VERSION "HNNBNNNYNNNNNNNNNNNNNNNNNNNNNNNNNNNNNNNNNN/4/%%%/4/'%**4NNN///"

NS_ :

BS_:

BU_: AFS AFS_LMod_L AFS_LMod_R BCM1 BVS FCM GLW_LMod_L GLW_LMod_R LCM_L LCM_R LED_DK3_LM_L LED_DK3_LM_R LED_LM_L LED_LM_R LLP_L LLP_R LWR_MXB_L LWR_MXB_R MXB MXB_LM_L MXB_LM_R ZFAS

BO_ 1342 LED_Feh_LM_L_01: 8 LED_LM_L
 SG_ LED_L_Abbiegel_Def_1 : 0|1@1+ (1,0) [0|1] ""  AFS,BCM1,FCM,MXB
 SG_ LED_L_Abbiegel_Def_2 : 1|1@1+ (1,0) [0|1] ""  AFS,BCM1,FCM,MXB
 SG_ LED_L_Abbiegel_Def_3 : 2|1@1+ (1,0) [0|1] ""  AFS,BCM1,FCM,MXB
 SG_ LED_L_Abbiegel_Def_4 : 3|1@1+ (1,0) [0|1] ""  AFS,BCM1,FCM,MXB
 SG_ LED_L_Abbiegel_Def_5 : 4|1@1+ (1,0) [0|1] ""  AFS,BCM1,FCM,MXB
 SG_ LED_L_Abbiegel_Def_6 : 5|1@1+ (1,0) [0|1] ""  AFS,BCM1,FCM,MXB
 SG_ LED_L_Abbiegel_Def_7 : 6|1@1+ (1,0) [0|1] ""  AFS,BCM1,FCM,MXB
 SG_ LED_L_Abbiegel_Def_Err_Gultig : 7|1@1+ (1,0) [0|1] ""  AFS,BCM1,FCM,MXB
 SG_ LED_L_Abblendl_Def_1 : 8|1@1+ (1,0) [0|1] ""  AFS,BCM1,FCM,MXB
 SG_ LED_L_Abblendl_Def_2 : 9|1@1+ (1,0) [0|1] ""  AFS,BCM1,FCM,MXB
 SG_ LED_L_Abblendl_Def_3 : 10|1@1+ (1,0) [0|1] ""  AFS,BCM1,FCM,MXB
 SG_ LED_L_Abblendl_Def_4 : 11|1@1+ (1,0) [0|1] ""  AFS,BCM1,FCM,MXB
 SG_ LED_L_Abblendl_Def_5 : 12|1@1+ (1,0) [0|1] ""  AFS,BCM1,FCM,MXB
 SG_ LED_L_Abblendl_Def_6 : 13|1@1+ (1,0) [0|1] ""  AFS,BCM1,FCM,MXB
 SG_ LED_L_Abblendl_Def_7 : 14|1@1+ (1,0) [0|1] ""  AFS,BCM1,FCM,MXB
 SG_ LED_L_Abblendl_Def_Err_Gultig : 15|1@1+ (1,0) [0|1] ""  AFS,BCM1,FCM,MXB
 SG_ LED_L_Fernl_Def_1 : 16|1@1+ (1,0) [0|1] ""  AFS,BCM1,FCM,MXB
 SG_ LED_L_Fernl_Def_2 : 17|1@1+ (1,0) [0|1] ""  AFS,BCM1,FCM,MXB
 SG_ LED_L_Fernl_Def_3 : 18|1@1+ (1,0) [0|1] ""  AFS,BCM1,FCM,MXB
 SG_ LED_L_Fernl_Def_4 : 19|1@1+ (1,0) [0|1] ""  AFS,BCM1,FCM,MXB
 SG_ LED_L_Fernl_Def_5 : 20|1@1+ (1,0) [0|1] ""  AFS,BCM1,FCM,MXB
 SG_ LED_L_Fernl_Def_6 : 21|1@1+ (1,0) [0|1] ""  AFS,BCM1,FCM,MXB
 SG_ LED_L_Fernl_Def_7 : 22|1@1+ (1,0) [0|1] ""  AFS,BCM1,FCM,MXB
 SG_ LED_L_Fernl_Def_Err_Gultig : 23|1@1+ (1,0) [0|1] ""  AFS,BCM1,FCM,MXB
 SG_ LED_L_TFL_Def_1 : 24|1@1+ (1,0) [0|1] ""  AFS,BCM1,FCM,MXB
 SG_ LED_L_TFL_Def_2 : 25|1@1+ (1,0) [0|1] ""  AFS,BCM1,FCM,MXB
 SG_ LED_L_TFL_Def_3 : 26|1@1+ (1,0) [0|1] ""  AFS,BCM1,FCM,MXB
 SG_ LED_L_TFL_Def_4 : 27|1@1+ (1,0) [0|1] ""  AFS,BCM1,FCM,MXB
 SG_ LED_L_TFL_Def_5 : 28|1@1+ (1,0) [0|1] ""  AFS,BCM1,FCM,MXB
 SG_ LED_L_TFL_Def_6 : 29|1@1+ (1,0) [0|1] ""  AFS,BCM1,FCM,MXB
 SG_ LED_L_TFL_Def_7 : 30|1@1+ (1,0) [0|1] ""  AFS,BCM1,FCM,MXB
 SG_ LED_L_TFL_Def_Err_Gultig : 31|1@1+ (1,0) [0|1] ""  AFS,BCM1,FCM,MXB
 SG_ LED_L_Allg_Elektr_Def_1 : 32|1@1+ (1,0) [0|1] ""  AFS,BCM1,FCM,MXB
 SG_ LED_L_Allg_Elektr_Def_2 : 33|1@1+ (1,0) [0|1] ""  AFS,BCM1,FCM,MXB
 SG_ LED_L_Allg_Elektr_Def_3 : 34|1@1+ (1,0) [0|1] ""  AFS,BCM1,FCM,MXB
 SG_ LED_L_Allg_Elektr_Def_4 : 35|1@1+ (1,0) [0|1] ""  AFS,BCM1,FCM,MXB
 SG_ LED_L_Allg_Elektr_Def_5 : 36|1@1+ (1,0) [0|1] ""  AFS,BCM1,FCM,MXB
 SG_ LED_L_Allg_Elektr_Def_6 : 37|1@1+ (1,0) [0|1] ""  AFS,BCM1,FCM,MXB
 SG_ LED_L_Allg_Elektr_Def_7 : 38|1@1+ (1,0) [0|1] ""  AFS,BCM1,FCM,MXB
 SG_ LED_L_Allg_Elektr_Def_8 : 39|1@1+ (1,0) [0|1] ""  AFS,BCM1,FCM,MXB
 SG_ LED_L_Allg_Elektr_Def_Err_Gultig : 40|1@1+ (1,0) [0|1] ""  AFS,BCM1,FCM,MXB
 SG_ LED_L_Luefter_1_Def_1 : 48|1@1+ (1,0) [0|1] ""  AFS,BCM1,FCM,MXB
 SG_ LED_L_Luefter_1_Def_2 : 49|1@1+ (1,0) [0|1] ""  AFS,BCM1,FCM,MXB
 SG_ LED_L_Luefter_1_Def_3 : 50|1@1+ (1,0) [0|1] ""  AFS,BCM1,FCM,MXB
 SG_ LED_L_Luefter_1_Def_4 : 51|1@1+ (1,0) [0|1] ""  AFS,BCM1,FCM,MXB
 SG_ LED_L_Luefter_2_Def_1 : 52|1@1+ (1,0) [0|1] ""  AFS,BCM1,FCM,MXB
 SG_ LED_L_Luefter_2_Def_2 : 53|1@1+ (1,0) [0|1] ""  AFS,BCM1,FCM,MXB
 SG_ LED_L_Luefter_2_Def_3 : 54|1@1+ (1,0) [0|1] ""  AFS,BCM1,FCM,MXB
 SG_ LED_L_Luefter_2_Def_4 : 55|1@1+ (1,0) [0|1] ""  AFS,BCM1,FCM,MXB
 SG_ LED_L_Luefter_1_Def_Err_Gultig : 56|1@1+ (1,0) [0|1] ""  AFS,BCM1,FCM,MXB
 SG_ LED_L_Luefter_2_Def_Err_Gultig : 57|1@1+ (1,0) [0|1] ""  AFS,BCM1,FCM,MXB
 SG_ LED_L_ECE_SAE_Umschaltung_Def : 63|1@1+ (1,0) [0|1] ""  AFS,BCM1,FCM,MXB

BO_ 2527679494 LED_Feh_LM_L_02: 8 LED_LM_L
 SG_ LED_L_Nebel_All_Def_1 : 0|1@1+ (1,0) [0|1] ""  AFS,BCM1,FCM,MXB
 SG_ LED_L_Nebel_All_Def_2 : 1|1@1+ (1,0) [0|1] ""  AFS,BCM1,FCM,MXB
 SG_ LED_L_Nebel_All_Def_3 : 2|1@1+ (1,0) [0|1] ""  AFS,BCM1,FCM,MXB
 SG_ LED_L_Nebel_All_Def_4 : 3|1@1+ (1,0) [0|1] ""  AFS,BCM1,FCM,MXB
 SG_ LED_L_Nebel_All_Def_5 : 4|1@1+ (1,0) [0|1] ""  AFS,BCM1,FCM,MXB
 SG_ LED_L_Nebel_All_Def_6 : 5|1@1+ (1,0) [0|1] ""  AFS,BCM1,FCM,MXB
 SG_ LED_L_Nebel_All_Def_7 : 6|1@1+ (1,0) [0|1] ""  AFS,BCM1,FCM,MXB
 SG_ LED_L_Nebel_All_Def_Err_Gultig : 7|1@1+ (1,0) [0|1] ""  AFS,BCM1,FCM,MXB
 SG_ LED_L_Touristenl_Def_1 : 8|1@1+ (1,0) [0|1] ""  AFS,BCM1,FCM,MXB
 SG_ LED_L_Touristenl_Def_2 : 9|1@1+ (1,0) [0|1] ""  AFS,BCM1,FCM,MXB
 SG_ LED_L_Touristenl_Def_3 : 10|1@1+ (1,0) [0|1] ""  AFS,BCM1,FCM,MXB
 SG_ LED_L_Touristenl_Def_4 : 11|1@1+ (1,0) [0|1] ""  AFS,BCM1,FCM,MXB
 SG_ LED_L_Touristenl_Def_5 : 12|1@1+ (1,0) [0|1] ""  AFS,BCM1,FCM,MXB
 SG_ LED_L_Touristenl_Def_6 : 13|1@1+ (1,0) [0|1] ""  AFS,BCM1,FCM,MXB
 SG_ LED_L_Touristenl_Def_7 : 14|1@1+ (1,0) [0|1] ""  AFS,BCM1,FCM,MXB
 SG_ LED_L_Touristenl_Def_Err_Gultig : 15|1@1+ (1,0) [0|1] ""  AFS,BCM1,FCM,MXB
 SG_ LED_L_Autobahnl_Def_1 : 16|1@1+ (1,0) [0|1] ""  AFS,BCM1,FCM,MXB
 SG_ LED_L_Autobahnl_Def_2 : 17|1@1+ (1,0) [0|1] ""  AFS,BCM1,FCM,MXB
 SG_ LED_L_Autobahnl_Def_3 : 18|1@1+ (1,0) [0|1] ""  AFS,BCM1,FCM,MXB
 SG_ LED_L_Autobahnl_Def_4 : 19|1@1+ (1,0) [0|1] ""  AFS,BCM1,FCM,MXB
 SG_ LED_L_Autobahnl_Def_5 : 20|1@1+ (1,0) [0|1] ""  AFS,BCM1,FCM,MXB
 SG_ LED_L_Autobahnl_Def_6 : 21|1@1+ (1,0) [0|1] ""  AFS,BCM1,FCM,MXB
 SG_ LED_L_Autobahnl_Def_7 : 22|1@1+ (1,0) [0|1] ""  AFS,BCM1,FCM,MXB
 SG_ LED_L_Autobahnl_Def_Err_Gultig : 23|1@1+ (1,0) [0|1] ""  AFS,BCM1,FCM,MXB
 SG_ LED_L_Rennl_Def_1 : 24|1@1+ (1,0) [0|1] ""  AFS,BCM1,FCM,MXB
 SG_ LED_L_Rennl_Def_2 : 25|1@1+ (1,0) [0|1] ""  AFS,BCM1,FCM,MXB
 SG_ LED_L_Rennl_Def_3 : 26|1@1+ (1,0) [0|1] ""  AFS,BCM1,FCM,MXB
 SG_ LED_L_Rennl_Def_4 : 27|1@1+ (1,0) [0|1] ""  AFS,BCM1,FCM,MXB
 SG_ LED_L_Rennl_Def_5 : 28|1@1+ (1,0) [0|1] ""  AFS,BCM1,FCM,MXB
 SG_ LED_L_Rennl_Def_6 : 29|1@1+ (1,0) [0|1] ""  AFS,BCM1,FCM,MXB
 SG_ LED_L_Rennl_Def_7 : 30|1@1+ (1,0) [0|1] ""  AFS,BCM1,FCM,MXB
 SG_ LED_L_Rennl_Def_Err_Gultig : 31|1@1+ (1,0) [0|1] ""  AFS,BCM1,FCM,MXB
 SG_ LED_L_Stadtl_Def_1 : 32|1@1+ (1,0) [0|1] ""  AFS,BCM1,FCM,MXB
 SG_ LED_L_Stadtl_Def_2 : 33|1@1+ (1,0) [0|1] ""  AFS,BCM1,FCM,MXB
 SG_ LED_L_Stadtl_Def_3 : 34|1@1+ (1,0) [0|1] ""  AFS,BCM1,FCM,MXB
 SG_ LED_L_Stadtl_Def_4 : 35|1@1+ (1,0) [0|1] ""  AFS,BCM1,FCM,MXB
 SG_ LED_L_Stadtl_Def_5 : 36|1@1+ (1,0) [0|1] ""  AFS,BCM1,FCM,MXB
 SG_ LED_L_Stadtl_Def_6 : 37|1@1+ (1,0) [0|1] ""  AFS,BCM1,FCM,MXB
 SG_ LED_L_Stadtl_Def_7 : 38|1@1+ (1,0) [0|1] ""  AFS,BCM1,FCM,MXB
 SG_ LED_L_Stadtl_Def_Err_Gultig : 39|1@1+ (1,0) [0|1] ""  AFS,BCM1,FCM,MXB

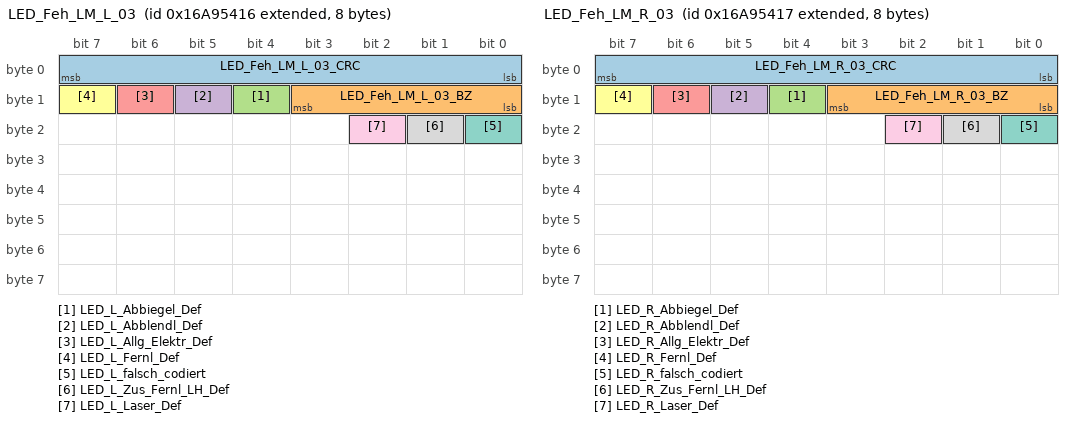
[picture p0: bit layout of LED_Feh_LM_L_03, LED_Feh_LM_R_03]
BO_ 2527679510 LED_Feh_LM_L_03: 8 LED_DK3_LM_L
 SG_ LED_Feh_LM_L_03_CRC : 0|8@1+ (1,0) [0|255] "" Vector__XXX
 SG_ LED_Feh_LM_L_03_BZ : 8|4@1+ (1,0) [0|15] "" Vector__XXX
 SG_ LED_L_Abbiegel_Def : 12|1@1+ (1,0) [0|1] ""  AFS,BCM1,FCM,MXB
 SG_ LED_L_Abblendl_Def : 13|1@1+ (1,0) [0|1] ""  AFS,BCM1,FCM,LCM_L,MXB
 SG_ LED_L_Allg_Elektr_Def : 14|1@1+ (1,0) [0|1] ""  AFS,BCM1,FCM,MXB
 SG_ LED_L_Fernl_Def : 15|1@1+ (1,0) [0|1] ""  AFS,BCM1,FCM,MXB
 SG_ LED_L_falsch_codiert : 16|1@1+ (1,0) [0|1] ""  AFS,BCM1,BVS,FCM,MXB,ZFAS
 SG_ LED_L_Zus_Fernl_LH_Def : 17|1@1+ (1,0) [0|1] ""  AFS,BCM1,FCM
 SG_ LED_L_Laser_Def : 18|1@1+ (1,0) [0|1] ""  AFS,BCM1,FCM

BO_ 1341 LED_Feh_LM_R_01: 8 LED_LM_R
 SG_ LED_R_Abbiegel_Def_1 : 0|1@1+ (1,0) [0|1] ""  AFS,BCM1,FCM,MXB
 SG_ LED_R_Abbiegel_Def_2 : 1|1@1+ (1,0) [0|1] ""  AFS,BCM1,FCM,MXB
 SG_ LED_R_Abbiegel_Def_3 : 2|1@1+ (1,0) [0|1] ""  AFS,BCM1,FCM,MXB
 SG_ LED_R_Abbiegel_Def_4 : 3|1@1+ (1,0) [0|1] ""  AFS,BCM1,FCM,MXB
 SG_ LED_R_Abbiegel_Def_5 : 4|1@1+ (1,0) [0|1] ""  AFS,BCM1,FCM,MXB
 SG_ LED_R_Abbiegel_Def_6 : 5|1@1+ (1,0) [0|1] ""  AFS,BCM1,FCM,MXB
 SG_ LED_R_Abbiegel_Def_7 : 6|1@1+ (1,0) [0|1] ""  AFS,BCM1,FCM,MXB
 SG_ LED_R_Abbiegel_Def_Err_Gultig : 7|1@1+ (1,0) [0|1] ""  AFS,BCM1,FCM,MXB
 SG_ LED_R_Abblendl_Def_1 : 8|1@1+ (1,0) [0|1] ""  AFS,BCM1,FCM,MXB
 SG_ LED_R_Abblendl_Def_2 : 9|1@1+ (1,0) [0|1] ""  AFS,BCM1,FCM,MXB
 SG_ LED_R_Abblendl_Def_3 : 10|1@1+ (1,0) [0|1] ""  AFS,BCM1,FCM,MXB
 SG_ LED_R_Abblendl_Def_4 : 11|1@1+ (1,0) [0|1] ""  AFS,BCM1,FCM,MXB
 SG_ LED_R_Abblendl_Def_5 : 12|1@1+ (1,0) [0|1] ""  AFS,BCM1,FCM,MXB
 SG_ LED_R_Abblendl_Def_6 : 13|1@1+ (1,0) [0|1] ""  AFS,BCM1,FCM,MXB
 SG_ LED_R_Abblendl_Def_7 : 14|1@1+ (1,0) [0|1] ""  AFS,BCM1,FCM,MXB
 SG_ LED_R_Abblendl_Def_Err_Gultig : 15|1@1+ (1,0) [0|1] ""  AFS,BCM1,FCM,MXB
 SG_ LED_R_Fernl_Def_1 : 16|1@1+ (1,0) [0|1] ""  AFS,BCM1,FCM,MXB
 SG_ LED_R_Fernl_Def_2 : 17|1@1+ (1,0) [0|1] ""  AFS,BCM1,FCM,MXB
 SG_ LED_R_Fernl_Def_3 : 18|1@1+ (1,0) [0|1] ""  AFS,BCM1,FCM,MXB
 SG_ LED_R_Fernl_Def_4 : 19|1@1+ (1,0) [0|1] ""  AFS,BCM1,FCM,MXB
 SG_ LED_R_Fernl_Def_5 : 20|1@1+ (1,0) [0|1] ""  AFS,BCM1,FCM,MXB
 SG_ LED_R_Fernl_Def_6 : 21|1@1+ (1,0) [0|1] ""  AFS,BCM1,FCM,MXB
 SG_ LED_R_Fernl_Def_7 : 22|1@1+ (1,0) [0|1] ""  AFS,BCM1,FCM,MXB
 SG_ LED_R_Fernl_Def_Err_Gultig : 23|1@1+ (1,0) [0|1] ""  AFS,BCM1,FCM,MXB
 SG_ LED_R_TFL_Def_1 : 24|1@1+ (1,0) [0|1] ""  AFS,BCM1,FCM,MXB
 SG_ LED_R_TFL_Def_2 : 25|1@1+ (1,0) [0|1] ""  AFS,BCM1,FCM,MXB
 SG_ LED_R_TFL_Def_3 : 26|1@1+ (1,0) [0|1] ""  AFS,BCM1,FCM,MXB
 SG_ LED_R_TFL_Def_4 : 27|1@1+ (1,0) [0|1] ""  AFS,BCM1,FCM,MXB
 SG_ LED_R_TFL_Def_5 : 28|1@1+ (1,0) [0|1] ""  AFS,BCM1,FCM,MXB
 SG_ LED_R_TFL_Def_6 : 29|1@1+ (1,0) [0|1] ""  AFS,BCM1,FCM,MXB
 SG_ LED_R_TFL_Def_7 : 30|1@1+ (1,0) [0|1] ""  AFS,BCM1,FCM,MXB
 SG_ LED_R_TFL_Def_Err_Gultig : 31|1@1+ (1,0) [0|1] ""  AFS,BCM1,FCM,MXB
 SG_ LED_R_Allg_Elektr_Def_1 : 32|1@1+ (1,0) [0|1] ""  AFS,BCM1,FCM,MXB
 SG_ LED_R_Allg_Elektr_Def_2 : 33|1@1+ (1,0) [0|1] ""  AFS,BCM1,FCM,MXB
 SG_ LED_R_Allg_Elektr_Def_3 : 34|1@1+ (1,0) [0|1] ""  AFS,BCM1,FCM,MXB
 SG_ LED_R_Allg_Elektr_Def_4 : 35|1@1+ (1,0) [0|1] ""  AFS,BCM1,FCM,MXB
 SG_ LED_R_Allg_Elektr_Def_5 : 36|1@1+ (1,0) [0|1] ""  AFS,BCM1,FCM,MXB
 SG_ LED_R_Allg_Elektr_Def_6 : 37|1@1+ (1,0) [0|1] ""  AFS,BCM1,FCM,MXB
 SG_ LED_R_Allg_Elektr_Def_7 : 38|1@1+ (1,0) [0|1] ""  AFS,BCM1,FCM,MXB
 SG_ LED_R_Allg_Elektr_Def_8 : 39|1@1+ (1,0) [0|1] ""  AFS,BCM1,FCM,MXB
 SG_ LED_R_Allg_Elektr_Def_Err_Gultig : 40|1@1+ (1,0) [0|1] ""  AFS,BCM1,FCM,MXB
 SG_ LED_R_Luefter_1_Def_1 : 48|1@1+ (1,0) [0|1] ""  AFS,BCM1,FCM,MXB
 SG_ LED_R_Luefter_1_Def_2 : 49|1@1+ (1,0) [0|1] ""  AFS,BCM1,FCM,MXB
 SG_ LED_R_Luefter_1_Def_3 : 50|1@1+ (1,0) [0|1] ""  AFS,BCM1,FCM,MXB
 SG_ LED_R_Luefter_1_Def_4 : 51|1@1+ (1,0) [0|1] ""  AFS,BCM1,FCM,MXB
 SG_ LED_R_Luefter_2_Def_1 : 52|1@1+ (1,0) [0|1] ""  AFS,BCM1,FCM,MXB
 SG_ LED_R_Luefter_2_Def_2 : 53|1@1+ (1,0) [0|1] ""  AFS,BCM1,FCM,MXB
 SG_ LED_R_Luefter_2_Def_3 : 54|1@1+ (1,0) [0|1] ""  AFS,BCM1,FCM,MXB
 SG_ LED_R_Luefter_2_Def_4 : 55|1@1+ (1,0) [0|1] ""  AFS,BCM1,FCM,MXB
 SG_ LED_R_Luefter_1_Def_Err_Gultig : 56|1@1+ (1,0) [0|1] ""  AFS,BCM1,FCM,MXB
 SG_ LED_R_Luefter_2_Def_Err_Gultig : 57|1@1+ (1,0) [0|1] ""  AFS,BCM1,FCM,MXB
 SG_ LED_R_ECE_SAE_Umschaltung_Def : 63|1@1+ (1,0) [0|1] ""  AFS,BCM1,FCM,MXB

BO_ 2527679495 LED_Feh_LM_R_02: 8 LED_LM_R
 SG_ LED_R_Nebel_All_Def_1 : 0|1@1+ (1,0) [0|1] ""  AFS,BCM1,FCM,MXB
 SG_ LED_R_Nebel_All_Def_2 : 1|1@1+ (1,0) [0|1] ""  AFS,BCM1,FCM,MXB
 SG_ LED_R_Nebel_All_Def_3 : 2|1@1+ (1,0) [0|1] ""  AFS,BCM1,FCM,MXB
 SG_ LED_R_Nebel_All_Def_4 : 3|1@1+ (1,0) [0|1] ""  AFS,BCM1,FCM,MXB
 SG_ LED_R_Nebel_All_Def_5 : 4|1@1+ (1,0) [0|1] ""  AFS,BCM1,FCM,MXB
 SG_ LED_R_Nebel_All_Def_6 : 5|1@1+ (1,0) [0|1] ""  AFS,BCM1,FCM,MXB
 SG_ LED_R_Nebel_All_Def_7 : 6|1@1+ (1,0) [0|1] ""  AFS,BCM1,FCM,MXB
 SG_ LED_R_Nebel_All_Def_Err_Gultig : 7|1@1+ (1,0) [0|1] ""  AFS,BCM1,FCM,MXB
 SG_ LED_R_Touristenl_Def_1 : 8|1@1+ (1,0) [0|1] ""  AFS,BCM1,FCM,MXB
 SG_ LED_R_Touristenl_Def_2 : 9|1@1+ (1,0) [0|1] ""  AFS,BCM1,FCM,MXB
 SG_ LED_R_Touristenl_Def_3 : 10|1@1+ (1,0) [0|1] ""  AFS,BCM1,FCM,MXB
 SG_ LED_R_Touristenl_Def_4 : 11|1@1+ (1,0) [0|1] ""  AFS,BCM1,FCM,MXB
 SG_ LED_R_Touristenl_Def_5 : 12|1@1+ (1,0) [0|1] ""  AFS,BCM1,FCM,MXB
 SG_ LED_R_Touristenl_Def_6 : 13|1@1+ (1,0) [0|1] ""  AFS,BCM1,FCM,MXB
 SG_ LED_R_Touristenl_Def_7 : 14|1@1+ (1,0) [0|1] ""  AFS,BCM1,FCM,MXB
 SG_ LED_R_Touristenl_Def_Err_Gultig : 15|1@1+ (1,0) [0|1] ""  AFS,BCM1,FCM,MXB
 SG_ LED_R_Autobahnl_Def_1 : 16|1@1+ (1,0) [0|1] ""  AFS,BCM1,FCM,MXB
 SG_ LED_R_Autobahnl_Def_2 : 17|1@1+ (1,0) [0|1] ""  AFS,BCM1,FCM,MXB
 SG_ LED_R_Autobahnl_Def_3 : 18|1@1+ (1,0) [0|1] ""  AFS,BCM1,FCM,MXB
 SG_ LED_R_Autobahnl_Def_4 : 19|1@1+ (1,0) [0|1] ""  AFS,BCM1,FCM,MXB
 SG_ LED_R_Autobahnl_Def_5 : 20|1@1+ (1,0) [0|1] ""  AFS,BCM1,FCM,MXB
 SG_ LED_R_Autobahnl_Def_6 : 21|1@1+ (1,0) [0|1] ""  AFS,BCM1,FCM,MXB
 SG_ LED_R_Autobahnl_Def_7 : 22|1@1+ (1,0) [0|1] ""  AFS,BCM1,FCM,MXB
 SG_ LED_R_Autobahnl_Def_Err_Gultig : 23|1@1+ (1,0) [0|1] ""  AFS,BCM1,FCM,MXB
 SG_ LED_R_Rennl_Def_1 : 24|1@1+ (1,0) [0|1] ""  AFS,BCM1,FCM,MXB
 SG_ LED_R_Rennl_Def_2 : 25|1@1+ (1,0) [0|1] ""  AFS,BCM1,FCM,MXB
 SG_ LED_R_Rennl_Def_3 : 26|1@1+ (1,0) [0|1] ""  AFS,BCM1,FCM,MXB
 SG_ LED_R_Rennl_Def_4 : 27|1@1+ (1,0) [0|1] ""  AFS,BCM1,FCM,MXB
 SG_ LED_R_Rennl_Def_5 : 28|1@1+ (1,0) [0|1] ""  AFS,BCM1,FCM,MXB
 SG_ LED_R_Rennl_Def_6 : 29|1@1+ (1,0) [0|1] ""  AFS,BCM1,FCM,MXB
 SG_ LED_R_Rennl_Def_7 : 30|1@1+ (1,0) [0|1] ""  AFS,BCM1,FCM,MXB
 SG_ LED_R_Rennl_Def_Err_Gultig : 31|1@1+ (1,0) [0|1] ""  AFS,BCM1,FCM,MXB
 SG_ LED_R_Stadtl_Def_1 : 32|1@1+ (1,0) [0|1] ""  AFS,BCM1,FCM,MXB
 SG_ LED_R_Stadtl_Def_2 : 33|1@1+ (1,0) [0|1] ""  AFS,BCM1,FCM,MXB
 SG_ LED_R_Stadtl_Def_3 : 34|1@1+ (1,0) [0|1] ""  AFS,BCM1,FCM,MXB
 SG_ LED_R_Stadtl_Def_4 : 35|1@1+ (1,0) [0|1] ""  AFS,BCM1,FCM,MXB
 SG_ LED_R_Stadtl_Def_5 : 36|1@1+ (1,0) [0|1] ""  AFS,BCM1,FCM,MXB
 SG_ LED_R_Stadtl_Def_6 : 37|1@1+ (1,0) [0|1] ""  AFS,BCM1,FCM,MXB
 SG_ LED_R_Stadtl_Def_7 : 38|1@1+ (1,0) [0|1] ""  AFS,BCM1,FCM,MXB
 SG_ LED_R_Stadtl_Def_Err_Gultig : 39|1@1+ (1,0) [0|1] ""  AFS,BCM1,FCM,MXB

BO_ 2527679511 LED_Feh_LM_R_03: 8 LED_DK3_LM_R
 SG_ LED_Feh_LM_R_03_CRC : 0|8@1+ (1,0) [0|255] "" Vector__XXX
 SG_ LED_Feh_LM_R_03_BZ : 8|4@1+ (1,0) [0|15] "" Vector__XXX
 SG_ LED_R_Abbiegel_Def : 12|1@1+ (1,0) [0|1] ""  AFS,BCM1,FCM,MXB
 SG_ LED_R_Abblendl_Def : 13|1@1+ (1,0) [0|1] ""  AFS,BCM1,FCM,LCM_R,MXB
 SG_ LED_R_Allg_Elektr_Def : 14|1@1+ (1,0) [0|1] ""  AFS,BCM1,FCM,MXB
 SG_ LED_R_Fernl_Def : 15|1@1+ (1,0) [0|1] ""  AFS,BCM1,FCM,MXB
 SG_ LED_R_falsch_codiert : 16|1@1+ (1,0) [0|1] ""  AFS,BCM1,BVS,FCM,MXB,ZFAS
 SG_ LED_R_Zus_Fernl_LH_Def : 17|1@1+ (1,0) [0|1] ""  AFS,BCM1,FCM
 SG_ LED_R_Laser_Def : 18|1@1+ (1,0) [0|1] ""  AFS,BCM1,FCM

BO_ 1422 LED_Idt_LM_L: 8 LED_LM_L
 SG_ LED_L_Mux M : 0|8@1+ (1,0) [0|4] ""  AFS,BCM1,FCM,MXB
 SG_ LED_L_SW_Idt_Z01 m0 : 8|8@1+ (1,0) [0|255] ""  AFS,BCM1,FCM,MXB
 SG_ LED_L_SW_Idt_Z08 m1 : 8|8@1+ (1,0) [0|255] ""  AFS,BCM1,FCM,MXB
 SG_ LED_L_SW_Idx_Z04 m2 : 8|8@1+ (1,0) [0|255] ""  AFS,BCM1,FCM,MXB
 SG_ LED_L_HW_Idt_Z07 m3 : 8|8@1+ (1,0) [0|255] ""  AFS,BCM1,FCM,MXB
 SG_ LED_L_HW_Idx_Z03 m4 : 8|8@1+ (1,0) [0|255] ""  AFS,BCM1,FCM,MXB
 SG_ LED_L_SW_Idt_Z02 m0 : 16|8@1+ (1,0) [0|255] ""  AFS,BCM1,FCM,MXB
 SG_ LED_L_SW_Idt_Z09 m1 : 16|8@1+ (1,0) [0|255] ""  AFS,BCM1,FCM,MXB
 SG_ LED_L_HW_Idt_Z01 m2 : 16|8@1+ (1,0) [0|255] ""  AFS,BCM1,FCM,MXB
 SG_ LED_L_HW_Idt_Z08 m3 : 16|8@1+ (1,0) [0|255] ""  AFS,BCM1,FCM,MXB
 SG_ LED_L_SW_Idt_Z03 m0 : 24|8@1+ (1,0) [0|255] ""  AFS,BCM1,FCM,MXB
 SG_ LED_L_SW_Idt_Z10 m1 : 24|8@1+ (1,0) [0|255] ""  AFS,BCM1,FCM,MXB
 SG_ LED_L_HW_Idt_Z02 m2 : 24|8@1+ (1,0) [0|255] ""  AFS,BCM1,FCM,MXB
 SG_ LED_L_HW_Idt_Z09 m3 : 24|8@1+ (1,0) [0|255] ""  AFS,BCM1,FCM,MXB
 SG_ LED_L_SW_Idt_Z04 m0 : 32|8@1+ (1,0) [0|255] ""  AFS,BCM1,FCM,MXB
 SG_ LED_L_SW_Idt_Z11 m1 : 32|8@1+ (1,0) [0|255] ""  AFS,BCM1,FCM,MXB
 SG_ LED_L_HW_Idt_Z03 m2 : 32|8@1+ (1,0) [0|255] ""  AFS,BCM1,FCM,MXB
 SG_ LED_L_HW_Idt_Z10 m3 : 32|8@1+ (1,0) [0|255] ""  AFS,BCM1,FCM,MXB
 SG_ LED_L_SW_Idt_Z05 m0 : 40|8@1+ (1,0) [0|255] ""  AFS,BCM1,FCM,MXB
 SG_ LED_L_SW_Idx_Z01 m1 : 40|8@1+ (1,0) [0|255] ""  AFS,BCM1,FCM,MXB
 SG_ LED_L_HW_Idt_Z04 m2 : 40|8@1+ (1,0) [0|255] ""  AFS,BCM1,FCM,MXB
 SG_ LED_L_HW_Idt_Z11 m3 : 40|8@1+ (1,0) [0|255] ""  AFS,BCM1,FCM,MXB
 SG_ LED_L_SW_Idt_Z06 m0 : 48|8@1+ (1,0) [0|255] ""  AFS,BCM1,FCM,MXB
 SG_ LED_L_SW_Idx_Z02 m1 : 48|8@1+ (1,0) [0|255] ""  AFS,BCM1,FCM,MXB
 SG_ LED_L_HW_Idt_Z05 m2 : 48|8@1+ (1,0) [0|255] ""  AFS,BCM1,FCM,MXB
 SG_ LED_L_HW_Idx_Z01 m3 : 48|8@1+ (1,0) [0|255] ""  AFS,BCM1,FCM,MXB
 SG_ LED_L_SW_Idt_Z07 m0 : 56|8@1+ (1,0) [0|255] ""  AFS,BCM1,FCM,MXB
 SG_ LED_L_SW_Idx_Z03 m1 : 56|8@1+ (1,0) [0|255] ""  AFS,BCM1,FCM,MXB
 SG_ LED_L_HW_Idt_Z06 m2 : 56|8@1+ (1,0) [0|255] ""  AFS,BCM1,FCM,MXB
 SG_ LED_L_HW_Idx_Z02 m3 : 56|8@1+ (1,0) [0|255] ""  AFS,BCM1,FCM,MXB

BO_ 1421 LED_Idt_LM_R: 8 LED_LM_R
 SG_ LED_R_Mux M : 0|8@1+ (1,0) [0|4] ""  AFS,BCM1,FCM,MXB
 SG_ LED_R_SW_Idt_Z01 m0 : 8|8@1+ (1,0) [0|255] ""  AFS,BCM1,FCM,MXB
 SG_ LED_R_SW_Idt_Z08 m1 : 8|8@1+ (1,0) [0|255] ""  AFS,BCM1,FCM,MXB
 SG_ LED_R_SW_Idx_Z04 m2 : 8|8@1+ (1,0) [0|255] ""  AFS,BCM1,FCM,MXB
 SG_ LED_R_HW_Idt_Z07 m3 : 8|8@1+ (1,0) [0|255] ""  AFS,BCM1,FCM,MXB
 SG_ LED_R_HW_Idx_Z03 m4 : 8|8@1+ (1,0) [0|255] ""  AFS,BCM1,FCM,MXB
 SG_ LED_R_SW_Idt_Z02 m0 : 16|8@1+ (1,0) [0|255] ""  AFS,BCM1,FCM,MXB
 SG_ LED_R_SW_Idt_Z09 m1 : 16|8@1+ (1,0) [0|255] ""  AFS,BCM1,FCM,MXB
 SG_ LED_R_HW_Idt_Z01 m2 : 16|8@1+ (1,0) [0|255] ""  AFS,BCM1,FCM,MXB
 SG_ LED_R_HW_Idt_Z08 m3 : 16|8@1+ (1,0) [0|255] ""  AFS,BCM1,FCM,MXB
 SG_ LED_R_SW_Idt_Z03 m0 : 24|8@1+ (1,0) [0|255] ""  AFS,BCM1,FCM,MXB
 SG_ LED_R_SW_Idt_Z10 m1 : 24|8@1+ (1,0) [0|255] ""  AFS,BCM1,FCM,MXB
 SG_ LED_R_HW_Idt_Z02 m2 : 24|8@1+ (1,0) [0|255] ""  AFS,BCM1,FCM,MXB
 SG_ LED_R_HW_Idt_Z09 m3 : 24|8@1+ (1,0) [0|255] ""  AFS,BCM1,FCM,MXB
 SG_ LED_R_SW_Idt_Z04 m0 : 32|8@1+ (1,0) [0|255] ""  AFS,BCM1,FCM,MXB
 SG_ LED_R_SW_Idt_Z11 m1 : 32|8@1+ (1,0) [0|255] ""  AFS,BCM1,FCM,MXB
 SG_ LED_R_HW_Idt_Z03 m2 : 32|8@1+ (1,0) [0|255] ""  AFS,BCM1,FCM,MXB
 SG_ LED_R_HW_Idt_Z10 m3 : 32|8@1+ (1,0) [0|255] ""  AFS,BCM1,FCM,MXB
 SG_ LED_R_SW_Idt_Z05 m0 : 40|8@1+ (1,0) [0|255] ""  AFS,BCM1,FCM,MXB
 SG_ LED_R_SW_Idx_Z01 m1 : 40|8@1+ (1,0) [0|255] ""  AFS,BCM1,FCM,MXB
 SG_ LED_R_HW_Idt_Z04 m2 : 40|8@1+ (1,0) [0|255] ""  AFS,BCM1,FCM,MXB
 SG_ LED_R_HW_Idt_Z11 m3 : 40|8@1+ (1,0) [0|255] ""  AFS,BCM1,FCM,MXB
 SG_ LED_R_SW_Idt_Z06 m0 : 48|8@1+ (1,0) [0|255] ""  AFS,BCM1,FCM,MXB
 SG_ LED_R_SW_Idx_Z02 m1 : 48|8@1+ (1,0) [0|255] ""  AFS,BCM1,FCM,MXB
 SG_ LED_R_HW_Idt_Z05 m2 : 48|8@1+ (1,0) [0|255] ""  AFS,BCM1,FCM,MXB
 SG_ LED_R_HW_Idx_Z01 m3 : 48|8@1+ (1,0) [0|255] ""  AFS,BCM1,FCM,MXB
 SG_ LED_R_SW_Idt_Z07 m0 : 56|8@1+ (1,0) [0|255] ""  AFS,BCM1,FCM,MXB
 SG_ LED_R_SW_Idx_Z03 m1 : 56|8@1+ (1,0) [0|255] ""  AFS,BCM1,FCM,MXB
 SG_ LED_R_HW_Idt_Z06 m2 : 56|8@1+ (1,0) [0|255] ""  AFS,BCM1,FCM,MXB
 SG_ LED_R_HW_Idx_Z02 m3 : 56|8@1+ (1,0) [0|255] ""  AFS,BCM1,FCM,MXB

BO_ 1290 LED_Ken_LM_L: 8 LED_LM_L
 SG_ LED_L_Scheinw_Var_1 : 12|8@1+ (1,0) [0|255] ""  AFS,BCM1,FCM,MXB
 SG_ LED_L_Scheinw_Var_2 : 20|8@1+ (1,0) [0|255] ""  AFS,BCM1,FCM,MXB

BO_ 1291 LED_Ken_LM_R: 8 LED_LM_R
 SG_ LED_R_Scheinw_Var_1 : 12|8@1+ (1,0) [0|255] ""  AFS,BCM1,FCM,MXB
 SG_ LED_R_Scheinw_Var_2 : 20|8@1+ (1,0) [0|255] ""  AFS,BCM1,FCM,MXB

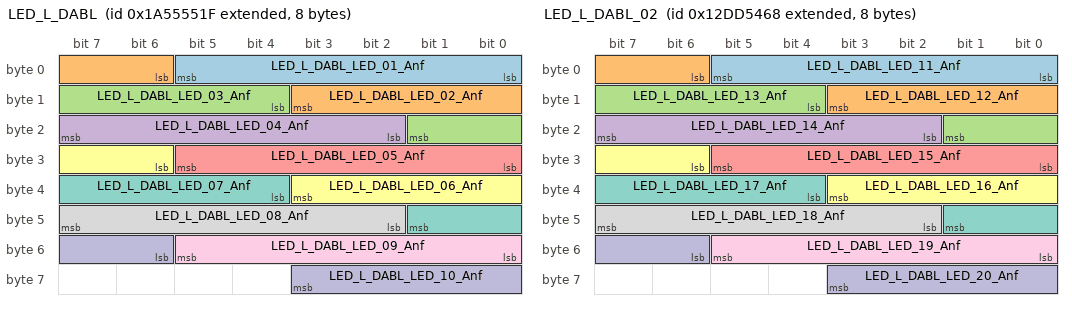
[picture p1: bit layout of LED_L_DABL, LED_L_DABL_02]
BO_ 2589283615 LED_L_DABL: 8 ZFAS
 SG_ LED_L_DABL_LED_01_Anf : 0|6@1+ (1.6,0) [0|100.8] "Unit_PerCent"  LED_DK3_LM_L,LLP_L
 SG_ LED_L_DABL_LED_02_Anf : 6|6@1+ (1.6,0) [0|100.8] "Unit_PerCent"  LED_DK3_LM_L,LLP_L
 SG_ LED_L_DABL_LED_03_Anf : 12|6@1+ (1.6,0) [0|100.8] "Unit_PerCent"  LED_DK3_LM_L,LLP_L
 SG_ LED_L_DABL_LED_04_Anf : 18|6@1+ (1.6,0) [0|100.8] "Unit_PerCent"  LED_DK3_LM_L,LLP_L
 SG_ LED_L_DABL_LED_05_Anf : 24|6@1+ (1.6,0) [0|100.8] "Unit_PerCent"  LED_DK3_LM_L,LLP_L
 SG_ LED_L_DABL_LED_06_Anf : 30|6@1+ (1.6,0) [0|100.8] "Unit_PerCent"  LED_DK3_LM_L,LLP_L
 SG_ LED_L_DABL_LED_07_Anf : 36|6@1+ (1.6,0) [0|100.8] "Unit_PerCent"  LED_DK3_LM_L,LLP_L
 SG_ LED_L_DABL_LED_08_Anf : 42|6@1+ (1.6,0) [0|100.8] "Unit_PerCent"  LED_DK3_LM_L,LLP_L
 SG_ LED_L_DABL_LED_09_Anf : 48|6@1+ (1.6,0) [0|100.8] "Unit_PerCent"  LED_DK3_LM_L,LLP_L
 SG_ LED_L_DABL_LED_10_Anf : 54|6@1+ (1.6,0) [0|100.8] "Unit_PerCent"  LED_DK3_LM_L,LLP_L

BO_ 2463978600 LED_L_DABL_02: 8 ZFAS
 SG_ LED_L_DABL_LED_11_Anf : 0|6@1+ (1.6,0) [0|100.8] "Unit_PerCent"  LED_DK3_LM_L,LLP_L
 SG_ LED_L_DABL_LED_12_Anf : 6|6@1+ (1.6,0) [0|100.8] "Unit_PerCent"  LED_DK3_LM_L,LLP_L
 SG_ LED_L_DABL_LED_13_Anf : 12|6@1+ (1.6,0) [0|100.8] "Unit_PerCent"  LED_DK3_LM_L,LLP_L
 SG_ LED_L_DABL_LED_14_Anf : 18|6@1+ (1.6,0) [0|100.8] "Unit_PerCent"  LED_DK3_LM_L,LLP_L
 SG_ LED_L_DABL_LED_15_Anf : 24|6@1+ (1.6,0) [0|100.8] "Unit_PerCent"  LED_DK3_LM_L,LLP_L
 SG_ LED_L_DABL_LED_16_Anf : 30|6@1+ (1.6,0) [0|100.8] "Unit_PerCent"  LED_DK3_LM_L,LLP_L
 SG_ LED_L_DABL_LED_17_Anf : 36|6@1+ (1.6,0) [0|100.8] "Unit_PerCent"  LED_DK3_LM_L,LLP_L
 SG_ LED_L_DABL_LED_18_Anf : 42|6@1+ (1.6,0) [0|100.8] "Unit_PerCent"  LED_DK3_LM_L,LLP_L
 SG_ LED_L_DABL_LED_19_Anf : 48|6@1+ (1.6,0) [0|100.8] "Unit_PerCent"  LED_DK3_LM_L,LLP_L
 SG_ LED_L_DABL_LED_20_Anf : 54|6@1+ (1.6,0) [0|100.8] "Unit_PerCent"  LED_DK3_LM_L,LLP_L

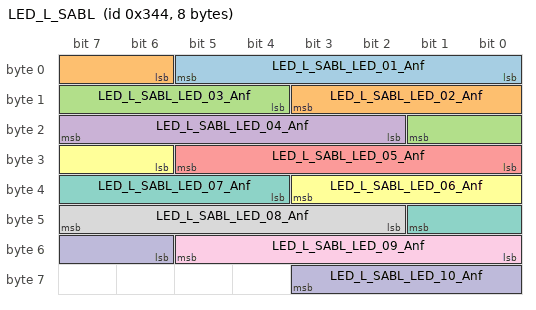
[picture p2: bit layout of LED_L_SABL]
BO_ 836 LED_L_SABL: 8 BCM1
 SG_ LED_L_SABL_LED_01_Anf : 0|6@1+ (1.6,0) [0|100.8] "Unit_PerCent"  LED_DK3_LM_L,LLP_L
 SG_ LED_L_SABL_LED_02_Anf : 6|6@1+ (1.6,0) [0|100.8] "Unit_PerCent"  LED_DK3_LM_L,LLP_L
 SG_ LED_L_SABL_LED_03_Anf : 12|6@1+ (1.6,0) [0|100.8] "Unit_PerCent"  LED_DK3_LM_L,LLP_L
 SG_ LED_L_SABL_LED_04_Anf : 18|6@1+ (1.6,0) [0|100.8] "Unit_PerCent"  LED_DK3_LM_L,LLP_L
 SG_ LED_L_SABL_LED_05_Anf : 24|6@1+ (1.6,0) [0|100.8] "Unit_PerCent"  LED_DK3_LM_L,LLP_L
 SG_ LED_L_SABL_LED_06_Anf : 30|6@1+ (1.6,0) [0|100.8] "Unit_PerCent"  LED_DK3_LM_L,LLP_L
 SG_ LED_L_SABL_LED_07_Anf : 36|6@1+ (1.6,0) [0|100.8] "Unit_PerCent"  LED_DK3_LM_L,LLP_L
 SG_ LED_L_SABL_LED_08_Anf : 42|6@1+ (1.6,0) [0|100.8] "Unit_PerCent"  LED_DK3_LM_L,LLP_L
 SG_ LED_L_SABL_LED_09_Anf : 48|6@1+ (1.6,0) [0|100.8] "Unit_PerCent"  LED_DK3_LM_L,LLP_L
 SG_ LED_L_SABL_LED_10_Anf : 54|6@1+ (1.6,0) [0|100.8] "Unit_PerCent"  LED_DK3_LM_L,LLP_L

BO_TX_BU_ 2527679510 : LED_DK3_LM_L,LLP_L;
BO_TX_BU_ 2527679511 : LED_DK3_LM_R,LLP_R;
CM_ SG_ 1342 LED_L_Abbiegel_Def_1 "Unterspannung";
CM_ SG_ 1342 LED_L_Abbiegel_Def_2 "Ueberspannung";
CM_ SG_ 1342 LED_L_Abbiegel_Def_3 "Abweichung_CAN_Info_zu_Klemmenspg";
CM_ SG_ 1342 LED_L_Abbiegel_Def_4 "Fehler_Stromcodierung";
CM_ SG_ 1342 LED_L_Abbiegel_Def_5 "Fehler_Temperatursensor";
CM_ SG_ 1342 LED_L_Abbiegel_Def_6 "Uebertemperatur";
CM_ SG_ 1342 LED_L_Abbiegel_Def_7 "Fehler_Lichtfunktion";
CM_ SG_ 1342 LED_L_Abblendl_Def_1 "Unterspannung";
CM_ SG_ 1342 LED_L_Abblendl_Def_2 "Ueberspannung";
CM_ SG_ 1342 LED_L_Abblendl_Def_3 "Abweichung_CAN_Info_zu_Klemmenspg";
CM_ SG_ 1342 LED_L_Abblendl_Def_4 "Fehler_Stromcodierung";
CM_ SG_ 1342 LED_L_Abblendl_Def_5 "Fehler_Temperatursensor";
CM_ SG_ 1342 LED_L_Abblendl_Def_6 "Uebertemperatur";
CM_ SG_ 1342 LED_L_Abblendl_Def_7 "Fehler_Lichtfunktion";
CM_ SG_ 1342 LED_L_Fernl_Def_1 "Unterspannung";
CM_ SG_ 1342 LED_L_Fernl_Def_2 "Ueberspannung";
CM_ SG_ 1342 LED_L_Fernl_Def_3 "Abweichung_CAN_Info_zu_Klemmenspg";
CM_ SG_ 1342 LED_L_Fernl_Def_4 "Fehler_Stromcodierung";
CM_ SG_ 1342 LED_L_Fernl_Def_5 "Fehler_Temperatursensor";
CM_ SG_ 1342 LED_L_Fernl_Def_6 "Uebertemperatur";
CM_ SG_ 1342 LED_L_Fernl_Def_7 "Fehler_Lichtfunktion";
CM_ SG_ 1342 LED_L_TFL_Def_1 "Unterspannung";
CM_ SG_ 1342 LED_L_TFL_Def_2 "Ueberspannung";
CM_ SG_ 1342 LED_L_TFL_Def_3 "Abweichung_CAN_Info_zu_Klemmenspg";
CM_ SG_ 1342 LED_L_TFL_Def_4 "Fehler_Stromcodierung";
CM_ SG_ 1342 LED_L_TFL_Def_5 "Fehler_Temperatursensor";
CM_ SG_ 1342 LED_L_TFL_Def_6 "Uebertemperatur";
CM_ SG_ 1342 LED_L_TFL_Def_7 "Fehler_Lichtfunktion";
CM_ SG_ 1342 LED_L_Allg_Elektr_Def_1 "Fehler_Versorgungsspannung";
CM_ SG_ 1342 LED_L_Allg_Elektr_Def_2 "Uebertemperatur";
CM_ SG_ 1342 LED_L_Allg_Elektr_Def_3 "Fehler_RAM_Check";
CM_ SG_ 1342 LED_L_Allg_Elektr_Def_4 "Fehler_ROM_Check";
CM_ SG_ 1342 LED_L_Allg_Elektr_Def_5 "Fehler_EEPROM";
CM_ SG_ 1342 LED_L_Allg_Elektr_Def_6 "Fehler_interner_Temperatursensor";
CM_ SG_ 1342 LED_L_Allg_Elektr_Def_7 "Fehler_R_L_Erkennung";
CM_ SG_ 1342 LED_L_Allg_Elektr_Def_8 "Sonstige_Fehler";
CM_ SG_ 1342 LED_L_Luefter_1_Def_1 "Luefter_1_Open_Load";
CM_ SG_ 1342 LED_L_Luefter_1_Def_2 "Luefter_1_Kurzschluss";
CM_ SG_ 1342 LED_L_Luefter_1_Def_3 "Luefter_1_Unterspannung";
CM_ SG_ 1342 LED_L_Luefter_1_Def_4 "Luefter_1_Ueberspannung";
CM_ SG_ 1342 LED_L_Luefter_2_Def_1 "Luefter_2_Open_Load";
CM_ SG_ 1342 LED_L_Luefter_2_Def_2 "Luefter_2_Kurzschluss";
CM_ SG_ 1342 LED_L_Luefter_2_Def_3 "Luefter_2_Unterspannung";
CM_ SG_ 1342 LED_L_Luefter_2_Def_4 "Luefter_2_Ueberspannung";
CM_ SG_ 1342 LED_L_ECE_SAE_Umschaltung_Def "Fehler ECE-SAE-Umschaltung";
CM_ SG_ 2527679494 LED_L_Nebel_All_Def_1 "Fehler Nebel-/Allwetterlicht 
Unterspannung";
CM_ SG_ 2527679494 LED_L_Nebel_All_Def_2 "Fehler Nebel-/Allwetterlicht
Ueberspannung";
CM_ SG_ 2527679494 LED_L_Nebel_All_Def_3 "Fehler Nebel-/Allwetterlicht
Abweichung_CAN_Info_zu_Klemmenspg";
CM_ SG_ 2527679494 LED_L_Nebel_All_Def_4 "Fehler Nebel-/Allwetterlicht
Fehler_Stromcodierung";
CM_ SG_ 2527679494 LED_L_Nebel_All_Def_5 "Fehler Nebel-/Allwetterlicht
Fehler_Temperatursensor";
CM_ SG_ 2527679494 LED_L_Nebel_All_Def_6 "Fehler Nebel-/Allwetterlicht
Uebertemperatur";
CM_ SG_ 2527679494 LED_L_Nebel_All_Def_7 "Fehler Nebel-/Allwetterlicht
Fehler_Lichtfunktion";
CM_ SG_ 2527679494 LED_L_Touristenl_Def_1 "Fehler Touristenlicht
Unterspannung";
CM_ SG_ 2527679494 LED_L_Touristenl_Def_2 "Fehler Touristenlicht
Ueberspannung";
CM_ SG_ 2527679494 LED_L_Touristenl_Def_3 "Fehler Touristenlicht
Abweichung_CAN_Info_zu_Klemmenspg";
CM_ SG_ 2527679494 LED_L_Touristenl_Def_4 "Fehler Touristenlicht
Fehler_Stromcodierung";
CM_ SG_ 2527679494 LED_L_Touristenl_Def_5 "Fehler Touristenlicht
Fehler_Temperatursensor";
CM_ SG_ 2527679494 LED_L_Touristenl_Def_6 "Fehler Touristenlicht
Uebertemperatur";
CM_ SG_ 2527679494 LED_L_Touristenl_Def_7 "Fehler Touristenlicht
Fehler_Lichtfunktion";
CM_ SG_ 2527679494 LED_L_Touristenl_Def_Err_Gultig "0 Fehler_nicht_gueltig
1 Fehler_gueltig";
CM_ SG_ 2527679494 LED_L_Autobahnl_Def_1 "Fehler Autobahnlicht
Unterspannung";
CM_ SG_ 2527679494 LED_L_Autobahnl_Def_2 "Fehler Autobahnlicht
Ueberspannung";
CM_ SG_ 2527679494 LED_L_Autobahnl_Def_3 "Fehler Autobahnlicht
Abweichung_CAN_Info_zu_Klemmenspg";
CM_ SG_ 2527679494 LED_L_Autobahnl_Def_4 "Fehler Autobahnlicht
Fehler_Stromcodierung";
CM_ SG_ 2527679494 LED_L_Autobahnl_Def_5 "Fehler Autobahnlicht
Fehler_Temperatursensor";
CM_ SG_ 2527679494 LED_L_Autobahnl_Def_6 "Fehler Autobahnlicht
Uebertemperatur";
CM_ SG_ 2527679494 LED_L_Autobahnl_Def_7 "Fehler Autobahnlicht
Fehler_Lichtfunktion";
CM_ SG_ 2527679494 LED_L_Rennl_Def_1 "Fehler Rennlicht
Unterspannung";
CM_ SG_ 2527679494 LED_L_Rennl_Def_2 "Fehler Rennlicht
Ueberspannung";
CM_ SG_ 2527679494 LED_L_Rennl_Def_3 "Fehler Rennlicht
Abweichung_CAN_Info_zu_Klemmenspg";
CM_ SG_ 2527679494 LED_L_Rennl_Def_4 "Fehler Rennlicht
Fehler_Stromcodierung";
CM_ SG_ 2527679494 LED_L_Rennl_Def_5 "Fehler Rennlicht
Fehler_Temperatursensor";
CM_ SG_ 2527679494 LED_L_Rennl_Def_6 "Fehler Rennlicht
Uebertemperatur";
CM_ SG_ 2527679494 LED_L_Rennl_Def_7 "Fehler Rennlicht
Fehler_Lichtfunktion";
CM_ SG_ 2527679494 LED_L_Stadtl_Def_1 "Fehler Stadtlicht
Unterspannung";
CM_ SG_ 2527679494 LED_L_Stadtl_Def_2 "Fehler Stadtlicht
Ueberspannung";
CM_ SG_ 2527679494 LED_L_Stadtl_Def_3 "Fehler Stadtlicht
Abweichung_CAN_Info_zu_Klemmenspg";
CM_ SG_ 2527679494 LED_L_Stadtl_Def_4 "Fehler Stadtlicht
Fehler_Stromcodierung";
CM_ SG_ 2527679494 LED_L_Stadtl_Def_5 "Fehler Stadtlicht
Fehler_Temperatursensor";
CM_ SG_ 2527679494 LED_L_Stadtl_Def_6 "Fehler Stadtlicht
Uebertemperatur";
CM_ SG_ 2527679494 LED_L_Stadtl_Def_7 "Fehler Stadtlicht
Fehler_Lichtfunktion";
CM_ SG_ 2527679510 LED_Feh_LM_L_03_CRC "Checksumme für LED_Feh_LM_L_03-Botschaft";
CM_ SG_ 2527679510 LED_Feh_LM_L_03_BZ "Botschaftszähler für LED_Feh_LM_L_03-Botschaft";
CM_ SG_ 2527679510 LED_L_Abbiegel_Def "Abbiegelichtfehler";
CM_ SG_ 2527679510 LED_L_Abblendl_Def "Fehler Abblendlicht";
CM_ SG_ 2527679510 LED_L_Allg_Elektr_Def "LED-Leimo defekt";
CM_ SG_ 2527679510 LED_L_Fernl_Def "Fernlichtfehler";
CM_ SG_ 2527679510 LED_L_falsch_codiert "LED-Leimo-Codierung entspricht nicht der Vorgabe durch das Master-SG";
CM_ SG_ 2527679510 LED_L_Zus_Fernl_LH_Def "Fehlerrückmeldung für das Zusatz-Fernlicht";
CM_ SG_ 2527679510 LED_L_Laser_Def "Fehlerrückmeldung für den Laser";
CM_ SG_ 1341 LED_R_Abbiegel_Def_1 "Unterspannung";
CM_ SG_ 1341 LED_R_Abbiegel_Def_2 "Ueberspannung";
CM_ SG_ 1341 LED_R_Abbiegel_Def_3 "Abweichung_CAN_Info_zu_Klemmenspg";
CM_ SG_ 1341 LED_R_Abbiegel_Def_4 "Fehler_Stromcodierung";
CM_ SG_ 1341 LED_R_Abbiegel_Def_5 "Fehler_Temperatursensor";
CM_ SG_ 1341 LED_R_Abbiegel_Def_6 "Uebertemperatur";
CM_ SG_ 1341 LED_R_Abbiegel_Def_7 "Fehler_Lichtfunktion";
CM_ SG_ 1341 LED_R_Abblendl_Def_1 "Unterspannung";
CM_ SG_ 1341 LED_R_Abblendl_Def_2 "Ueberspannung";
CM_ SG_ 1341 LED_R_Abblendl_Def_3 "Abweichung_CAN_Info_zu_Klemmenspg";
CM_ SG_ 1341 LED_R_Abblendl_Def_4 "Fehler_Stromcodierung";
CM_ SG_ 1341 LED_R_Abblendl_Def_5 "Fehler_Temperatursensor";
CM_ SG_ 1341 LED_R_Abblendl_Def_6 "Uebertemperatur";
CM_ SG_ 1341 LED_R_Abblendl_Def_7 "Fehler_Lichtfunktion";
CM_ SG_ 1341 LED_R_Fernl_Def_1 "Unterspannung";
CM_ SG_ 1341 LED_R_Fernl_Def_2 "Ueberspannung";
CM_ SG_ 1341 LED_R_Fernl_Def_3 "Abweichung_CAN_Info_zu_Klemmenspg";
CM_ SG_ 1341 LED_R_Fernl_Def_4 "Fehler_Stromcodierung";
CM_ SG_ 1341 LED_R_Fernl_Def_5 "Fehler_Temperatursensor";
CM_ SG_ 1341 LED_R_Fernl_Def_6 "Uebertemperatur";
CM_ SG_ 1341 LED_R_Fernl_Def_7 "Fehler_Lichtfunktion";
CM_ SG_ 1341 LED_R_TFL_Def_1 "Unterspannung";
CM_ SG_ 1341 LED_R_TFL_Def_2 "Ueberspannung";
CM_ SG_ 1341 LED_R_TFL_Def_3 "Abweichung_CAN_Info_zu_Klemmenspg";
CM_ SG_ 1341 LED_R_TFL_Def_4 "Fehler_Stromcodierung";
CM_ SG_ 1341 LED_R_TFL_Def_5 "Fehler_Temperatursensor";
CM_ SG_ 1341 LED_R_TFL_Def_6 "Uebertemperatur";
CM_ SG_ 1341 LED_R_TFL_Def_7 "Fehler_Lichtfunktion";
CM_ SG_ 1341 LED_R_Allg_Elektr_Def_1 "Fehler_Versorgungsspannung";
CM_ SG_ 1341 LED_R_Allg_Elektr_Def_2 "Uebertemperatur";
CM_ SG_ 1341 LED_R_Allg_Elektr_Def_3 "Fehler_RAM_Check";
CM_ SG_ 1341 LED_R_Allg_Elektr_Def_4 "Fehler_ROM_Check";
CM_ SG_ 1341 LED_R_Allg_Elektr_Def_5 "Fehler_EEPROM";
CM_ SG_ 1341 LED_R_Allg_Elektr_Def_6 "Fehler_interner_Temperatursensor";
CM_ SG_ 1341 LED_R_Allg_Elektr_Def_7 "Fehler_R_L_Erkennung";
CM_ SG_ 1341 LED_R_Allg_Elektr_Def_8 "Sonstige_Fehler";
CM_ SG_ 1341 LED_R_Luefter_1_Def_1 "Luefter_1_Open_Load";
CM_ SG_ 1341 LED_R_Luefter_1_Def_2 "Luefter_1_Kurzschluss";
CM_ SG_ 1341 LED_R_Luefter_1_Def_3 "Luefter_1_Unterspannung";
CM_ SG_ 1341 LED_R_Luefter_1_Def_4 "Luefter_1_Ueberspannung";
CM_ SG_ 1341 LED_R_Luefter_2_Def_1 "Luefter_2_Open_Load";
CM_ SG_ 1341 LED_R_Luefter_2_Def_2 "Luefter_2_Kurzschluss";
CM_ SG_ 1341 LED_R_Luefter_2_Def_3 "Luefter_2_Unterspannung";
CM_ SG_ 1341 LED_R_Luefter_2_Def_4 "Luefter_2_Ueberspannung";
CM_ SG_ 1341 LED_R_ECE_SAE_Umschaltung_Def "Fehler ECE-SAE-Umschaltung";
CM_ SG_ 2527679495 LED_R_Nebel_All_Def_1 "Fehler Nebel-/Allwetterlicht
Unterspannung";
CM_ SG_ 2527679495 LED_R_Nebel_All_Def_2 "Fehler Nebel-/Allwetterlicht
Ueberspannung";
CM_ SG_ 2527679495 LED_R_Nebel_All_Def_3 "Fehler Nebel-/Allwetterlicht
Abweichung_CAN_Info_zu_Klemmenspg";
CM_ SG_ 2527679495 LED_R_Nebel_All_Def_4 "Fehler Nebel-/Allwetterlicht
Fehler_Stromcodierung";
CM_ SG_ 2527679495 LED_R_Nebel_All_Def_5 "Fehler Nebel-/Allwetterlicht
Fehler_Temperatursensor";
CM_ SG_ 2527679495 LED_R_Nebel_All_Def_6 "Fehler Nebel-/Allwetterlicht
Uebertemperatur";
CM_ SG_ 2527679495 LED_R_Nebel_All_Def_7 "Fehler Nebel-/Allwetterlicht
Fehler_Lichtfunktion";
CM_ SG_ 2527679495 LED_R_Touristenl_Def_1 "Fehler Touristenlicht
Unterspannung";
CM_ SG_ 2527679495 LED_R_Touristenl_Def_2 "Fehler Touristenlicht
Ueberspannung";
CM_ SG_ 2527679495 LED_R_Touristenl_Def_3 "Fehler Touristenlicht
Abweichung_CAN_Info_zu_Klemmenspg";
CM_ SG_ 2527679495 LED_R_Touristenl_Def_4 "Fehler Touristenlicht
Fehler_Stromcodierung";
CM_ SG_ 2527679495 LED_R_Touristenl_Def_5 "Fehler Touristenlicht
Fehler_Temperatursensor";
CM_ SG_ 2527679495 LED_R_Touristenl_Def_6 "Fehler Touristenlicht
Uebertemperatur";
CM_ SG_ 2527679495 LED_R_Touristenl_Def_7 "Fehler Touristenlicht
Fehler_Lichtfunktion";
CM_ SG_ 2527679495 LED_R_Autobahnl_Def_1 "Fehler Autobahnlicht
Unterspannung";
CM_ SG_ 2527679495 LED_R_Autobahnl_Def_2 "Fehler Autobahnlicht
Ueberspannung";
CM_ SG_ 2527679495 LED_R_Autobahnl_Def_3 "Fehler Autobahnlicht
Abweichung_CAN_Info_zu_Klemmenspg";
CM_ SG_ 2527679495 LED_R_Autobahnl_Def_4 "Fehler Autobahnlicht
Fehler_Stromcodierung";
CM_ SG_ 2527679495 LED_R_Autobahnl_Def_5 "Fehler Autobahnlicht
Fehler_Temperatursensor";
CM_ SG_ 2527679495 LED_R_Autobahnl_Def_6 "Fehler Autobahnlicht
Uebertemperatur";
CM_ SG_ 2527679495 LED_R_Autobahnl_Def_7 "Fehler Autobahnlicht
Fehler_Lichtfunktion";
CM_ SG_ 2527679495 LED_R_Rennl_Def_1 "Fehler Rennlicht
Unterspannung";
CM_ SG_ 2527679495 LED_R_Rennl_Def_2 "Fehler Rennlicht
Ueberspannung";
CM_ SG_ 2527679495 LED_R_Rennl_Def_3 "Fehler Rennlicht
Abweichung_CAN_Info_zu_Klemmenspg";
CM_ SG_ 2527679495 LED_R_Rennl_Def_4 "Fehler Rennlicht
Fehler_Stromcodierung";
CM_ SG_ 2527679495 LED_R_Rennl_Def_5 "Fehler Rennlicht
Fehler_Temperatursensor";
CM_ SG_ 2527679495 LED_R_Rennl_Def_6 "Fehler Rennlicht
Uebertemperatur";
CM_ SG_ 2527679495 LED_R_Rennl_Def_7 "Fehler Rennlicht
Uebertemperatur";
CM_ SG_ 2527679495 LED_R_Stadtl_Def_1 "Fehler Stadtlicht
Unterspannung";
CM_ SG_ 2527679495 LED_R_Stadtl_Def_2 "Fehler Stadtlicht
Ueberspannung";
CM_ SG_ 2527679495 LED_R_Stadtl_Def_3 "Fehler Stadtlicht
Abweichung_CAN_Info_zu_Klemmenspg";
CM_ SG_ 2527679495 LED_R_Stadtl_Def_4 "Fehler Stadtlicht
Fehler_Stromcodierung";
CM_ SG_ 2527679495 LED_R_Stadtl_Def_5 "Fehler Stadtlicht
Fehler_Temperatursensor";
CM_ SG_ 2527679495 LED_R_Stadtl_Def_6 "Fehler Stadtlicht
Uebertemperatur";
CM_ SG_ 2527679495 LED_R_Stadtl_Def_7 "Fehler Stadtlicht
Fehler_Lichtfunktion";
CM_ SG_ 2527679511 LED_Feh_LM_R_03_CRC "Checksumme für LED_Feh_LM_L_03-Botschaft";
CM_ SG_ 2527679511 LED_Feh_LM_R_03_BZ "Botschaftszähler für LED_Feh_LM_R_03-Botschaft";
CM_ SG_ 2527679511 LED_R_Abbiegel_Def "Abbiegelichtfehler";
CM_ SG_ 2527679511 LED_R_Abblendl_Def "Fehler Abblendlicht";
CM_ SG_ 2527679511 LED_R_Allg_Elektr_Def "LED-Leimo defekt";
CM_ SG_ 2527679511 LED_R_Fernl_Def "Fernlichtfehler";
CM_ SG_ 2527679511 LED_R_falsch_codiert "LED-Leimo-Codierung entspricht nicht der Vorgabe durch das Master-SG";
CM_ SG_ 2527679511 LED_R_Zus_Fernl_LH_Def "Fehlerrückmeldung für das Zusatz-Fernlicht";
CM_ SG_ 2527679511 LED_R_Laser_Def "Fehlerrückmeldung für den Laser";
CM_ SG_ 1422 LED_L_Mux "Durch Setzen der Multiplexer-IDENT Bits werden die einzelnen Bytes der Botschaft abgefragt ähnlich der Wegfahrsperre";
CM_ SG_ 1422 LED_L_SW_Idt_Z01 "Software Ident Zeichen 1";
CM_ SG_ 1422 LED_L_SW_Idt_Z08 "Software Ident Zeichen 8";
CM_ SG_ 1422 LED_L_SW_Idx_Z04 "Software Index Zeichen 4";
CM_ SG_ 1422 LED_L_HW_Idt_Z07 "Hardware Ident Zeichen 7";
CM_ SG_ 1422 LED_L_HW_Idx_Z03 "Hardware Index Zeichen 3";
CM_ SG_ 1422 LED_L_SW_Idt_Z02 "Software Ident Zeichen 2";
CM_ SG_ 1422 LED_L_SW_Idt_Z09 "Software Ident Zeichen 9";
CM_ SG_ 1422 LED_L_HW_Idt_Z01 "Hardware Ident Zeichen 1";
CM_ SG_ 1422 LED_L_HW_Idt_Z08 "Hardware Ident Zeichen 8";
CM_ SG_ 1422 LED_L_SW_Idt_Z03 "Software Ident Zeichen 3";
CM_ SG_ 1422 LED_L_SW_Idt_Z10 "Software Ident Zeichen 10";
CM_ SG_ 1422 LED_L_HW_Idt_Z02 "Hardware Ident Zeichen 2";
CM_ SG_ 1422 LED_L_HW_Idt_Z09 "Hardware Ident Zeichen 9";
CM_ SG_ 1422 LED_L_SW_Idt_Z04 "Software Ident Zeichen 4";
CM_ SG_ 1422 LED_L_SW_Idt_Z11 "Software Ident Zeichen 11";
CM_ SG_ 1422 LED_L_HW_Idt_Z03 "Hardware Ident Zeichen 3";
CM_ SG_ 1422 LED_L_HW_Idt_Z10 "Hardware Ident Zeichen 10";
CM_ SG_ 1422 LED_L_SW_Idt_Z05 "Software Ident Zeichen 5";
CM_ SG_ 1422 LED_L_SW_Idx_Z01 "Software Index Zeichen 1";
CM_ SG_ 1422 LED_L_HW_Idt_Z04 "Hardware Ident Zeichen 4";
CM_ SG_ 1422 LED_L_HW_Idt_Z11 "Hardware Ident Zeichen 11";
CM_ SG_ 1422 LED_L_SW_Idt_Z06 "Software Ident Zeichen 6";
CM_ SG_ 1422 LED_L_SW_Idx_Z02 "Software Index Zeichen 2";
CM_ SG_ 1422 LED_L_HW_Idt_Z05 "Hardware Ident Zeichen 5";
CM_ SG_ 1422 LED_L_HW_Idx_Z01 "Hardware Index Zeichen 1";
CM_ SG_ 1422 LED_L_SW_Idt_Z07 "Software Ident Zeichen 7";
CM_ SG_ 1422 LED_L_SW_Idx_Z03 "Software Index Zeichen 3";
CM_ SG_ 1422 LED_L_HW_Idt_Z06 "Hardware Ident Zeichen 6";
CM_ SG_ 1422 LED_L_HW_Idx_Z02 "Hardware Index Zeichen 2";
CM_ SG_ 1421 LED_R_Mux "Durch Setzen der Multiplexer-IDENT Bits werden die einzelnen Bytes der Botschaft abgefragt ähnlich der Wegfahrsperre";
CM_ SG_ 1421 LED_R_SW_Idt_Z01 "Software Ident Zeichen 1";
CM_ SG_ 1421 LED_R_SW_Idt_Z08 "Software Ident Zeichen 8";
CM_ SG_ 1421 LED_R_SW_Idx_Z04 "Software Index Zeichen 1";
CM_ SG_ 1421 LED_R_HW_Idt_Z07 "Hardware Ident Zeichen 7";
CM_ SG_ 1421 LED_R_HW_Idx_Z03 "Hardware Index Zeichen 3";
CM_ SG_ 1421 LED_R_SW_Idt_Z02 "Software Ident Zeichen 2";
CM_ SG_ 1421 LED_R_SW_Idt_Z09 "Software Ident Zeichen 9";
CM_ SG_ 1421 LED_R_HW_Idt_Z01 "Hardware Ident Zeichen 1";
CM_ SG_ 1421 LED_R_HW_Idt_Z08 "Hardware Ident Zeichen 8";
CM_ SG_ 1421 LED_R_SW_Idt_Z03 "Software Ident Zeichen 3";
CM_ SG_ 1421 LED_R_SW_Idt_Z10 "Software Ident Zeichen 10";
CM_ SG_ 1421 LED_R_HW_Idt_Z02 "Hardware Ident Zeichen 2";
CM_ SG_ 1421 LED_R_HW_Idt_Z09 "Hardware Ident Zeichen 9";
CM_ SG_ 1421 LED_R_SW_Idt_Z04 "Software Ident Zeichen 4";
CM_ SG_ 1421 LED_R_SW_Idt_Z11 "Software Ident Zeichen 11";
CM_ SG_ 1421 LED_R_HW_Idt_Z03 "Hardware Ident Zeichen 3";
CM_ SG_ 1421 LED_R_HW_Idt_Z10 "Hardware Ident Zeichen 10";
CM_ SG_ 1421 LED_R_SW_Idt_Z05 "Software Ident Zeichen 5";
CM_ SG_ 1421 LED_R_SW_Idx_Z01 "Software Index Zeichen 1";
CM_ SG_ 1421 LED_R_HW_Idt_Z04 "Hardware Ident Zeichen 4";
CM_ SG_ 1421 LED_R_HW_Idt_Z11 "Hardware Ident Zeichen 11";
CM_ SG_ 1421 LED_R_SW_Idt_Z06 "Software Ident Zeichen 6";
CM_ SG_ 1421 LED_R_SW_Idx_Z02 "Software Index Zeichen 1";
CM_ SG_ 1421 LED_R_HW_Idt_Z05 "Hardware Ident Zeichen 5";
CM_ SG_ 1421 LED_R_HW_Idx_Z01 "Hardware Index Zeichen 1";
CM_ SG_ 1421 LED_R_SW_Idt_Z07 "Software Ident Zeichen 7";
CM_ SG_ 1421 LED_R_SW_Idx_Z03 "Software Index Zeichen 1";
CM_ SG_ 1421 LED_R_HW_Idt_Z06 "Hardware Ident Zeichen 6";
CM_ SG_ 1421 LED_R_HW_Idx_Z02 "Hardware Index Zeichen 2";
CM_ SG_ 1290 LED_L_Scheinw_Var_1 "LED_L_Scheinw_Var_1 und LED_L_Scheinw_Var_2 bilden zusammen eine laufende Nummer zur Spezifierung der scheinwerfervarianten- abhängigen Codierung.

Die Scheinwerfervariante beinhaltet die firmenspezifische Funktionalität im Master!
Der Codierforgang wi";
CM_ SG_ 1290 LED_L_Scheinw_Var_2 "LED_L_Scheinw_Var_1 und LED_L_Scheinw_Var_2 bilden zusammen eine laufende Nummer zur Spezifierung der scheinwerfervarianten- abhängigen Codierung.

Die Scheinwerfervariante beinhaltet die firmenspezifische Funktionalität im Master!
Der Codierforgang wi";
CM_ SG_ 1291 LED_R_Scheinw_Var_1 "LED_R_Scheinw_Var_1 und LED_R_Scheinw_Var_2 bilden zusammen eine laufende Nummer zur Spezifierung der scheinwerfervarianten- abhängigen Codierung.

Die Scheinwerfervariante beinhaltet die firmenspezifische Funktionalität im Master!
Der Codierforgang wi";
CM_ SG_ 1291 LED_R_Scheinw_Var_2 "LED_R_Scheinw_Var_1 und LED_R_Scheinw_Var_2 bilden zusammen eine laufende Nummer zur Spezifierung der scheinwerfervarianten- abhängigen Codierung.

Die Scheinwerfervariante beinhaltet die firmenspezifische Funktionalität im Master!
Der Codierforgang wi";
CM_ SG_ 2589283615 LED_L_DABL_LED_01_Anf "LED PWM Ansteuerung
Die Skalierung erfolgt von 0% - 100%  je nach Kennlinie im LEIMO";
CM_ SG_ 2589283615 LED_L_DABL_LED_02_Anf "LED PWM Ansteuerung
Die Skalierung erfolgt von 0% - 100%  je nach Kennlinie im LEIMO";
CM_ SG_ 2589283615 LED_L_DABL_LED_03_Anf "LED PWM Ansteuerung
Die Skalierung erfolgt von 0% - 100%  je nach Kennlinie im LEIMO";
CM_ SG_ 2589283615 LED_L_DABL_LED_04_Anf "LED PWM Ansteuerung
Die Skalierung erfolgt von 0% - 100%  je nach Kennlinie im LEIMO";
CM_ SG_ 2589283615 LED_L_DABL_LED_05_Anf "LED PWM Ansteuerung
Die Skalierung erfolgt von 0% - 100%  je nach Kennlinie im LEIMO";
CM_ SG_ 2589283615 LED_L_DABL_LED_06_Anf "LED PWM Ansteuerung
Die Skalierung erfolgt von 0% - 100%  je nach Kennlinie im LEIMO";
CM_ SG_ 2589283615 LED_L_DABL_LED_07_Anf "LED PWM Ansteuerung
Die Skalierung erfolgt von 0% - 100%  je nach Kennlinie im LEIMO";
CM_ SG_ 2589283615 LED_L_DABL_LED_08_Anf "LED PWM Ansteuerung
Die Skalierung erfolgt von 0% - 100%  je nach Kennlinie im LEIMO";
CM_ SG_ 2589283615 LED_L_DABL_LED_09_Anf "LED PWM Ansteuerung
Die Skalierung erfolgt von 0% - 100%  je nach Kennlinie im LEIMO";
CM_ SG_ 2589283615 LED_L_DABL_LED_10_Anf "LED PWM Ansteuerung
Die Skalierung erfolgt von 0% - 100%  je nach Kennlinie im LEIMO";
CM_ SG_ 2463978600 LED_L_DABL_LED_11_Anf "LED PWM Ansteuerung
Die Skalierung erfolgt von 0% - 100%  je nach Kennlinie im LEIMO";
CM_ SG_ 2463978600 LED_L_DABL_LED_12_Anf "LED PWM Ansteuerung
Die Skalierung erfolgt von 0% - 100%  je nach Kennlinie im LEIMO";
CM_ SG_ 2463978600 LED_L_DABL_LED_13_Anf "LED PWM Ansteuerung
Die Skalierung erfolgt von 0% - 100%  je nach Kennlinie im LEIMO";
CM_ SG_ 2463978600 LED_L_DABL_LED_14_Anf "LED PWM Ansteuerung
Die Skalierung erfolgt von 0% - 100%  je nach Kennlinie im LEIMO";
CM_ SG_ 2463978600 LED_L_DABL_LED_15_Anf "LED PWM Ansteuerung
Die Skalierung erfolgt von 0% - 100%  je nach Kennlinie im LEIMO";
CM_ SG_ 2463978600 LED_L_DABL_LED_16_Anf "LED PWM Ansteuerung
Die Skalierung erfolgt von 0% - 100%  je nach Kennlinie im LEIMO";
CM_ SG_ 2463978600 LED_L_DABL_LED_17_Anf "LED PWM Ansteuerung
Die Skalierung erfolgt von 0% - 100%  je nach Kennlinie im LEIMO";
CM_ SG_ 2463978600 LED_L_DABL_LED_18_Anf "LED PWM Ansteuerung
Die Skalierung erfolgt von 0% - 100%  je nach Kennlinie im LEIMO";
CM_ SG_ 2463978600 LED_L_DABL_LED_19_Anf "LED PWM Ansteuerung
Die Skalierung erfolgt von 0% - 100%  je nach Kennlinie im LEIMO";
CM_ SG_ 2463978600 LED_L_DABL_LED_20_Anf "LED PWM Ansteuerung
Die Skalierung erfolgt von 0% - 100%  je nach Kennlinie im LEIMO";
CM_ SG_ 836 LED_L_SABL_LED_01_Anf "LED PWM Ansteuerung
Die Skalierung erfolgt von 0% - 100%  je nach Kennlinie im LEIMO";
CM_ SG_ 836 LED_L_SABL_LED_02_Anf "LED PWM Ansteuerung
Die Skalierung erfolgt von 0% - 100%  je nach Kennlinie im LEIMO";
CM_ SG_ 836 LED_L_SABL_LED_03_Anf "LED PWM Ansteuerung
Die Skalierung erfolgt von 0% - 100%  je nach Kennlinie im LEIMO";
CM_ SG_ 836 LED_L_SABL_LED_04_Anf "LED PWM Ansteuerung
Die Skalierung erfolgt von 0% - 100%  je nach Kennlinie im LEIMO";
CM_ SG_ 836 LED_L_SABL_LED_05_Anf "LED PWM Ansteuerung
Die Skalierung erfolgt von 0% - 100%  je nach Kennlinie im LEIMO";
CM_ SG_ 836 LED_L_SABL_LED_06_Anf "LED PWM Ansteuerung
Die Skalierung erfolgt von 0% - 100%  je nach Kennlinie im LEIMO";
CM_ SG_ 836 LED_L_SABL_LED_07_Anf "LED PWM Ansteuerung
Die Skalierung erfolgt von 0% - 100%  je nach Kennlinie im LEIMO";
CM_ SG_ 836 LED_L_SABL_LED_08_Anf "LED PWM Ansteuerung
Die Skalierung erfolgt von 0% - 100%  je nach Kennlinie im LEIMO";
CM_ SG_ 836 LED_L_SABL_LED_09_Anf "LED PWM Ansteuerung
Die Skalierung erfolgt von 0% - 100%  je nach Kennlinie im LEIMO";
CM_ SG_ 836 LED_L_SABL_LED_10_Anf "LED PWM Ansteuerung
Die Skalierung erfolgt von 0% - 100%  je nach Kennlinie im LEIMO";
BA_DEF_ BO_  "DiagRequest" ENUM  "No","Yes";
BA_DEF_ BO_  "DiagResponse" ENUM  "No","Yes";
BA_DEF_ BO_  "DiagState" ENUM  "No","Yes";
BA_DEF_ BO_  "GenMsgChkConstant" HEX 0 4095;
BA_DEF_ BO_  "GenMsgCycleTime" INT 0 65535;
BA_DEF_ BO_  "GenMsgCycleTimeFast" INT 0 65535;
BA_DEF_ BO_  "GenMsgDelayTime" INT 0 100000;
BA_DEF_ BO_  "GenMsgILSupport" ENUM  "No","Yes";
BA_DEF_ BO_  "GenMsgNrOfRepetition" INT 0 100;
BA_DEF_ BO_  "GenMsgPDUConstants" STRING ;
BA_DEF_ BO_  "GenMsgSendType" ENUM  "Cyclic","not_used","not_used","not_used","not_used","not_used","not_used","IfActive","NoMsgSendType";
BA_DEF_ BO_  "GenMsgStartDelayTime" INT 0 100000;
BA_DEF_ BO_  "NmMessage" ENUM  "No","Yes";
BA_DEF_ BO_  "NmhMessage" ENUM  "No","Yes";
BA_DEF_ BO_  "MsgType" ENUM  "Application","NM ","NMH","TP2.0","ISO-TP ","BAP","EID","KS";
BA_DEF_ BO_  "VAGTP20_API" HEX 0 255;
BA_DEF_ BO_  "VAGTP20_DynConnection" ENUM  "No","Yes";
BA_DEF_ BO_  "VAGTP20_DynSetup" ENUM  "No","Yes";
BA_DEF_ BO_  "VAGTP20_StatConnection" ENUM  "No","Yes";
BA_DEF_ SG_  "GenSigActiveRepetitions" INT -2147483648 2147483647;
BA_DEF_ SG_  "GenSigSendType" ENUM  "Cyclic","OnWrite","OnWriteWithRepetition","OnChange","OnChangeWithRepetition","IfActive","IfActiveWithRepetition","NoSigSendType","OnChangeAndIfActive","OnChangeAndIfActiveWithRepetition";
BA_DEF_ SG_  "GenSigStartValue" INT -2147483648 2147483647;
BA_DEF_ SG_  "NWM-WakeupAllowed" ENUM  "No","Yes";
BA_DEF_ SG_  "GenSigFuncType" ENUM  "NoFunction","MsgCounter","CRC-8","XOR","XOR-2","DatedBit","SW-Kl15","CHK","Constant","Protocol","CRC-8-SAE_J1850";
BA_DEF_ SG_  "GenSigSwitchedByIgnition" ENUM  "No","Yes";
BA_DEF_ SG_  "Fehlerwert" HEX 0 2147483647;
BA_DEF_ SG_  "GenSigMissingSourceValue" HEX 0 2147483647;
BA_DEF_REL_ BU_SG_REL_  "GenSigTimeoutTime" INT 0 65535;
BA_DEF_DEF_  "DiagRequest" "No";
BA_DEF_DEF_  "DiagResponse" "No";
BA_DEF_DEF_  "DiagState" "No";
BA_DEF_DEF_  "GenMsgChkConstant" 0;
BA_DEF_DEF_  "GenMsgCycleTime" 0;
BA_DEF_DEF_  "GenMsgCycleTimeFast" 0;
BA_DEF_DEF_  "GenMsgDelayTime" 0;
BA_DEF_DEF_  "GenMsgILSupport" "No";
BA_DEF_DEF_  "GenMsgNrOfRepetition" 0;
BA_DEF_DEF_  "GenMsgPDUConstants" "";
BA_DEF_DEF_  "GenMsgSendType" "NoMsgSendType";
BA_DEF_DEF_  "GenMsgStartDelayTime" 0;
BA_DEF_DEF_  "NmMessage" "No";
BA_DEF_DEF_  "NmhMessage" "No";
BA_DEF_DEF_  "MsgType" "Application";
BA_DEF_DEF_  "VAGTP20_API" 0;
BA_DEF_DEF_  "VAGTP20_DynConnection" "No";
BA_DEF_DEF_  "VAGTP20_DynSetup" "No";
BA_DEF_DEF_  "VAGTP20_StatConnection" "No";
BA_DEF_DEF_  "GenSigActiveRepetitions" 0;
BA_DEF_DEF_  "GenSigSendType" "NoSigSendType";
BA_DEF_DEF_  "GenSigStartValue" 0;
BA_DEF_DEF_  "NWM-WakeupAllowed" "No";
BA_DEF_DEF_  "GenSigFuncType" "NoFunction";
BA_DEF_DEF_  "GenSigSwitchedByIgnition" "Yes";
BA_DEF_DEF_  "Fehlerwert" 0;
BA_DEF_DEF_  "GenSigMissingSourceValue" 0;
BA_DEF_DEF_REL_ "GenSigTimeoutTime" 0;
BA_ "GenMsgCycleTime" BO_ 1342 200;
BA_ "GenMsgILSupport" BO_ 1342 1;
BA_ "GenMsgSendType" BO_ 1342 0;
BA_ "GenMsgCycleTime" BO_ 2527679494 200;
BA_ "GenMsgILSupport" BO_ 2527679494 1;
BA_ "GenMsgSendType" BO_ 2527679494 0;
BA_ "GenMsgCycleTime" BO_ 2527679510 200;
BA_ "GenMsgILSupport" BO_ 2527679510 1;
BA_ "GenMsgSendType" BO_ 2527679510 0;
BA_ "GenMsgCycleTime" BO_ 1341 200;
BA_ "GenMsgILSupport" BO_ 1341 1;
BA_ "GenMsgSendType" BO_ 1341 0;
BA_ "GenMsgCycleTime" BO_ 2527679495 200;
BA_ "GenMsgILSupport" BO_ 2527679495 1;
BA_ "GenMsgSendType" BO_ 2527679495 0;
BA_ "GenMsgCycleTime" BO_ 2527679511 200;
BA_ "GenMsgILSupport" BO_ 2527679511 1;
BA_ "GenMsgSendType" BO_ 2527679511 0;
BA_ "GenMsgCycleTime" BO_ 1422 100;
BA_ "GenMsgILSupport" BO_ 1422 1;
BA_ "GenMsgSendType" BO_ 1422 0;
BA_ "GenMsgCycleTime" BO_ 1421 100;
BA_ "GenMsgILSupport" BO_ 1421 1;
BA_ "GenMsgSendType" BO_ 1421 0;
BA_ "GenMsgCycleTime" BO_ 1290 100;
BA_ "GenMsgILSupport" BO_ 1290 1;
BA_ "GenMsgSendType" BO_ 1290 0;
BA_ "GenMsgCycleTime" BO_ 1291 100;
BA_ "GenMsgILSupport" BO_ 1291 1;
BA_ "GenMsgSendType" BO_ 1291 0;
BA_ "GenMsgCycleTime" BO_ 2589283615 200;
BA_ "GenMsgDelayTime" BO_ 2589283615 20;
BA_ "GenMsgILSupport" BO_ 2589283615 1;
BA_ "GenMsgSendType" BO_ 2589283615 0;
BA_ "GenMsgCycleTime" BO_ 2463978600 200;
BA_ "GenMsgDelayTime" BO_ 2463978600 20;
BA_ "GenMsgILSupport" BO_ 2463978600 1;
BA_ "GenMsgSendType" BO_ 2463978600 0;
BA_ "GenMsgCycleTime" BO_ 836 200;
BA_ "GenMsgDelayTime" BO_ 836 20;
BA_ "GenMsgILSupport" BO_ 836 1;
BA_ "GenMsgSendType" BO_ 836 0;
BA_ "GenSigSendType" SG_ 1342 LED_L_Abbiegel_Def_1 0;
BA_ "Fehlerwert" SG_ 1342 LED_L_Abbiegel_Def_1 1;
BA_ "GenSigSendType" SG_ 1342 LED_L_Abbiegel_Def_2 0;
BA_ "Fehlerwert" SG_ 1342 LED_L_Abbiegel_Def_2 1;
BA_ "GenSigSendType" SG_ 1342 LED_L_Abbiegel_Def_3 0;
BA_ "Fehlerwert" SG_ 1342 LED_L_Abbiegel_Def_3 1;
BA_ "GenSigSendType" SG_ 1342 LED_L_Abbiegel_Def_4 0;
BA_ "Fehlerwert" SG_ 1342 LED_L_Abbiegel_Def_4 1;
BA_ "GenSigSendType" SG_ 1342 LED_L_Abbiegel_Def_5 0;
BA_ "Fehlerwert" SG_ 1342 LED_L_Abbiegel_Def_5 1;
BA_ "GenSigSendType" SG_ 1342 LED_L_Abbiegel_Def_6 0;
BA_ "Fehlerwert" SG_ 1342 LED_L_Abbiegel_Def_6 1;
BA_ "GenSigSendType" SG_ 1342 LED_L_Abbiegel_Def_7 0;
BA_ "Fehlerwert" SG_ 1342 LED_L_Abbiegel_Def_7 1;
BA_ "GenSigSendType" SG_ 1342 LED_L_Abbiegel_Def_Err_Gultig 0;
BA_ "GenSigSendType" SG_ 1342 LED_L_Abblendl_Def_1 0;
BA_ "Fehlerwert" SG_ 1342 LED_L_Abblendl_Def_1 1;
BA_ "GenSigSendType" SG_ 1342 LED_L_Abblendl_Def_2 0;
BA_ "Fehlerwert" SG_ 1342 LED_L_Abblendl_Def_2 1;
BA_ "GenSigSendType" SG_ 1342 LED_L_Abblendl_Def_3 0;
BA_ "Fehlerwert" SG_ 1342 LED_L_Abblendl_Def_3 1;
BA_ "GenSigSendType" SG_ 1342 LED_L_Abblendl_Def_4 0;
BA_ "Fehlerwert" SG_ 1342 LED_L_Abblendl_Def_4 1;
BA_ "GenSigSendType" SG_ 1342 LED_L_Abblendl_Def_5 0;
BA_ "Fehlerwert" SG_ 1342 LED_L_Abblendl_Def_5 1;
BA_ "GenSigSendType" SG_ 1342 LED_L_Abblendl_Def_6 0;
BA_ "Fehlerwert" SG_ 1342 LED_L_Abblendl_Def_6 1;
BA_ "GenSigSendType" SG_ 1342 LED_L_Abblendl_Def_7 0;
BA_ "Fehlerwert" SG_ 1342 LED_L_Abblendl_Def_7 1;
BA_ "GenSigSendType" SG_ 1342 LED_L_Abblendl_Def_Err_Gultig 0;
BA_ "GenSigSendType" SG_ 1342 LED_L_Fernl_Def_1 0;
BA_ "Fehlerwert" SG_ 1342 LED_L_Fernl_Def_1 1;
BA_ "GenSigSendType" SG_ 1342 LED_L_Fernl_Def_2 0;
BA_ "Fehlerwert" SG_ 1342 LED_L_Fernl_Def_2 1;
BA_ "GenSigSendType" SG_ 1342 LED_L_Fernl_Def_3 0;
BA_ "Fehlerwert" SG_ 1342 LED_L_Fernl_Def_3 1;
BA_ "GenSigSendType" SG_ 1342 LED_L_Fernl_Def_4 0;
BA_ "Fehlerwert" SG_ 1342 LED_L_Fernl_Def_4 1;
BA_ "GenSigSendType" SG_ 1342 LED_L_Fernl_Def_5 0;
BA_ "Fehlerwert" SG_ 1342 LED_L_Fernl_Def_5 1;
BA_ "GenSigSendType" SG_ 1342 LED_L_Fernl_Def_6 0;
BA_ "Fehlerwert" SG_ 1342 LED_L_Fernl_Def_6 1;
BA_ "GenSigSendType" SG_ 1342 LED_L_Fernl_Def_7 0;
BA_ "Fehlerwert" SG_ 1342 LED_L_Fernl_Def_7 1;
BA_ "GenSigSendType" SG_ 1342 LED_L_Fernl_Def_Err_Gultig 0;
BA_ "GenSigSendType" SG_ 1342 LED_L_TFL_Def_1 0;
BA_ "Fehlerwert" SG_ 1342 LED_L_TFL_Def_1 1;
BA_ "GenSigSendType" SG_ 1342 LED_L_TFL_Def_2 0;
BA_ "Fehlerwert" SG_ 1342 LED_L_TFL_Def_2 1;
BA_ "GenSigSendType" SG_ 1342 LED_L_TFL_Def_3 0;
BA_ "Fehlerwert" SG_ 1342 LED_L_TFL_Def_3 1;
BA_ "GenSigSendType" SG_ 1342 LED_L_TFL_Def_4 0;
BA_ "Fehlerwert" SG_ 1342 LED_L_TFL_Def_4 1;
BA_ "GenSigSendType" SG_ 1342 LED_L_TFL_Def_5 0;
BA_ "Fehlerwert" SG_ 1342 LED_L_TFL_Def_5 1;
BA_ "GenSigSendType" SG_ 1342 LED_L_TFL_Def_6 0;
BA_ "Fehlerwert" SG_ 1342 LED_L_TFL_Def_6 1;
BA_ "GenSigSendType" SG_ 1342 LED_L_TFL_Def_7 0;
BA_ "Fehlerwert" SG_ 1342 LED_L_TFL_Def_7 1;
BA_ "GenSigSendType" SG_ 1342 LED_L_TFL_Def_Err_Gultig 0;
BA_ "GenSigSendType" SG_ 1342 LED_L_Allg_Elektr_Def_1 0;
BA_ "Fehlerwert" SG_ 1342 LED_L_Allg_Elektr_Def_1 1;
BA_ "GenSigSendType" SG_ 1342 LED_L_Allg_Elektr_Def_2 0;
BA_ "Fehlerwert" SG_ 1342 LED_L_Allg_Elektr_Def_2 1;
BA_ "GenSigSendType" SG_ 1342 LED_L_Allg_Elektr_Def_3 0;
BA_ "Fehlerwert" SG_ 1342 LED_L_Allg_Elektr_Def_3 1;
BA_ "GenSigSendType" SG_ 1342 LED_L_Allg_Elektr_Def_4 0;
BA_ "Fehlerwert" SG_ 1342 LED_L_Allg_Elektr_Def_4 1;
BA_ "GenSigSendType" SG_ 1342 LED_L_Allg_Elektr_Def_5 0;
BA_ "Fehlerwert" SG_ 1342 LED_L_Allg_Elektr_Def_5 1;
BA_ "GenSigSendType" SG_ 1342 LED_L_Allg_Elektr_Def_6 0;
BA_ "Fehlerwert" SG_ 1342 LED_L_Allg_Elektr_Def_6 1;
BA_ "GenSigSendType" SG_ 1342 LED_L_Allg_Elektr_Def_7 0;
BA_ "Fehlerwert" SG_ 1342 LED_L_Allg_Elektr_Def_7 1;
BA_ "GenSigSendType" SG_ 1342 LED_L_Allg_Elektr_Def_8 0;
BA_ "Fehlerwert" SG_ 1342 LED_L_Allg_Elektr_Def_8 1;
BA_ "GenSigSendType" SG_ 1342 LED_L_Allg_Elektr_Def_Err_Gultig 0;
BA_ "GenSigSendType" SG_ 1342 LED_L_Luefter_1_Def_1 0;
BA_ "Fehlerwert" SG_ 1342 LED_L_Luefter_1_Def_1 1;
BA_ "GenSigSendType" SG_ 1342 LED_L_Luefter_1_Def_2 0;
BA_ "Fehlerwert" SG_ 1342 LED_L_Luefter_1_Def_2 1;
BA_ "GenSigSendType" SG_ 1342 LED_L_Luefter_1_Def_3 0;
BA_ "Fehlerwert" SG_ 1342 LED_L_Luefter_1_Def_3 1;
BA_ "GenSigSendType" SG_ 1342 LED_L_Luefter_1_Def_4 0;
BA_ "Fehlerwert" SG_ 1342 LED_L_Luefter_1_Def_4 1;
BA_ "GenSigSendType" SG_ 1342 LED_L_Luefter_2_Def_1 0;
BA_ "Fehlerwert" SG_ 1342 LED_L_Luefter_2_Def_1 1;
BA_ "GenSigSendType" SG_ 1342 LED_L_Luefter_2_Def_2 0;
BA_ "Fehlerwert" SG_ 1342 LED_L_Luefter_2_Def_2 1;
BA_ "GenSigSendType" SG_ 1342 LED_L_Luefter_2_Def_3 0;
BA_ "Fehlerwert" SG_ 1342 LED_L_Luefter_2_Def_3 1;
BA_ "GenSigSendType" SG_ 1342 LED_L_Luefter_2_Def_4 0;
BA_ "Fehlerwert" SG_ 1342 LED_L_Luefter_2_Def_4 1;
BA_ "GenSigSendType" SG_ 1342 LED_L_Luefter_1_Def_Err_Gultig 0;
BA_ "GenSigSendType" SG_ 1342 LED_L_Luefter_2_Def_Err_Gultig 0;
BA_ "GenSigSendType" SG_ 1342 LED_L_ECE_SAE_Umschaltung_Def 0;
BA_ "Fehlerwert" SG_ 1342 LED_L_ECE_SAE_Umschaltung_Def 1;
BA_ "GenSigSendType" SG_ 2527679494 LED_L_Nebel_All_Def_1 0;
BA_ "Fehlerwert" SG_ 2527679494 LED_L_Nebel_All_Def_1 1;
BA_ "GenSigSendType" SG_ 2527679494 LED_L_Nebel_All_Def_2 0;
BA_ "Fehlerwert" SG_ 2527679494 LED_L_Nebel_All_Def_2 1;
BA_ "GenSigSendType" SG_ 2527679494 LED_L_Nebel_All_Def_3 0;
BA_ "Fehlerwert" SG_ 2527679494 LED_L_Nebel_All_Def_3 1;
BA_ "GenSigSendType" SG_ 2527679494 LED_L_Nebel_All_Def_4 0;
BA_ "Fehlerwert" SG_ 2527679494 LED_L_Nebel_All_Def_4 1;
BA_ "GenSigSendType" SG_ 2527679494 LED_L_Nebel_All_Def_5 0;
BA_ "Fehlerwert" SG_ 2527679494 LED_L_Nebel_All_Def_5 1;
BA_ "GenSigSendType" SG_ 2527679494 LED_L_Nebel_All_Def_6 0;
BA_ "Fehlerwert" SG_ 2527679494 LED_L_Nebel_All_Def_6 1;
BA_ "GenSigSendType" SG_ 2527679494 LED_L_Nebel_All_Def_7 0;
BA_ "Fehlerwert" SG_ 2527679494 LED_L_Nebel_All_Def_7 1;
BA_ "GenSigSendType" SG_ 2527679494 LED_L_Nebel_All_Def_Err_Gultig 0;
BA_ "GenSigSendType" SG_ 2527679494 LED_L_Touristenl_Def_1 0;
BA_ "Fehlerwert" SG_ 2527679494 LED_L_Touristenl_Def_1 1;
BA_ "GenSigSendType" SG_ 2527679494 LED_L_Touristenl_Def_2 0;
BA_ "Fehlerwert" SG_ 2527679494 LED_L_Touristenl_Def_2 1;
BA_ "GenSigSendType" SG_ 2527679494 LED_L_Touristenl_Def_3 0;
BA_ "Fehlerwert" SG_ 2527679494 LED_L_Touristenl_Def_3 1;
BA_ "GenSigSendType" SG_ 2527679494 LED_L_Touristenl_Def_4 0;
BA_ "Fehlerwert" SG_ 2527679494 LED_L_Touristenl_Def_4 1;
BA_ "GenSigSendType" SG_ 2527679494 LED_L_Touristenl_Def_5 0;
BA_ "Fehlerwert" SG_ 2527679494 LED_L_Touristenl_Def_5 1;
BA_ "GenSigSendType" SG_ 2527679494 LED_L_Touristenl_Def_6 0;
BA_ "Fehlerwert" SG_ 2527679494 LED_L_Touristenl_Def_6 1;
BA_ "GenSigSendType" SG_ 2527679494 LED_L_Touristenl_Def_7 0;
BA_ "Fehlerwert" SG_ 2527679494 LED_L_Touristenl_Def_7 1;
BA_ "GenSigSendType" SG_ 2527679494 LED_L_Touristenl_Def_Err_Gultig 0;
BA_ "GenSigSendType" SG_ 2527679494 LED_L_Autobahnl_Def_1 0;
BA_ "Fehlerwert" SG_ 2527679494 LED_L_Autobahnl_Def_1 1;
BA_ "GenSigSendType" SG_ 2527679494 LED_L_Autobahnl_Def_2 0;
BA_ "Fehlerwert" SG_ 2527679494 LED_L_Autobahnl_Def_2 1;
BA_ "GenSigSendType" SG_ 2527679494 LED_L_Autobahnl_Def_3 0;
BA_ "Fehlerwert" SG_ 2527679494 LED_L_Autobahnl_Def_3 1;
BA_ "GenSigSendType" SG_ 2527679494 LED_L_Autobahnl_Def_4 0;
BA_ "Fehlerwert" SG_ 2527679494 LED_L_Autobahnl_Def_4 1;
BA_ "GenSigSendType" SG_ 2527679494 LED_L_Autobahnl_Def_5 0;
BA_ "Fehlerwert" SG_ 2527679494 LED_L_Autobahnl_Def_5 1;
BA_ "GenSigSendType" SG_ 2527679494 LED_L_Autobahnl_Def_6 0;
BA_ "Fehlerwert" SG_ 2527679494 LED_L_Autobahnl_Def_6 1;
BA_ "GenSigSendType" SG_ 2527679494 LED_L_Autobahnl_Def_7 0;
BA_ "Fehlerwert" SG_ 2527679494 LED_L_Autobahnl_Def_7 1;
BA_ "GenSigSendType" SG_ 2527679494 LED_L_Autobahnl_Def_Err_Gultig 0;
BA_ "GenSigSendType" SG_ 2527679494 LED_L_Rennl_Def_1 0;
BA_ "Fehlerwert" SG_ 2527679494 LED_L_Rennl_Def_1 1;
BA_ "GenSigSendType" SG_ 2527679494 LED_L_Rennl_Def_2 0;
BA_ "Fehlerwert" SG_ 2527679494 LED_L_Rennl_Def_2 1;
BA_ "GenSigSendType" SG_ 2527679494 LED_L_Rennl_Def_3 0;
BA_ "Fehlerwert" SG_ 2527679494 LED_L_Rennl_Def_3 1;
BA_ "GenSigSendType" SG_ 2527679494 LED_L_Rennl_Def_4 0;
BA_ "Fehlerwert" SG_ 2527679494 LED_L_Rennl_Def_4 1;
BA_ "GenSigSendType" SG_ 2527679494 LED_L_Rennl_Def_5 0;
BA_ "Fehlerwert" SG_ 2527679494 LED_L_Rennl_Def_5 1;
BA_ "GenSigSendType" SG_ 2527679494 LED_L_Rennl_Def_6 0;
BA_ "Fehlerwert" SG_ 2527679494 LED_L_Rennl_Def_6 1;
BA_ "GenSigSendType" SG_ 2527679494 LED_L_Rennl_Def_7 0;
BA_ "Fehlerwert" SG_ 2527679494 LED_L_Rennl_Def_7 1;
BA_ "GenSigSendType" SG_ 2527679494 LED_L_Rennl_Def_Err_Gultig 0;
BA_ "GenSigSendType" SG_ 2527679494 LED_L_Stadtl_Def_1 0;
BA_ "Fehlerwert" SG_ 2527679494 LED_L_Stadtl_Def_1 1;
BA_ "GenSigSendType" SG_ 2527679494 LED_L_Stadtl_Def_2 0;
BA_ "Fehlerwert" SG_ 2527679494 LED_L_Stadtl_Def_2 1;
BA_ "GenSigSendType" SG_ 2527679494 LED_L_Stadtl_Def_3 0;
BA_ "Fehlerwert" SG_ 2527679494 LED_L_Stadtl_Def_3 1;
BA_ "GenSigSendType" SG_ 2527679494 LED_L_Stadtl_Def_4 0;
BA_ "Fehlerwert" SG_ 2527679494 LED_L_Stadtl_Def_4 1;
BA_ "GenSigSendType" SG_ 2527679494 LED_L_Stadtl_Def_5 0;
BA_ "Fehlerwert" SG_ 2527679494 LED_L_Stadtl_Def_5 1;
BA_ "GenSigSendType" SG_ 2527679494 LED_L_Stadtl_Def_6 0;
BA_ "Fehlerwert" SG_ 2527679494 LED_L_Stadtl_Def_6 1;
BA_ "GenSigSendType" SG_ 2527679494 LED_L_Stadtl_Def_7 0;
BA_ "Fehlerwert" SG_ 2527679494 LED_L_Stadtl_Def_7 1;
BA_ "GenSigSendType" SG_ 2527679494 LED_L_Stadtl_Def_Err_Gultig 0;
BA_ "GenSigSendType" SG_ 2527679510 LED_Feh_LM_L_03_CRC 0;
BA_ "GenSigFuncType" SG_ 2527679510 LED_Feh_LM_L_03_CRC 2;
BA_ "GenSigSendType" SG_ 2527679510 LED_Feh_LM_L_03_BZ 0;
BA_ "GenSigFuncType" SG_ 2527679510 LED_Feh_LM_L_03_BZ 1;
BA_ "GenSigSendType" SG_ 2527679510 LED_L_Abbiegel_Def 0;
BA_ "GenSigSendType" SG_ 2527679510 LED_L_Abblendl_Def 0;
BA_ "GenSigSendType" SG_ 2527679510 LED_L_Allg_Elektr_Def 0;
BA_ "GenSigSendType" SG_ 2527679510 LED_L_Fernl_Def 0;
BA_ "GenSigSendType" SG_ 2527679510 LED_L_falsch_codiert 0;
BA_ "GenSigSendType" SG_ 2527679510 LED_L_Zus_Fernl_LH_Def 0;
BA_ "GenSigSendType" SG_ 2527679510 LED_L_Laser_Def 0;
BA_ "GenSigSendType" SG_ 1341 LED_R_Abbiegel_Def_1 0;
BA_ "Fehlerwert" SG_ 1341 LED_R_Abbiegel_Def_1 1;
BA_ "GenSigSendType" SG_ 1341 LED_R_Abbiegel_Def_2 0;
BA_ "Fehlerwert" SG_ 1341 LED_R_Abbiegel_Def_2 1;
BA_ "GenSigSendType" SG_ 1341 LED_R_Abbiegel_Def_3 0;
BA_ "Fehlerwert" SG_ 1341 LED_R_Abbiegel_Def_3 1;
BA_ "GenSigSendType" SG_ 1341 LED_R_Abbiegel_Def_4 0;
BA_ "Fehlerwert" SG_ 1341 LED_R_Abbiegel_Def_4 1;
BA_ "GenSigSendType" SG_ 1341 LED_R_Abbiegel_Def_5 0;
BA_ "Fehlerwert" SG_ 1341 LED_R_Abbiegel_Def_5 1;
BA_ "GenSigSendType" SG_ 1341 LED_R_Abbiegel_Def_6 0;
BA_ "Fehlerwert" SG_ 1341 LED_R_Abbiegel_Def_6 1;
BA_ "GenSigSendType" SG_ 1341 LED_R_Abbiegel_Def_7 0;
BA_ "Fehlerwert" SG_ 1341 LED_R_Abbiegel_Def_7 1;
BA_ "GenSigSendType" SG_ 1341 LED_R_Abbiegel_Def_Err_Gultig 0;
BA_ "GenSigSendType" SG_ 1341 LED_R_Abblendl_Def_1 0;
BA_ "Fehlerwert" SG_ 1341 LED_R_Abblendl_Def_1 1;
BA_ "GenSigSendType" SG_ 1341 LED_R_Abblendl_Def_2 0;
BA_ "Fehlerwert" SG_ 1341 LED_R_Abblendl_Def_2 1;
BA_ "GenSigSendType" SG_ 1341 LED_R_Abblendl_Def_3 0;
BA_ "Fehlerwert" SG_ 1341 LED_R_Abblendl_Def_3 1;
BA_ "GenSigSendType" SG_ 1341 LED_R_Abblendl_Def_4 0;
BA_ "Fehlerwert" SG_ 1341 LED_R_Abblendl_Def_4 1;
BA_ "GenSigSendType" SG_ 1341 LED_R_Abblendl_Def_5 0;
BA_ "Fehlerwert" SG_ 1341 LED_R_Abblendl_Def_5 1;
BA_ "GenSigSendType" SG_ 1341 LED_R_Abblendl_Def_6 0;
BA_ "Fehlerwert" SG_ 1341 LED_R_Abblendl_Def_6 1;
BA_ "GenSigSendType" SG_ 1341 LED_R_Abblendl_Def_7 0;
BA_ "Fehlerwert" SG_ 1341 LED_R_Abblendl_Def_7 1;
BA_ "GenSigSendType" SG_ 1341 LED_R_Abblendl_Def_Err_Gultig 0;
BA_ "GenSigSendType" SG_ 1341 LED_R_Fernl_Def_1 0;
BA_ "Fehlerwert" SG_ 1341 LED_R_Fernl_Def_1 1;
BA_ "GenSigSendType" SG_ 1341 LED_R_Fernl_Def_2 0;
BA_ "Fehlerwert" SG_ 1341 LED_R_Fernl_Def_2 1;
BA_ "GenSigSendType" SG_ 1341 LED_R_Fernl_Def_3 0;
BA_ "Fehlerwert" SG_ 1341 LED_R_Fernl_Def_3 1;
BA_ "GenSigSendType" SG_ 1341 LED_R_Fernl_Def_4 0;
BA_ "Fehlerwert" SG_ 1341 LED_R_Fernl_Def_4 1;
BA_ "GenSigSendType" SG_ 1341 LED_R_Fernl_Def_5 0;
BA_ "Fehlerwert" SG_ 1341 LED_R_Fernl_Def_5 1;
BA_ "GenSigSendType" SG_ 1341 LED_R_Fernl_Def_6 0;
BA_ "Fehlerwert" SG_ 1341 LED_R_Fernl_Def_6 1;
BA_ "GenSigSendType" SG_ 1341 LED_R_Fernl_Def_7 0;
BA_ "Fehlerwert" SG_ 1341 LED_R_Fernl_Def_7 1;
BA_ "GenSigSendType" SG_ 1341 LED_R_Fernl_Def_Err_Gultig 0;
BA_ "GenSigSendType" SG_ 1341 LED_R_TFL_Def_1 0;
BA_ "Fehlerwert" SG_ 1341 LED_R_TFL_Def_1 1;
BA_ "GenSigSendType" SG_ 1341 LED_R_TFL_Def_2 0;
BA_ "Fehlerwert" SG_ 1341 LED_R_TFL_Def_2 1;
BA_ "GenSigSendType" SG_ 1341 LED_R_TFL_Def_3 0;
BA_ "Fehlerwert" SG_ 1341 LED_R_TFL_Def_3 1;
BA_ "GenSigSendType" SG_ 1341 LED_R_TFL_Def_4 0;
BA_ "Fehlerwert" SG_ 1341 LED_R_TFL_Def_4 1;
BA_ "GenSigSendType" SG_ 1341 LED_R_TFL_Def_5 0;
BA_ "Fehlerwert" SG_ 1341 LED_R_TFL_Def_5 1;
BA_ "GenSigSendType" SG_ 1341 LED_R_TFL_Def_6 0;
BA_ "Fehlerwert" SG_ 1341 LED_R_TFL_Def_6 1;
BA_ "GenSigSendType" SG_ 1341 LED_R_TFL_Def_7 0;
BA_ "Fehlerwert" SG_ 1341 LED_R_TFL_Def_7 1;
BA_ "GenSigSendType" SG_ 1341 LED_R_TFL_Def_Err_Gultig 0;
BA_ "GenSigSendType" SG_ 1341 LED_R_Allg_Elektr_Def_1 0;
BA_ "Fehlerwert" SG_ 1341 LED_R_Allg_Elektr_Def_1 1;
BA_ "GenSigSendType" SG_ 1341 LED_R_Allg_Elektr_Def_2 0;
BA_ "Fehlerwert" SG_ 1341 LED_R_Allg_Elektr_Def_2 1;
BA_ "GenSigSendType" SG_ 1341 LED_R_Allg_Elektr_Def_3 0;
BA_ "Fehlerwert" SG_ 1341 LED_R_Allg_Elektr_Def_3 1;
BA_ "GenSigSendType" SG_ 1341 LED_R_Allg_Elektr_Def_4 0;
BA_ "Fehlerwert" SG_ 1341 LED_R_Allg_Elektr_Def_4 1;
BA_ "GenSigSendType" SG_ 1341 LED_R_Allg_Elektr_Def_5 0;
BA_ "Fehlerwert" SG_ 1341 LED_R_Allg_Elektr_Def_5 1;
BA_ "GenSigSendType" SG_ 1341 LED_R_Allg_Elektr_Def_6 0;
BA_ "Fehlerwert" SG_ 1341 LED_R_Allg_Elektr_Def_6 1;
BA_ "GenSigSendType" SG_ 1341 LED_R_Allg_Elektr_Def_7 0;
BA_ "Fehlerwert" SG_ 1341 LED_R_Allg_Elektr_Def_7 1;
BA_ "GenSigSendType" SG_ 1341 LED_R_Allg_Elektr_Def_8 0;
BA_ "Fehlerwert" SG_ 1341 LED_R_Allg_Elektr_Def_8 1;
BA_ "GenSigSendType" SG_ 1341 LED_R_Allg_Elektr_Def_Err_Gultig 0;
BA_ "GenSigSendType" SG_ 1341 LED_R_Luefter_1_Def_1 0;
BA_ "Fehlerwert" SG_ 1341 LED_R_Luefter_1_Def_1 1;
BA_ "GenSigSendType" SG_ 1341 LED_R_Luefter_1_Def_2 0;
BA_ "Fehlerwert" SG_ 1341 LED_R_Luefter_1_Def_2 1;
BA_ "GenSigSendType" SG_ 1341 LED_R_Luefter_1_Def_3 0;
BA_ "Fehlerwert" SG_ 1341 LED_R_Luefter_1_Def_3 1;
BA_ "GenSigSendType" SG_ 1341 LED_R_Luefter_1_Def_4 0;
BA_ "Fehlerwert" SG_ 1341 LED_R_Luefter_1_Def_4 1;
BA_ "GenSigSendType" SG_ 1341 LED_R_Luefter_2_Def_1 0;
BA_ "Fehlerwert" SG_ 1341 LED_R_Luefter_2_Def_1 1;
BA_ "GenSigSendType" SG_ 1341 LED_R_Luefter_2_Def_2 0;
BA_ "Fehlerwert" SG_ 1341 LED_R_Luefter_2_Def_2 1;
BA_ "GenSigSendType" SG_ 1341 LED_R_Luefter_2_Def_3 0;
BA_ "Fehlerwert" SG_ 1341 LED_R_Luefter_2_Def_3 1;
BA_ "GenSigSendType" SG_ 1341 LED_R_Luefter_2_Def_4 0;
BA_ "Fehlerwert" SG_ 1341 LED_R_Luefter_2_Def_4 1;
BA_ "GenSigSendType" SG_ 1341 LED_R_Luefter_1_Def_Err_Gultig 0;
BA_ "GenSigSendType" SG_ 1341 LED_R_Luefter_2_Def_Err_Gultig 0;
BA_ "GenSigSendType" SG_ 1341 LED_R_ECE_SAE_Umschaltung_Def 0;
BA_ "Fehlerwert" SG_ 1341 LED_R_ECE_SAE_Umschaltung_Def 1;
BA_ "GenSigSendType" SG_ 2527679495 LED_R_Nebel_All_Def_1 0;
BA_ "Fehlerwert" SG_ 2527679495 LED_R_Nebel_All_Def_1 1;
BA_ "GenSigSendType" SG_ 2527679495 LED_R_Nebel_All_Def_2 0;
BA_ "Fehlerwert" SG_ 2527679495 LED_R_Nebel_All_Def_2 1;
BA_ "GenSigSendType" SG_ 2527679495 LED_R_Nebel_All_Def_3 0;
BA_ "Fehlerwert" SG_ 2527679495 LED_R_Nebel_All_Def_3 1;
BA_ "GenSigSendType" SG_ 2527679495 LED_R_Nebel_All_Def_4 0;
BA_ "Fehlerwert" SG_ 2527679495 LED_R_Nebel_All_Def_4 1;
BA_ "GenSigSendType" SG_ 2527679495 LED_R_Nebel_All_Def_5 0;
BA_ "Fehlerwert" SG_ 2527679495 LED_R_Nebel_All_Def_5 1;
BA_ "GenSigSendType" SG_ 2527679495 LED_R_Nebel_All_Def_6 0;
BA_ "Fehlerwert" SG_ 2527679495 LED_R_Nebel_All_Def_6 1;
BA_ "GenSigSendType" SG_ 2527679495 LED_R_Nebel_All_Def_7 0;
BA_ "Fehlerwert" SG_ 2527679495 LED_R_Nebel_All_Def_7 1;
BA_ "GenSigSendType" SG_ 2527679495 LED_R_Nebel_All_Def_Err_Gultig 0;
BA_ "GenSigSendType" SG_ 2527679495 LED_R_Touristenl_Def_1 0;
BA_ "Fehlerwert" SG_ 2527679495 LED_R_Touristenl_Def_1 1;
BA_ "GenSigSendType" SG_ 2527679495 LED_R_Touristenl_Def_2 0;
BA_ "Fehlerwert" SG_ 2527679495 LED_R_Touristenl_Def_2 1;
BA_ "GenSigSendType" SG_ 2527679495 LED_R_Touristenl_Def_3 0;
BA_ "Fehlerwert" SG_ 2527679495 LED_R_Touristenl_Def_3 1;
BA_ "GenSigSendType" SG_ 2527679495 LED_R_Touristenl_Def_4 0;
BA_ "Fehlerwert" SG_ 2527679495 LED_R_Touristenl_Def_4 1;
BA_ "GenSigSendType" SG_ 2527679495 LED_R_Touristenl_Def_5 0;
BA_ "Fehlerwert" SG_ 2527679495 LED_R_Touristenl_Def_5 1;
BA_ "GenSigSendType" SG_ 2527679495 LED_R_Touristenl_Def_6 0;
BA_ "Fehlerwert" SG_ 2527679495 LED_R_Touristenl_Def_6 1;
BA_ "GenSigSendType" SG_ 2527679495 LED_R_Touristenl_Def_7 0;
BA_ "Fehlerwert" SG_ 2527679495 LED_R_Touristenl_Def_7 1;
BA_ "GenSigSendType" SG_ 2527679495 LED_R_Touristenl_Def_Err_Gultig 0;
BA_ "GenSigSendType" SG_ 2527679495 LED_R_Autobahnl_Def_1 0;
BA_ "Fehlerwert" SG_ 2527679495 LED_R_Autobahnl_Def_1 1;
BA_ "GenSigSendType" SG_ 2527679495 LED_R_Autobahnl_Def_2 0;
BA_ "Fehlerwert" SG_ 2527679495 LED_R_Autobahnl_Def_2 1;
BA_ "GenSigSendType" SG_ 2527679495 LED_R_Autobahnl_Def_3 0;
BA_ "Fehlerwert" SG_ 2527679495 LED_R_Autobahnl_Def_3 1;
BA_ "GenSigSendType" SG_ 2527679495 LED_R_Autobahnl_Def_4 0;
BA_ "Fehlerwert" SG_ 2527679495 LED_R_Autobahnl_Def_4 1;
BA_ "GenSigSendType" SG_ 2527679495 LED_R_Autobahnl_Def_5 0;
BA_ "Fehlerwert" SG_ 2527679495 LED_R_Autobahnl_Def_5 1;
BA_ "GenSigSendType" SG_ 2527679495 LED_R_Autobahnl_Def_6 0;
BA_ "Fehlerwert" SG_ 2527679495 LED_R_Autobahnl_Def_6 1;
BA_ "GenSigSendType" SG_ 2527679495 LED_R_Autobahnl_Def_7 0;
BA_ "Fehlerwert" SG_ 2527679495 LED_R_Autobahnl_Def_7 1;
BA_ "GenSigSendType" SG_ 2527679495 LED_R_Autobahnl_Def_Err_Gultig 0;
BA_ "GenSigSendType" SG_ 2527679495 LED_R_Rennl_Def_1 0;
BA_ "Fehlerwert" SG_ 2527679495 LED_R_Rennl_Def_1 1;
BA_ "GenSigSendType" SG_ 2527679495 LED_R_Rennl_Def_2 0;
BA_ "Fehlerwert" SG_ 2527679495 LED_R_Rennl_Def_2 1;
BA_ "GenSigSendType" SG_ 2527679495 LED_R_Rennl_Def_3 0;
BA_ "Fehlerwert" SG_ 2527679495 LED_R_Rennl_Def_3 1;
BA_ "GenSigSendType" SG_ 2527679495 LED_R_Rennl_Def_4 0;
BA_ "Fehlerwert" SG_ 2527679495 LED_R_Rennl_Def_4 1;
BA_ "GenSigSendType" SG_ 2527679495 LED_R_Rennl_Def_5 0;
BA_ "Fehlerwert" SG_ 2527679495 LED_R_Rennl_Def_5 1;
BA_ "GenSigSendType" SG_ 2527679495 LED_R_Rennl_Def_6 0;
BA_ "Fehlerwert" SG_ 2527679495 LED_R_Rennl_Def_6 1;
BA_ "GenSigSendType" SG_ 2527679495 LED_R_Rennl_Def_7 0;
BA_ "Fehlerwert" SG_ 2527679495 LED_R_Rennl_Def_7 1;
BA_ "GenSigSendType" SG_ 2527679495 LED_R_Rennl_Def_Err_Gultig 0;
BA_ "GenSigSendType" SG_ 2527679495 LED_R_Stadtl_Def_1 0;
BA_ "Fehlerwert" SG_ 2527679495 LED_R_Stadtl_Def_1 1;
BA_ "GenSigSendType" SG_ 2527679495 LED_R_Stadtl_Def_2 0;
BA_ "Fehlerwert" SG_ 2527679495 LED_R_Stadtl_Def_2 1;
BA_ "GenSigSendType" SG_ 2527679495 LED_R_Stadtl_Def_3 0;
BA_ "Fehlerwert" SG_ 2527679495 LED_R_Stadtl_Def_3 1;
BA_ "GenSigSendType" SG_ 2527679495 LED_R_Stadtl_Def_4 0;
BA_ "Fehlerwert" SG_ 2527679495 LED_R_Stadtl_Def_4 1;
BA_ "GenSigSendType" SG_ 2527679495 LED_R_Stadtl_Def_5 0;
BA_ "Fehlerwert" SG_ 2527679495 LED_R_Stadtl_Def_5 1;
BA_ "GenSigSendType" SG_ 2527679495 LED_R_Stadtl_Def_6 0;
BA_ "Fehlerwert" SG_ 2527679495 LED_R_Stadtl_Def_6 1;
BA_ "GenSigSendType" SG_ 2527679495 LED_R_Stadtl_Def_7 0;
BA_ "Fehlerwert" SG_ 2527679495 LED_R_Stadtl_Def_7 1;
BA_ "GenSigSendType" SG_ 2527679495 LED_R_Stadtl_Def_Err_Gultig 0;
BA_ "GenSigSendType" SG_ 2527679511 LED_Feh_LM_R_03_CRC 0;
BA_ "GenSigFuncType" SG_ 2527679511 LED_Feh_LM_R_03_CRC 2;
BA_ "GenSigSendType" SG_ 2527679511 LED_Feh_LM_R_03_BZ 0;
BA_ "GenSigFuncType" SG_ 2527679511 LED_Feh_LM_R_03_BZ 1;
BA_ "GenSigSendType" SG_ 2527679511 LED_R_Abbiegel_Def 0;
BA_ "GenSigSendType" SG_ 2527679511 LED_R_Abblendl_Def 0;
BA_ "GenSigSendType" SG_ 2527679511 LED_R_Allg_Elektr_Def 0;
BA_ "GenSigSendType" SG_ 2527679511 LED_R_Fernl_Def 0;
BA_ "GenSigSendType" SG_ 2527679511 LED_R_falsch_codiert 0;
BA_ "GenSigSendType" SG_ 2527679511 LED_R_Zus_Fernl_LH_Def 0;
BA_ "GenSigSendType" SG_ 2527679511 LED_R_Laser_Def 0;
BA_ "GenSigSendType" SG_ 1422 LED_L_Mux 0;
BA_ "GenSigSendType" SG_ 1421 LED_R_Mux 0;
BA_ "GenSigSendType" SG_ 1290 LED_L_Scheinw_Var_1 0;
BA_ "GenSigSendType" SG_ 1290 LED_L_Scheinw_Var_2 0;
BA_ "GenSigSendType" SG_ 1291 LED_R_Scheinw_Var_1 0;
BA_ "GenSigSendType" SG_ 1291 LED_R_Scheinw_Var_2 0;
BA_ "GenSigSendType" SG_ 2589283615 LED_L_DABL_LED_01_Anf 3;
BA_ "GenSigSendType" SG_ 2589283615 LED_L_DABL_LED_02_Anf 3;
BA_ "GenSigSendType" SG_ 2589283615 LED_L_DABL_LED_03_Anf 3;
BA_ "GenSigSendType" SG_ 2589283615 LED_L_DABL_LED_04_Anf 3;
BA_ "GenSigSendType" SG_ 2589283615 LED_L_DABL_LED_05_Anf 3;
BA_ "GenSigSendType" SG_ 2589283615 LED_L_DABL_LED_06_Anf 3;
BA_ "GenSigSendType" SG_ 2589283615 LED_L_DABL_LED_07_Anf 3;
BA_ "GenSigSendType" SG_ 2589283615 LED_L_DABL_LED_08_Anf 3;
BA_ "GenSigSendType" SG_ 2589283615 LED_L_DABL_LED_09_Anf 3;
BA_ "GenSigSendType" SG_ 2589283615 LED_L_DABL_LED_10_Anf 3;
BA_ "GenSigSendType" SG_ 2463978600 LED_L_DABL_LED_11_Anf 3;
BA_ "GenSigSendType" SG_ 2463978600 LED_L_DABL_LED_12_Anf 3;
BA_ "GenSigSendType" SG_ 2463978600 LED_L_DABL_LED_13_Anf 3;
BA_ "GenSigSendType" SG_ 2463978600 LED_L_DABL_LED_14_Anf 3;
BA_ "GenSigSendType" SG_ 2463978600 LED_L_DABL_LED_15_Anf 3;
BA_ "GenSigSendType" SG_ 2463978600 LED_L_DABL_LED_16_Anf 3;
BA_ "GenSigSendType" SG_ 2463978600 LED_L_DABL_LED_17_Anf 3;
BA_ "GenSigSendType" SG_ 2463978600 LED_L_DABL_LED_18_Anf 3;
BA_ "GenSigSendType" SG_ 2463978600 LED_L_DABL_LED_19_Anf 3;
BA_ "GenSigSendType" SG_ 2463978600 LED_L_DABL_LED_20_Anf 3;
BA_ "GenSigSendType" SG_ 836 LED_L_SABL_LED_01_Anf 3;
BA_ "GenSigSendType" SG_ 836 LED_L_SABL_LED_02_Anf 3;
BA_ "GenSigSendType" SG_ 836 LED_L_SABL_LED_03_Anf 3;
BA_ "GenSigSendType" SG_ 836 LED_L_SABL_LED_04_Anf 3;
BA_ "GenSigSendType" SG_ 836 LED_L_SABL_LED_05_Anf 3;
BA_ "GenSigSendType" SG_ 836 LED_L_SABL_LED_06_Anf 3;
BA_ "GenSigSendType" SG_ 836 LED_L_SABL_LED_07_Anf 3;
BA_ "GenSigSendType" SG_ 836 LED_L_SABL_LED_08_Anf 3;
BA_ "GenSigSendType" SG_ 836 LED_L_SABL_LED_09_Anf 3;
BA_ "GenSigSendType" SG_ 836 LED_L_SABL_LED_10_Anf 3;
BA_REL_ "GenSigTimeoutTime" BU_SG_REL_ AFS SG_ 1342 LED_L_Abbiegel_Def_1 2000;
BA_REL_ "GenSigTimeoutTime" BU_SG_REL_ BCM1 SG_ 1342 LED_L_Abbiegel_Def_1 2000;
BA_REL_ "GenSigTimeoutTime" BU_SG_REL_ FCM SG_ 1342 LED_L_Abbiegel_Def_1 2000;
BA_REL_ "GenSigTimeoutTime" BU_SG_REL_ MXB SG_ 1342 LED_L_Abbiegel_Def_1 2000;
BA_REL_ "GenSigTimeoutTime" BU_SG_REL_ AFS SG_ 1342 LED_L_Abbiegel_Def_2 2000;
BA_REL_ "GenSigTimeoutTime" BU_SG_REL_ BCM1 SG_ 1342 LED_L_Abbiegel_Def_2 2000;
BA_REL_ "GenSigTimeoutTime" BU_SG_REL_ FCM SG_ 1342 LED_L_Abbiegel_Def_2 2000;
BA_REL_ "GenSigTimeoutTime" BU_SG_REL_ MXB SG_ 1342 LED_L_Abbiegel_Def_2 2000;
BA_REL_ "GenSigTimeoutTime" BU_SG_REL_ AFS SG_ 1342 LED_L_Abbiegel_Def_3 2000;
BA_REL_ "GenSigTimeoutTime" BU_SG_REL_ BCM1 SG_ 1342 LED_L_Abbiegel_Def_3 2000;
BA_REL_ "GenSigTimeoutTime" BU_SG_REL_ FCM SG_ 1342 LED_L_Abbiegel_Def_3 2000;
BA_REL_ "GenSigTimeoutTime" BU_SG_REL_ MXB SG_ 1342 LED_L_Abbiegel_Def_3 2000;
BA_REL_ "GenSigTimeoutTime" BU_SG_REL_ AFS SG_ 1342 LED_L_Abbiegel_Def_4 2000;
BA_REL_ "GenSigTimeoutTime" BU_SG_REL_ BCM1 SG_ 1342 LED_L_Abbiegel_Def_4 2000;
BA_REL_ "GenSigTimeoutTime" BU_SG_REL_ FCM SG_ 1342 LED_L_Abbiegel_Def_4 2000;
BA_REL_ "GenSigTimeoutTime" BU_SG_REL_ MXB SG_ 1342 LED_L_Abbiegel_Def_4 2000;
BA_REL_ "GenSigTimeoutTime" BU_SG_REL_ AFS SG_ 1342 LED_L_Abbiegel_Def_5 2000;
BA_REL_ "GenSigTimeoutTime" BU_SG_REL_ BCM1 SG_ 1342 LED_L_Abbiegel_Def_5 2000;
BA_REL_ "GenSigTimeoutTime" BU_SG_REL_ FCM SG_ 1342 LED_L_Abbiegel_Def_5 2000;
BA_REL_ "GenSigTimeoutTime" BU_SG_REL_ MXB SG_ 1342 LED_L_Abbiegel_Def_5 2000;
BA_REL_ "GenSigTimeoutTime" BU_SG_REL_ AFS SG_ 1342 LED_L_Abbiegel_Def_6 2000;
BA_REL_ "GenSigTimeoutTime" BU_SG_REL_ BCM1 SG_ 1342 LED_L_Abbiegel_Def_6 2000;
BA_REL_ "GenSigTimeoutTime" BU_SG_REL_ FCM SG_ 1342 LED_L_Abbiegel_Def_6 2000;
BA_REL_ "GenSigTimeoutTime" BU_SG_REL_ MXB SG_ 1342 LED_L_Abbiegel_Def_6 2000;
BA_REL_ "GenSigTimeoutTime" BU_SG_REL_ AFS SG_ 1342 LED_L_Abbiegel_Def_7 2000;
BA_REL_ "GenSigTimeoutTime" BU_SG_REL_ BCM1 SG_ 1342 LED_L_Abbiegel_Def_7 2000;
BA_REL_ "GenSigTimeoutTime" BU_SG_REL_ FCM SG_ 1342 LED_L_Abbiegel_Def_7 2000;
BA_REL_ "GenSigTimeoutTime" BU_SG_REL_ MXB SG_ 1342 LED_L_Abbiegel_Def_7 2000;
BA_REL_ "GenSigTimeoutTime" BU_SG_REL_ AFS SG_ 1342 LED_L_Abbiegel_Def_Err_Gultig 2000;
BA_REL_ "GenSigTimeoutTime" BU_SG_REL_ BCM1 SG_ 1342 LED_L_Abbiegel_Def_Err_Gultig 2000;
BA_REL_ "GenSigTimeoutTime" BU_SG_REL_ FCM SG_ 1342 LED_L_Abbiegel_Def_Err_Gultig 2000;
BA_REL_ "GenSigTimeoutTime" BU_SG_REL_ MXB SG_ 1342 LED_L_Abbiegel_Def_Err_Gultig 2000;
BA_REL_ "GenSigTimeoutTime" BU_SG_REL_ AFS SG_ 1342 LED_L_Abblendl_Def_1 2000;
BA_REL_ "GenSigTimeoutTime" BU_SG_REL_ BCM1 SG_ 1342 LED_L_Abblendl_Def_1 2000;
BA_REL_ "GenSigTimeoutTime" BU_SG_REL_ FCM SG_ 1342 LED_L_Abblendl_Def_1 2000;
BA_REL_ "GenSigTimeoutTime" BU_SG_REL_ MXB SG_ 1342 LED_L_Abblendl_Def_1 2000;
BA_REL_ "GenSigTimeoutTime" BU_SG_REL_ AFS SG_ 1342 LED_L_Abblendl_Def_2 2000;
BA_REL_ "GenSigTimeoutTime" BU_SG_REL_ BCM1 SG_ 1342 LED_L_Abblendl_Def_2 2000;
BA_REL_ "GenSigTimeoutTime" BU_SG_REL_ FCM SG_ 1342 LED_L_Abblendl_Def_2 2000;
BA_REL_ "GenSigTimeoutTime" BU_SG_REL_ MXB SG_ 1342 LED_L_Abblendl_Def_2 2000;
BA_REL_ "GenSigTimeoutTime" BU_SG_REL_ AFS SG_ 1342 LED_L_Abblendl_Def_3 2000;
BA_REL_ "GenSigTimeoutTime" BU_SG_REL_ BCM1 SG_ 1342 LED_L_Abblendl_Def_3 2000;
BA_REL_ "GenSigTimeoutTime" BU_SG_REL_ FCM SG_ 1342 LED_L_Abblendl_Def_3 2000;
BA_REL_ "GenSigTimeoutTime" BU_SG_REL_ MXB SG_ 1342 LED_L_Abblendl_Def_3 2000;
BA_REL_ "GenSigTimeoutTime" BU_SG_REL_ AFS SG_ 1342 LED_L_Abblendl_Def_4 2000;
BA_REL_ "GenSigTimeoutTime" BU_SG_REL_ BCM1 SG_ 1342 LED_L_Abblendl_Def_4 2000;
BA_REL_ "GenSigTimeoutTime" BU_SG_REL_ FCM SG_ 1342 LED_L_Abblendl_Def_4 2000;
BA_REL_ "GenSigTimeoutTime" BU_SG_REL_ MXB SG_ 1342 LED_L_Abblendl_Def_4 2000;
BA_REL_ "GenSigTimeoutTime" BU_SG_REL_ AFS SG_ 1342 LED_L_Abblendl_Def_5 2000;
BA_REL_ "GenSigTimeoutTime" BU_SG_REL_ BCM1 SG_ 1342 LED_L_Abblendl_Def_5 2000;
BA_REL_ "GenSigTimeoutTime" BU_SG_REL_ FCM SG_ 1342 LED_L_Abblendl_Def_5 2000;
BA_REL_ "GenSigTimeoutTime" BU_SG_REL_ MXB SG_ 1342 LED_L_Abblendl_Def_5 2000;
BA_REL_ "GenSigTimeoutTime" BU_SG_REL_ AFS SG_ 1342 LED_L_Abblendl_Def_6 2000;
BA_REL_ "GenSigTimeoutTime" BU_SG_REL_ BCM1 SG_ 1342 LED_L_Abblendl_Def_6 2000;
BA_REL_ "GenSigTimeoutTime" BU_SG_REL_ FCM SG_ 1342 LED_L_Abblendl_Def_6 2000;
BA_REL_ "GenSigTimeoutTime" BU_SG_REL_ MXB SG_ 1342 LED_L_Abblendl_Def_6 2000;
BA_REL_ "GenSigTimeoutTime" BU_SG_REL_ AFS SG_ 1342 LED_L_Abblendl_Def_7 2000;
BA_REL_ "GenSigTimeoutTime" BU_SG_REL_ BCM1 SG_ 1342 LED_L_Abblendl_Def_7 2000;
BA_REL_ "GenSigTimeoutTime" BU_SG_REL_ FCM SG_ 1342 LED_L_Abblendl_Def_7 2000;
BA_REL_ "GenSigTimeoutTime" BU_SG_REL_ MXB SG_ 1342 LED_L_Abblendl_Def_7 2000;
BA_REL_ "GenSigTimeoutTime" BU_SG_REL_ AFS SG_ 1342 LED_L_Abblendl_Def_Err_Gultig 2000;
BA_REL_ "GenSigTimeoutTime" BU_SG_REL_ BCM1 SG_ 1342 LED_L_Abblendl_Def_Err_Gultig 2000;
BA_REL_ "GenSigTimeoutTime" BU_SG_REL_ FCM SG_ 1342 LED_L_Abblendl_Def_Err_Gultig 2000;
BA_REL_ "GenSigTimeoutTime" BU_SG_REL_ MXB SG_ 1342 LED_L_Abblendl_Def_Err_Gultig 2000;
BA_REL_ "GenSigTimeoutTime" BU_SG_REL_ AFS SG_ 1342 LED_L_Fernl_Def_1 2000;
BA_REL_ "GenSigTimeoutTime" BU_SG_REL_ BCM1 SG_ 1342 LED_L_Fernl_Def_1 2000;
BA_REL_ "GenSigTimeoutTime" BU_SG_REL_ FCM SG_ 1342 LED_L_Fernl_Def_1 2000;
BA_REL_ "GenSigTimeoutTime" BU_SG_REL_ MXB SG_ 1342 LED_L_Fernl_Def_1 2000;
BA_REL_ "GenSigTimeoutTime" BU_SG_REL_ AFS SG_ 1342 LED_L_Fernl_Def_2 2000;
BA_REL_ "GenSigTimeoutTime" BU_SG_REL_ BCM1 SG_ 1342 LED_L_Fernl_Def_2 2000;
BA_REL_ "GenSigTimeoutTime" BU_SG_REL_ FCM SG_ 1342 LED_L_Fernl_Def_2 2000;
BA_REL_ "GenSigTimeoutTime" BU_SG_REL_ MXB SG_ 1342 LED_L_Fernl_Def_2 2000;
BA_REL_ "GenSigTimeoutTime" BU_SG_REL_ AFS SG_ 1342 LED_L_Fernl_Def_3 2000;
BA_REL_ "GenSigTimeoutTime" BU_SG_REL_ BCM1 SG_ 1342 LED_L_Fernl_Def_3 2000;
BA_REL_ "GenSigTimeoutTime" BU_SG_REL_ FCM SG_ 1342 LED_L_Fernl_Def_3 2000;
BA_REL_ "GenSigTimeoutTime" BU_SG_REL_ MXB SG_ 1342 LED_L_Fernl_Def_3 2000;
BA_REL_ "GenSigTimeoutTime" BU_SG_REL_ AFS SG_ 1342 LED_L_Fernl_Def_4 2000;
BA_REL_ "GenSigTimeoutTime" BU_SG_REL_ BCM1 SG_ 1342 LED_L_Fernl_Def_4 2000;
BA_REL_ "GenSigTimeoutTime" BU_SG_REL_ FCM SG_ 1342 LED_L_Fernl_Def_4 2000;
BA_REL_ "GenSigTimeoutTime" BU_SG_REL_ MXB SG_ 1342 LED_L_Fernl_Def_4 2000;
BA_REL_ "GenSigTimeoutTime" BU_SG_REL_ AFS SG_ 1342 LED_L_Fernl_Def_5 2000;
BA_REL_ "GenSigTimeoutTime" BU_SG_REL_ BCM1 SG_ 1342 LED_L_Fernl_Def_5 2000;
BA_REL_ "GenSigTimeoutTime" BU_SG_REL_ FCM SG_ 1342 LED_L_Fernl_Def_5 2000;
BA_REL_ "GenSigTimeoutTime" BU_SG_REL_ MXB SG_ 1342 LED_L_Fernl_Def_5 2000;
BA_REL_ "GenSigTimeoutTime" BU_SG_REL_ AFS SG_ 1342 LED_L_Fernl_Def_6 2000;
BA_REL_ "GenSigTimeoutTime" BU_SG_REL_ BCM1 SG_ 1342 LED_L_Fernl_Def_6 2000;
BA_REL_ "GenSigTimeoutTime" BU_SG_REL_ FCM SG_ 1342 LED_L_Fernl_Def_6 2000;
BA_REL_ "GenSigTimeoutTime" BU_SG_REL_ MXB SG_ 1342 LED_L_Fernl_Def_6 2000;
BA_REL_ "GenSigTimeoutTime" BU_SG_REL_ AFS SG_ 1342 LED_L_Fernl_Def_7 2000;
BA_REL_ "GenSigTimeoutTime" BU_SG_REL_ BCM1 SG_ 1342 LED_L_Fernl_Def_7 2000;
BA_REL_ "GenSigTimeoutTime" BU_SG_REL_ FCM SG_ 1342 LED_L_Fernl_Def_7 2000;
BA_REL_ "GenSigTimeoutTime" BU_SG_REL_ MXB SG_ 1342 LED_L_Fernl_Def_7 2000;
BA_REL_ "GenSigTimeoutTime" BU_SG_REL_ AFS SG_ 1342 LED_L_Fernl_Def_Err_Gultig 2000;
BA_REL_ "GenSigTimeoutTime" BU_SG_REL_ BCM1 SG_ 1342 LED_L_Fernl_Def_Err_Gultig 2000;
BA_REL_ "GenSigTimeoutTime" BU_SG_REL_ FCM SG_ 1342 LED_L_Fernl_Def_Err_Gultig 2000;
BA_REL_ "GenSigTimeoutTime" BU_SG_REL_ MXB SG_ 1342 LED_L_Fernl_Def_Err_Gultig 2000;
BA_REL_ "GenSigTimeoutTime" BU_SG_REL_ AFS SG_ 1342 LED_L_TFL_Def_1 2000;
BA_REL_ "GenSigTimeoutTime" BU_SG_REL_ BCM1 SG_ 1342 LED_L_TFL_Def_1 2000;
BA_REL_ "GenSigTimeoutTime" BU_SG_REL_ FCM SG_ 1342 LED_L_TFL_Def_1 2000;
BA_REL_ "GenSigTimeoutTime" BU_SG_REL_ MXB SG_ 1342 LED_L_TFL_Def_1 2000;
BA_REL_ "GenSigTimeoutTime" BU_SG_REL_ AFS SG_ 1342 LED_L_TFL_Def_2 2000;
BA_REL_ "GenSigTimeoutTime" BU_SG_REL_ BCM1 SG_ 1342 LED_L_TFL_Def_2 2000;
BA_REL_ "GenSigTimeoutTime" BU_SG_REL_ FCM SG_ 1342 LED_L_TFL_Def_2 2000;
BA_REL_ "GenSigTimeoutTime" BU_SG_REL_ MXB SG_ 1342 LED_L_TFL_Def_2 2000;
BA_REL_ "GenSigTimeoutTime" BU_SG_REL_ AFS SG_ 1342 LED_L_TFL_Def_3 2000;
BA_REL_ "GenSigTimeoutTime" BU_SG_REL_ BCM1 SG_ 1342 LED_L_TFL_Def_3 2000;
BA_REL_ "GenSigTimeoutTime" BU_SG_REL_ FCM SG_ 1342 LED_L_TFL_Def_3 2000;
BA_REL_ "GenSigTimeoutTime" BU_SG_REL_ MXB SG_ 1342 LED_L_TFL_Def_3 2000;
BA_REL_ "GenSigTimeoutTime" BU_SG_REL_ AFS SG_ 1342 LED_L_TFL_Def_4 2000;
BA_REL_ "GenSigTimeoutTime" BU_SG_REL_ BCM1 SG_ 1342 LED_L_TFL_Def_4 2000;
BA_REL_ "GenSigTimeoutTime" BU_SG_REL_ FCM SG_ 1342 LED_L_TFL_Def_4 2000;
BA_REL_ "GenSigTimeoutTime" BU_SG_REL_ MXB SG_ 1342 LED_L_TFL_Def_4 2000;
BA_REL_ "GenSigTimeoutTime" BU_SG_REL_ AFS SG_ 1342 LED_L_TFL_Def_5 2000;
BA_REL_ "GenSigTimeoutTime" BU_SG_REL_ BCM1 SG_ 1342 LED_L_TFL_Def_5 2000;
BA_REL_ "GenSigTimeoutTime" BU_SG_REL_ FCM SG_ 1342 LED_L_TFL_Def_5 2000;
BA_REL_ "GenSigTimeoutTime" BU_SG_REL_ MXB SG_ 1342 LED_L_TFL_Def_5 2000;
BA_REL_ "GenSigTimeoutTime" BU_SG_REL_ AFS SG_ 1342 LED_L_TFL_Def_6 2000;
BA_REL_ "GenSigTimeoutTime" BU_SG_REL_ BCM1 SG_ 1342 LED_L_TFL_Def_6 2000;
BA_REL_ "GenSigTimeoutTime" BU_SG_REL_ FCM SG_ 1342 LED_L_TFL_Def_6 2000;
BA_REL_ "GenSigTimeoutTime" BU_SG_REL_ MXB SG_ 1342 LED_L_TFL_Def_6 2000;
BA_REL_ "GenSigTimeoutTime" BU_SG_REL_ AFS SG_ 1342 LED_L_TFL_Def_7 2000;
BA_REL_ "GenSigTimeoutTime" BU_SG_REL_ BCM1 SG_ 1342 LED_L_TFL_Def_7 2000;
BA_REL_ "GenSigTimeoutTime" BU_SG_REL_ FCM SG_ 1342 LED_L_TFL_Def_7 2000;
BA_REL_ "GenSigTimeoutTime" BU_SG_REL_ MXB SG_ 1342 LED_L_TFL_Def_7 2000;
BA_REL_ "GenSigTimeoutTime" BU_SG_REL_ AFS SG_ 1342 LED_L_TFL_Def_Err_Gultig 2000;
BA_REL_ "GenSigTimeoutTime" BU_SG_REL_ BCM1 SG_ 1342 LED_L_TFL_Def_Err_Gultig 2000;
BA_REL_ "GenSigTimeoutTime" BU_SG_REL_ FCM SG_ 1342 LED_L_TFL_Def_Err_Gultig 2000;
BA_REL_ "GenSigTimeoutTime" BU_SG_REL_ MXB SG_ 1342 LED_L_TFL_Def_Err_Gultig 2000;
BA_REL_ "GenSigTimeoutTime" BU_SG_REL_ AFS SG_ 1342 LED_L_Allg_Elektr_Def_1 2000;
BA_REL_ "GenSigTimeoutTime" BU_SG_REL_ BCM1 SG_ 1342 LED_L_Allg_Elektr_Def_1 2000;
BA_REL_ "GenSigTimeoutTime" BU_SG_REL_ FCM SG_ 1342 LED_L_Allg_Elektr_Def_1 2000;
BA_REL_ "GenSigTimeoutTime" BU_SG_REL_ MXB SG_ 1342 LED_L_Allg_Elektr_Def_1 2000;
BA_REL_ "GenSigTimeoutTime" BU_SG_REL_ AFS SG_ 1342 LED_L_Allg_Elektr_Def_2 2000;
BA_REL_ "GenSigTimeoutTime" BU_SG_REL_ BCM1 SG_ 1342 LED_L_Allg_Elektr_Def_2 2000;
BA_REL_ "GenSigTimeoutTime" BU_SG_REL_ FCM SG_ 1342 LED_L_Allg_Elektr_Def_2 2000;
BA_REL_ "GenSigTimeoutTime" BU_SG_REL_ MXB SG_ 1342 LED_L_Allg_Elektr_Def_2 2000;
BA_REL_ "GenSigTimeoutTime" BU_SG_REL_ AFS SG_ 1342 LED_L_Allg_Elektr_Def_3 2000;
BA_REL_ "GenSigTimeoutTime" BU_SG_REL_ BCM1 SG_ 1342 LED_L_Allg_Elektr_Def_3 2000;
BA_REL_ "GenSigTimeoutTime" BU_SG_REL_ FCM SG_ 1342 LED_L_Allg_Elektr_Def_3 2000;
BA_REL_ "GenSigTimeoutTime" BU_SG_REL_ MXB SG_ 1342 LED_L_Allg_Elektr_Def_3 2000;
BA_REL_ "GenSigTimeoutTime" BU_SG_REL_ AFS SG_ 1342 LED_L_Allg_Elektr_Def_4 2000;
BA_REL_ "GenSigTimeoutTime" BU_SG_REL_ BCM1 SG_ 1342 LED_L_Allg_Elektr_Def_4 2000;
BA_REL_ "GenSigTimeoutTime" BU_SG_REL_ FCM SG_ 1342 LED_L_Allg_Elektr_Def_4 2000;
BA_REL_ "GenSigTimeoutTime" BU_SG_REL_ MXB SG_ 1342 LED_L_Allg_Elektr_Def_4 2000;
BA_REL_ "GenSigTimeoutTime" BU_SG_REL_ AFS SG_ 1342 LED_L_Allg_Elektr_Def_5 2000;
BA_REL_ "GenSigTimeoutTime" BU_SG_REL_ BCM1 SG_ 1342 LED_L_Allg_Elektr_Def_5 2000;
BA_REL_ "GenSigTimeoutTime" BU_SG_REL_ FCM SG_ 1342 LED_L_Allg_Elektr_Def_5 2000;
BA_REL_ "GenSigTimeoutTime" BU_SG_REL_ MXB SG_ 1342 LED_L_Allg_Elektr_Def_5 2000;
BA_REL_ "GenSigTimeoutTime" BU_SG_REL_ AFS SG_ 1342 LED_L_Allg_Elektr_Def_6 2000;
BA_REL_ "GenSigTimeoutTime" BU_SG_REL_ BCM1 SG_ 1342 LED_L_Allg_Elektr_Def_6 2000;
BA_REL_ "GenSigTimeoutTime" BU_SG_REL_ FCM SG_ 1342 LED_L_Allg_Elektr_Def_6 2000;
BA_REL_ "GenSigTimeoutTime" BU_SG_REL_ MXB SG_ 1342 LED_L_Allg_Elektr_Def_6 2000;
BA_REL_ "GenSigTimeoutTime" BU_SG_REL_ AFS SG_ 1342 LED_L_Allg_Elektr_Def_7 2000;
BA_REL_ "GenSigTimeoutTime" BU_SG_REL_ BCM1 SG_ 1342 LED_L_Allg_Elektr_Def_7 2000;
BA_REL_ "GenSigTimeoutTime" BU_SG_REL_ FCM SG_ 1342 LED_L_Allg_Elektr_Def_7 2000;
BA_REL_ "GenSigTimeoutTime" BU_SG_REL_ MXB SG_ 1342 LED_L_Allg_Elektr_Def_7 2000;
BA_REL_ "GenSigTimeoutTime" BU_SG_REL_ AFS SG_ 1342 LED_L_Allg_Elektr_Def_8 2000;
BA_REL_ "GenSigTimeoutTime" BU_SG_REL_ BCM1 SG_ 1342 LED_L_Allg_Elektr_Def_8 2000;
BA_REL_ "GenSigTimeoutTime" BU_SG_REL_ FCM SG_ 1342 LED_L_Allg_Elektr_Def_8 2000;
BA_REL_ "GenSigTimeoutTime" BU_SG_REL_ MXB SG_ 1342 LED_L_Allg_Elektr_Def_8 2000;
BA_REL_ "GenSigTimeoutTime" BU_SG_REL_ AFS SG_ 1342 LED_L_Allg_Elektr_Def_Err_Gultig 2000;
BA_REL_ "GenSigTimeoutTime" BU_SG_REL_ BCM1 SG_ 1342 LED_L_Allg_Elektr_Def_Err_Gultig 2000;
BA_REL_ "GenSigTimeoutTime" BU_SG_REL_ FCM SG_ 1342 LED_L_Allg_Elektr_Def_Err_Gultig 2000;
BA_REL_ "GenSigTimeoutTime" BU_SG_REL_ MXB SG_ 1342 LED_L_Allg_Elektr_Def_Err_Gultig 2000;
BA_REL_ "GenSigTimeoutTime" BU_SG_REL_ AFS SG_ 1342 LED_L_Luefter_1_Def_1 2000;
BA_REL_ "GenSigTimeoutTime" BU_SG_REL_ BCM1 SG_ 1342 LED_L_Luefter_1_Def_1 2000;
BA_REL_ "GenSigTimeoutTime" BU_SG_REL_ FCM SG_ 1342 LED_L_Luefter_1_Def_1 2000;
BA_REL_ "GenSigTimeoutTime" BU_SG_REL_ MXB SG_ 1342 LED_L_Luefter_1_Def_1 2000;
BA_REL_ "GenSigTimeoutTime" BU_SG_REL_ AFS SG_ 1342 LED_L_Luefter_1_Def_2 2000;
BA_REL_ "GenSigTimeoutTime" BU_SG_REL_ BCM1 SG_ 1342 LED_L_Luefter_1_Def_2 2000;
BA_REL_ "GenSigTimeoutTime" BU_SG_REL_ FCM SG_ 1342 LED_L_Luefter_1_Def_2 2000;
BA_REL_ "GenSigTimeoutTime" BU_SG_REL_ MXB SG_ 1342 LED_L_Luefter_1_Def_2 2000;
BA_REL_ "GenSigTimeoutTime" BU_SG_REL_ AFS SG_ 1342 LED_L_Luefter_1_Def_3 2000;
BA_REL_ "GenSigTimeoutTime" BU_SG_REL_ BCM1 SG_ 1342 LED_L_Luefter_1_Def_3 2000;
BA_REL_ "GenSigTimeoutTime" BU_SG_REL_ FCM SG_ 1342 LED_L_Luefter_1_Def_3 2000;
BA_REL_ "GenSigTimeoutTime" BU_SG_REL_ MXB SG_ 1342 LED_L_Luefter_1_Def_3 2000;
BA_REL_ "GenSigTimeoutTime" BU_SG_REL_ AFS SG_ 1342 LED_L_Luefter_1_Def_4 2000;
BA_REL_ "GenSigTimeoutTime" BU_SG_REL_ BCM1 SG_ 1342 LED_L_Luefter_1_Def_4 2000;
BA_REL_ "GenSigTimeoutTime" BU_SG_REL_ FCM SG_ 1342 LED_L_Luefter_1_Def_4 2000;
BA_REL_ "GenSigTimeoutTime" BU_SG_REL_ MXB SG_ 1342 LED_L_Luefter_1_Def_4 2000;
BA_REL_ "GenSigTimeoutTime" BU_SG_REL_ AFS SG_ 1342 LED_L_Luefter_2_Def_1 2000;
BA_REL_ "GenSigTimeoutTime" BU_SG_REL_ BCM1 SG_ 1342 LED_L_Luefter_2_Def_1 2000;
BA_REL_ "GenSigTimeoutTime" BU_SG_REL_ FCM SG_ 1342 LED_L_Luefter_2_Def_1 2000;
BA_REL_ "GenSigTimeoutTime" BU_SG_REL_ MXB SG_ 1342 LED_L_Luefter_2_Def_1 2000;
BA_REL_ "GenSigTimeoutTime" BU_SG_REL_ AFS SG_ 1342 LED_L_Luefter_2_Def_2 2000;
BA_REL_ "GenSigTimeoutTime" BU_SG_REL_ BCM1 SG_ 1342 LED_L_Luefter_2_Def_2 2000;
BA_REL_ "GenSigTimeoutTime" BU_SG_REL_ FCM SG_ 1342 LED_L_Luefter_2_Def_2 2000;
BA_REL_ "GenSigTimeoutTime" BU_SG_REL_ MXB SG_ 1342 LED_L_Luefter_2_Def_2 2000;
BA_REL_ "GenSigTimeoutTime" BU_SG_REL_ AFS SG_ 1342 LED_L_Luefter_2_Def_3 2000;
BA_REL_ "GenSigTimeoutTime" BU_SG_REL_ BCM1 SG_ 1342 LED_L_Luefter_2_Def_3 2000;
BA_REL_ "GenSigTimeoutTime" BU_SG_REL_ FCM SG_ 1342 LED_L_Luefter_2_Def_3 2000;
BA_REL_ "GenSigTimeoutTime" BU_SG_REL_ MXB SG_ 1342 LED_L_Luefter_2_Def_3 2000;
BA_REL_ "GenSigTimeoutTime" BU_SG_REL_ AFS SG_ 1342 LED_L_Luefter_2_Def_4 2000;
BA_REL_ "GenSigTimeoutTime" BU_SG_REL_ BCM1 SG_ 1342 LED_L_Luefter_2_Def_4 2000;
BA_REL_ "GenSigTimeoutTime" BU_SG_REL_ FCM SG_ 1342 LED_L_Luefter_2_Def_4 2000;
BA_REL_ "GenSigTimeoutTime" BU_SG_REL_ MXB SG_ 1342 LED_L_Luefter_2_Def_4 2000;
BA_REL_ "GenSigTimeoutTime" BU_SG_REL_ AFS SG_ 1342 LED_L_Luefter_1_Def_Err_Gultig 2000;
BA_REL_ "GenSigTimeoutTime" BU_SG_REL_ BCM1 SG_ 1342 LED_L_Luefter_1_Def_Err_Gultig 2000;
BA_REL_ "GenSigTimeoutTime" BU_SG_REL_ FCM SG_ 1342 LED_L_Luefter_1_Def_Err_Gultig 2000;
BA_REL_ "GenSigTimeoutTime" BU_SG_REL_ MXB SG_ 1342 LED_L_Luefter_1_Def_Err_Gultig 2000;
BA_REL_ "GenSigTimeoutTime" BU_SG_REL_ AFS SG_ 1342 LED_L_Luefter_2_Def_Err_Gultig 2000;
BA_REL_ "GenSigTimeoutTime" BU_SG_REL_ BCM1 SG_ 1342 LED_L_Luefter_2_Def_Err_Gultig 2000;
BA_REL_ "GenSigTimeoutTime" BU_SG_REL_ FCM SG_ 1342 LED_L_Luefter_2_Def_Err_Gultig 2000;
BA_REL_ "GenSigTimeoutTime" BU_SG_REL_ MXB SG_ 1342 LED_L_Luefter_2_Def_Err_Gultig 2000;
BA_REL_ "GenSigTimeoutTime" BU_SG_REL_ AFS SG_ 1342 LED_L_ECE_SAE_Umschaltung_Def 2000;
BA_REL_ "GenSigTimeoutTime" BU_SG_REL_ BCM1 SG_ 1342 LED_L_ECE_SAE_Umschaltung_Def 2000;
BA_REL_ "GenSigTimeoutTime" BU_SG_REL_ FCM SG_ 1342 LED_L_ECE_SAE_Umschaltung_Def 2000;
BA_REL_ "GenSigTimeoutTime" BU_SG_REL_ MXB SG_ 1342 LED_L_ECE_SAE_Umschaltung_Def 2000;
BA_REL_ "GenSigTimeoutTime" BU_SG_REL_ AFS SG_ 2527679494 LED_L_Nebel_All_Def_1 2000;
BA_REL_ "GenSigTimeoutTime" BU_SG_REL_ BCM1 SG_ 2527679494 LED_L_Nebel_All_Def_1 2000;
BA_REL_ "GenSigTimeoutTime" BU_SG_REL_ FCM SG_ 2527679494 LED_L_Nebel_All_Def_1 2000;
BA_REL_ "GenSigTimeoutTime" BU_SG_REL_ MXB SG_ 2527679494 LED_L_Nebel_All_Def_1 2000;
BA_REL_ "GenSigTimeoutTime" BU_SG_REL_ AFS SG_ 2527679494 LED_L_Nebel_All_Def_2 2000;
BA_REL_ "GenSigTimeoutTime" BU_SG_REL_ BCM1 SG_ 2527679494 LED_L_Nebel_All_Def_2 2000;
BA_REL_ "GenSigTimeoutTime" BU_SG_REL_ FCM SG_ 2527679494 LED_L_Nebel_All_Def_2 2000;
BA_REL_ "GenSigTimeoutTime" BU_SG_REL_ MXB SG_ 2527679494 LED_L_Nebel_All_Def_2 2000;
BA_REL_ "GenSigTimeoutTime" BU_SG_REL_ AFS SG_ 2527679494 LED_L_Nebel_All_Def_3 2000;
BA_REL_ "GenSigTimeoutTime" BU_SG_REL_ BCM1 SG_ 2527679494 LED_L_Nebel_All_Def_3 2000;
BA_REL_ "GenSigTimeoutTime" BU_SG_REL_ FCM SG_ 2527679494 LED_L_Nebel_All_Def_3 2000;
BA_REL_ "GenSigTimeoutTime" BU_SG_REL_ MXB SG_ 2527679494 LED_L_Nebel_All_Def_3 2000;
BA_REL_ "GenSigTimeoutTime" BU_SG_REL_ AFS SG_ 2527679494 LED_L_Nebel_All_Def_4 2000;
BA_REL_ "GenSigTimeoutTime" BU_SG_REL_ BCM1 SG_ 2527679494 LED_L_Nebel_All_Def_4 2000;
BA_REL_ "GenSigTimeoutTime" BU_SG_REL_ FCM SG_ 2527679494 LED_L_Nebel_All_Def_4 2000;
BA_REL_ "GenSigTimeoutTime" BU_SG_REL_ MXB SG_ 2527679494 LED_L_Nebel_All_Def_4 2000;
BA_REL_ "GenSigTimeoutTime" BU_SG_REL_ AFS SG_ 2527679494 LED_L_Nebel_All_Def_5 2000;
BA_REL_ "GenSigTimeoutTime" BU_SG_REL_ BCM1 SG_ 2527679494 LED_L_Nebel_All_Def_5 2000;
BA_REL_ "GenSigTimeoutTime" BU_SG_REL_ FCM SG_ 2527679494 LED_L_Nebel_All_Def_5 2000;
BA_REL_ "GenSigTimeoutTime" BU_SG_REL_ MXB SG_ 2527679494 LED_L_Nebel_All_Def_5 2000;
BA_REL_ "GenSigTimeoutTime" BU_SG_REL_ AFS SG_ 2527679494 LED_L_Nebel_All_Def_6 2000;
BA_REL_ "GenSigTimeoutTime" BU_SG_REL_ BCM1 SG_ 2527679494 LED_L_Nebel_All_Def_6 2000;
BA_REL_ "GenSigTimeoutTime" BU_SG_REL_ FCM SG_ 2527679494 LED_L_Nebel_All_Def_6 2000;
BA_REL_ "GenSigTimeoutTime" BU_SG_REL_ MXB SG_ 2527679494 LED_L_Nebel_All_Def_6 2000;
BA_REL_ "GenSigTimeoutTime" BU_SG_REL_ AFS SG_ 2527679494 LED_L_Nebel_All_Def_7 2000;
BA_REL_ "GenSigTimeoutTime" BU_SG_REL_ BCM1 SG_ 2527679494 LED_L_Nebel_All_Def_7 2000;
BA_REL_ "GenSigTimeoutTime" BU_SG_REL_ FCM SG_ 2527679494 LED_L_Nebel_All_Def_7 2000;
BA_REL_ "GenSigTimeoutTime" BU_SG_REL_ MXB SG_ 2527679494 LED_L_Nebel_All_Def_7 2000;
BA_REL_ "GenSigTimeoutTime" BU_SG_REL_ AFS SG_ 2527679494 LED_L_Nebel_All_Def_Err_Gultig 2000;
BA_REL_ "GenSigTimeoutTime" BU_SG_REL_ BCM1 SG_ 2527679494 LED_L_Nebel_All_Def_Err_Gultig 2000;
BA_REL_ "GenSigTimeoutTime" BU_SG_REL_ FCM SG_ 2527679494 LED_L_Nebel_All_Def_Err_Gultig 2000;
BA_REL_ "GenSigTimeoutTime" BU_SG_REL_ MXB SG_ 2527679494 LED_L_Nebel_All_Def_Err_Gultig 2000;
BA_REL_ "GenSigTimeoutTime" BU_SG_REL_ AFS SG_ 2527679494 LED_L_Touristenl_Def_1 2000;
BA_REL_ "GenSigTimeoutTime" BU_SG_REL_ BCM1 SG_ 2527679494 LED_L_Touristenl_Def_1 2000;
BA_REL_ "GenSigTimeoutTime" BU_SG_REL_ FCM SG_ 2527679494 LED_L_Touristenl_Def_1 2000;
BA_REL_ "GenSigTimeoutTime" BU_SG_REL_ MXB SG_ 2527679494 LED_L_Touristenl_Def_1 2000;
BA_REL_ "GenSigTimeoutTime" BU_SG_REL_ AFS SG_ 2527679494 LED_L_Touristenl_Def_2 2000;
BA_REL_ "GenSigTimeoutTime" BU_SG_REL_ BCM1 SG_ 2527679494 LED_L_Touristenl_Def_2 2000;
BA_REL_ "GenSigTimeoutTime" BU_SG_REL_ FCM SG_ 2527679494 LED_L_Touristenl_Def_2 2000;
BA_REL_ "GenSigTimeoutTime" BU_SG_REL_ MXB SG_ 2527679494 LED_L_Touristenl_Def_2 2000;
BA_REL_ "GenSigTimeoutTime" BU_SG_REL_ AFS SG_ 2527679494 LED_L_Touristenl_Def_3 2000;
BA_REL_ "GenSigTimeoutTime" BU_SG_REL_ BCM1 SG_ 2527679494 LED_L_Touristenl_Def_3 2000;
BA_REL_ "GenSigTimeoutTime" BU_SG_REL_ FCM SG_ 2527679494 LED_L_Touristenl_Def_3 2000;
BA_REL_ "GenSigTimeoutTime" BU_SG_REL_ MXB SG_ 2527679494 LED_L_Touristenl_Def_3 2000;
BA_REL_ "GenSigTimeoutTime" BU_SG_REL_ AFS SG_ 2527679494 LED_L_Touristenl_Def_4 2000;
BA_REL_ "GenSigTimeoutTime" BU_SG_REL_ BCM1 SG_ 2527679494 LED_L_Touristenl_Def_4 2000;
BA_REL_ "GenSigTimeoutTime" BU_SG_REL_ FCM SG_ 2527679494 LED_L_Touristenl_Def_4 2000;
BA_REL_ "GenSigTimeoutTime" BU_SG_REL_ MXB SG_ 2527679494 LED_L_Touristenl_Def_4 2000;
BA_REL_ "GenSigTimeoutTime" BU_SG_REL_ AFS SG_ 2527679494 LED_L_Touristenl_Def_5 2000;
BA_REL_ "GenSigTimeoutTime" BU_SG_REL_ BCM1 SG_ 2527679494 LED_L_Touristenl_Def_5 2000;
BA_REL_ "GenSigTimeoutTime" BU_SG_REL_ FCM SG_ 2527679494 LED_L_Touristenl_Def_5 2000;
BA_REL_ "GenSigTimeoutTime" BU_SG_REL_ MXB SG_ 2527679494 LED_L_Touristenl_Def_5 2000;
BA_REL_ "GenSigTimeoutTime" BU_SG_REL_ AFS SG_ 2527679494 LED_L_Touristenl_Def_6 2000;
BA_REL_ "GenSigTimeoutTime" BU_SG_REL_ BCM1 SG_ 2527679494 LED_L_Touristenl_Def_6 2000;
BA_REL_ "GenSigTimeoutTime" BU_SG_REL_ FCM SG_ 2527679494 LED_L_Touristenl_Def_6 2000;
BA_REL_ "GenSigTimeoutTime" BU_SG_REL_ MXB SG_ 2527679494 LED_L_Touristenl_Def_6 2000;
BA_REL_ "GenSigTimeoutTime" BU_SG_REL_ AFS SG_ 2527679494 LED_L_Touristenl_Def_7 2000;
BA_REL_ "GenSigTimeoutTime" BU_SG_REL_ BCM1 SG_ 2527679494 LED_L_Touristenl_Def_7 2000;
BA_REL_ "GenSigTimeoutTime" BU_SG_REL_ FCM SG_ 2527679494 LED_L_Touristenl_Def_7 2000;
BA_REL_ "GenSigTimeoutTime" BU_SG_REL_ MXB SG_ 2527679494 LED_L_Touristenl_Def_7 2000;
BA_REL_ "GenSigTimeoutTime" BU_SG_REL_ AFS SG_ 2527679494 LED_L_Touristenl_Def_Err_Gultig 2000;
BA_REL_ "GenSigTimeoutTime" BU_SG_REL_ BCM1 SG_ 2527679494 LED_L_Touristenl_Def_Err_Gultig 2000;
BA_REL_ "GenSigTimeoutTime" BU_SG_REL_ FCM SG_ 2527679494 LED_L_Touristenl_Def_Err_Gultig 2000;
BA_REL_ "GenSigTimeoutTime" BU_SG_REL_ MXB SG_ 2527679494 LED_L_Touristenl_Def_Err_Gultig 2000;
BA_REL_ "GenSigTimeoutTime" BU_SG_REL_ AFS SG_ 2527679494 LED_L_Autobahnl_Def_1 2000;
BA_REL_ "GenSigTimeoutTime" BU_SG_REL_ BCM1 SG_ 2527679494 LED_L_Autobahnl_Def_1 2000;
BA_REL_ "GenSigTimeoutTime" BU_SG_REL_ FCM SG_ 2527679494 LED_L_Autobahnl_Def_1 2000;
BA_REL_ "GenSigTimeoutTime" BU_SG_REL_ MXB SG_ 2527679494 LED_L_Autobahnl_Def_1 2000;
BA_REL_ "GenSigTimeoutTime" BU_SG_REL_ AFS SG_ 2527679494 LED_L_Autobahnl_Def_2 2000;
BA_REL_ "GenSigTimeoutTime" BU_SG_REL_ BCM1 SG_ 2527679494 LED_L_Autobahnl_Def_2 2000;
BA_REL_ "GenSigTimeoutTime" BU_SG_REL_ FCM SG_ 2527679494 LED_L_Autobahnl_Def_2 2000;
BA_REL_ "GenSigTimeoutTime" BU_SG_REL_ MXB SG_ 2527679494 LED_L_Autobahnl_Def_2 2000;
BA_REL_ "GenSigTimeoutTime" BU_SG_REL_ AFS SG_ 2527679494 LED_L_Autobahnl_Def_3 2000;
BA_REL_ "GenSigTimeoutTime" BU_SG_REL_ BCM1 SG_ 2527679494 LED_L_Autobahnl_Def_3 2000;
BA_REL_ "GenSigTimeoutTime" BU_SG_REL_ FCM SG_ 2527679494 LED_L_Autobahnl_Def_3 2000;
BA_REL_ "GenSigTimeoutTime" BU_SG_REL_ MXB SG_ 2527679494 LED_L_Autobahnl_Def_3 2000;
BA_REL_ "GenSigTimeoutTime" BU_SG_REL_ AFS SG_ 2527679494 LED_L_Autobahnl_Def_4 2000;
BA_REL_ "GenSigTimeoutTime" BU_SG_REL_ BCM1 SG_ 2527679494 LED_L_Autobahnl_Def_4 2000;
BA_REL_ "GenSigTimeoutTime" BU_SG_REL_ FCM SG_ 2527679494 LED_L_Autobahnl_Def_4 2000;
BA_REL_ "GenSigTimeoutTime" BU_SG_REL_ MXB SG_ 2527679494 LED_L_Autobahnl_Def_4 2000;
BA_REL_ "GenSigTimeoutTime" BU_SG_REL_ AFS SG_ 2527679494 LED_L_Autobahnl_Def_5 2000;
BA_REL_ "GenSigTimeoutTime" BU_SG_REL_ BCM1 SG_ 2527679494 LED_L_Autobahnl_Def_5 2000;
BA_REL_ "GenSigTimeoutTime" BU_SG_REL_ FCM SG_ 2527679494 LED_L_Autobahnl_Def_5 2000;
BA_REL_ "GenSigTimeoutTime" BU_SG_REL_ MXB SG_ 2527679494 LED_L_Autobahnl_Def_5 2000;
BA_REL_ "GenSigTimeoutTime" BU_SG_REL_ AFS SG_ 2527679494 LED_L_Autobahnl_Def_6 2000;
BA_REL_ "GenSigTimeoutTime" BU_SG_REL_ BCM1 SG_ 2527679494 LED_L_Autobahnl_Def_6 2000;
BA_REL_ "GenSigTimeoutTime" BU_SG_REL_ FCM SG_ 2527679494 LED_L_Autobahnl_Def_6 2000;
BA_REL_ "GenSigTimeoutTime" BU_SG_REL_ MXB SG_ 2527679494 LED_L_Autobahnl_Def_6 2000;
BA_REL_ "GenSigTimeoutTime" BU_SG_REL_ AFS SG_ 2527679494 LED_L_Autobahnl_Def_7 2000;
BA_REL_ "GenSigTimeoutTime" BU_SG_REL_ BCM1 SG_ 2527679494 LED_L_Autobahnl_Def_7 2000;
BA_REL_ "GenSigTimeoutTime" BU_SG_REL_ FCM SG_ 2527679494 LED_L_Autobahnl_Def_7 2000;
BA_REL_ "GenSigTimeoutTime" BU_SG_REL_ MXB SG_ 2527679494 LED_L_Autobahnl_Def_7 2000;
BA_REL_ "GenSigTimeoutTime" BU_SG_REL_ AFS SG_ 2527679494 LED_L_Autobahnl_Def_Err_Gultig 2000;
BA_REL_ "GenSigTimeoutTime" BU_SG_REL_ BCM1 SG_ 2527679494 LED_L_Autobahnl_Def_Err_Gultig 2000;
BA_REL_ "GenSigTimeoutTime" BU_SG_REL_ FCM SG_ 2527679494 LED_L_Autobahnl_Def_Err_Gultig 2000;
BA_REL_ "GenSigTimeoutTime" BU_SG_REL_ MXB SG_ 2527679494 LED_L_Autobahnl_Def_Err_Gultig 2000;
BA_REL_ "GenSigTimeoutTime" BU_SG_REL_ AFS SG_ 2527679494 LED_L_Rennl_Def_1 2000;
BA_REL_ "GenSigTimeoutTime" BU_SG_REL_ BCM1 SG_ 2527679494 LED_L_Rennl_Def_1 2000;
BA_REL_ "GenSigTimeoutTime" BU_SG_REL_ FCM SG_ 2527679494 LED_L_Rennl_Def_1 2000;
BA_REL_ "GenSigTimeoutTime" BU_SG_REL_ MXB SG_ 2527679494 LED_L_Rennl_Def_1 2000;
BA_REL_ "GenSigTimeoutTime" BU_SG_REL_ AFS SG_ 2527679494 LED_L_Rennl_Def_2 2000;
BA_REL_ "GenSigTimeoutTime" BU_SG_REL_ BCM1 SG_ 2527679494 LED_L_Rennl_Def_2 2000;
BA_REL_ "GenSigTimeoutTime" BU_SG_REL_ FCM SG_ 2527679494 LED_L_Rennl_Def_2 2000;
BA_REL_ "GenSigTimeoutTime" BU_SG_REL_ MXB SG_ 2527679494 LED_L_Rennl_Def_2 2000;
BA_REL_ "GenSigTimeoutTime" BU_SG_REL_ AFS SG_ 2527679494 LED_L_Rennl_Def_3 2000;
BA_REL_ "GenSigTimeoutTime" BU_SG_REL_ BCM1 SG_ 2527679494 LED_L_Rennl_Def_3 2000;
BA_REL_ "GenSigTimeoutTime" BU_SG_REL_ FCM SG_ 2527679494 LED_L_Rennl_Def_3 2000;
BA_REL_ "GenSigTimeoutTime" BU_SG_REL_ MXB SG_ 2527679494 LED_L_Rennl_Def_3 2000;
BA_REL_ "GenSigTimeoutTime" BU_SG_REL_ AFS SG_ 2527679494 LED_L_Rennl_Def_4 2000;
BA_REL_ "GenSigTimeoutTime" BU_SG_REL_ BCM1 SG_ 2527679494 LED_L_Rennl_Def_4 2000;
BA_REL_ "GenSigTimeoutTime" BU_SG_REL_ FCM SG_ 2527679494 LED_L_Rennl_Def_4 2000;
BA_REL_ "GenSigTimeoutTime" BU_SG_REL_ MXB SG_ 2527679494 LED_L_Rennl_Def_4 2000;
BA_REL_ "GenSigTimeoutTime" BU_SG_REL_ AFS SG_ 2527679494 LED_L_Rennl_Def_5 2000;
BA_REL_ "GenSigTimeoutTime" BU_SG_REL_ BCM1 SG_ 2527679494 LED_L_Rennl_Def_5 2000;
BA_REL_ "GenSigTimeoutTime" BU_SG_REL_ FCM SG_ 2527679494 LED_L_Rennl_Def_5 2000;
BA_REL_ "GenSigTimeoutTime" BU_SG_REL_ MXB SG_ 2527679494 LED_L_Rennl_Def_5 2000;
BA_REL_ "GenSigTimeoutTime" BU_SG_REL_ AFS SG_ 2527679494 LED_L_Rennl_Def_6 2000;
BA_REL_ "GenSigTimeoutTime" BU_SG_REL_ BCM1 SG_ 2527679494 LED_L_Rennl_Def_6 2000;
BA_REL_ "GenSigTimeoutTime" BU_SG_REL_ FCM SG_ 2527679494 LED_L_Rennl_Def_6 2000;
BA_REL_ "GenSigTimeoutTime" BU_SG_REL_ MXB SG_ 2527679494 LED_L_Rennl_Def_6 2000;
BA_REL_ "GenSigTimeoutTime" BU_SG_REL_ AFS SG_ 2527679494 LED_L_Rennl_Def_7 2000;
BA_REL_ "GenSigTimeoutTime" BU_SG_REL_ BCM1 SG_ 2527679494 LED_L_Rennl_Def_7 2000;
BA_REL_ "GenSigTimeoutTime" BU_SG_REL_ FCM SG_ 2527679494 LED_L_Rennl_Def_7 2000;
BA_REL_ "GenSigTimeoutTime" BU_SG_REL_ MXB SG_ 2527679494 LED_L_Rennl_Def_7 2000;
BA_REL_ "GenSigTimeoutTime" BU_SG_REL_ AFS SG_ 2527679494 LED_L_Rennl_Def_Err_Gultig 2000;
BA_REL_ "GenSigTimeoutTime" BU_SG_REL_ BCM1 SG_ 2527679494 LED_L_Rennl_Def_Err_Gultig 2000;
BA_REL_ "GenSigTimeoutTime" BU_SG_REL_ FCM SG_ 2527679494 LED_L_Rennl_Def_Err_Gultig 2000;
BA_REL_ "GenSigTimeoutTime" BU_SG_REL_ MXB SG_ 2527679494 LED_L_Rennl_Def_Err_Gultig 2000;
BA_REL_ "GenSigTimeoutTime" BU_SG_REL_ AFS SG_ 2527679494 LED_L_Stadtl_Def_1 2000;
BA_REL_ "GenSigTimeoutTime" BU_SG_REL_ BCM1 SG_ 2527679494 LED_L_Stadtl_Def_1 2000;
BA_REL_ "GenSigTimeoutTime" BU_SG_REL_ FCM SG_ 2527679494 LED_L_Stadtl_Def_1 2000;
BA_REL_ "GenSigTimeoutTime" BU_SG_REL_ MXB SG_ 2527679494 LED_L_Stadtl_Def_1 2000;
BA_REL_ "GenSigTimeoutTime" BU_SG_REL_ AFS SG_ 2527679494 LED_L_Stadtl_Def_2 2000;
BA_REL_ "GenSigTimeoutTime" BU_SG_REL_ BCM1 SG_ 2527679494 LED_L_Stadtl_Def_2 2000;
BA_REL_ "GenSigTimeoutTime" BU_SG_REL_ FCM SG_ 2527679494 LED_L_Stadtl_Def_2 2000;
BA_REL_ "GenSigTimeoutTime" BU_SG_REL_ MXB SG_ 2527679494 LED_L_Stadtl_Def_2 2000;
BA_REL_ "GenSigTimeoutTime" BU_SG_REL_ AFS SG_ 2527679494 LED_L_Stadtl_Def_3 2000;
BA_REL_ "GenSigTimeoutTime" BU_SG_REL_ BCM1 SG_ 2527679494 LED_L_Stadtl_Def_3 2000;
BA_REL_ "GenSigTimeoutTime" BU_SG_REL_ FCM SG_ 2527679494 LED_L_Stadtl_Def_3 2000;
BA_REL_ "GenSigTimeoutTime" BU_SG_REL_ MXB SG_ 2527679494 LED_L_Stadtl_Def_3 2000;
BA_REL_ "GenSigTimeoutTime" BU_SG_REL_ AFS SG_ 2527679494 LED_L_Stadtl_Def_4 2000;
BA_REL_ "GenSigTimeoutTime" BU_SG_REL_ BCM1 SG_ 2527679494 LED_L_Stadtl_Def_4 2000;
BA_REL_ "GenSigTimeoutTime" BU_SG_REL_ FCM SG_ 2527679494 LED_L_Stadtl_Def_4 2000;
BA_REL_ "GenSigTimeoutTime" BU_SG_REL_ MXB SG_ 2527679494 LED_L_Stadtl_Def_4 2000;
BA_REL_ "GenSigTimeoutTime" BU_SG_REL_ AFS SG_ 2527679494 LED_L_Stadtl_Def_5 2000;
BA_REL_ "GenSigTimeoutTime" BU_SG_REL_ BCM1 SG_ 2527679494 LED_L_Stadtl_Def_5 2000;
BA_REL_ "GenSigTimeoutTime" BU_SG_REL_ FCM SG_ 2527679494 LED_L_Stadtl_Def_5 2000;
BA_REL_ "GenSigTimeoutTime" BU_SG_REL_ MXB SG_ 2527679494 LED_L_Stadtl_Def_5 2000;
BA_REL_ "GenSigTimeoutTime" BU_SG_REL_ AFS SG_ 2527679494 LED_L_Stadtl_Def_6 2000;
BA_REL_ "GenSigTimeoutTime" BU_SG_REL_ BCM1 SG_ 2527679494 LED_L_Stadtl_Def_6 2000;
BA_REL_ "GenSigTimeoutTime" BU_SG_REL_ FCM SG_ 2527679494 LED_L_Stadtl_Def_6 2000;
BA_REL_ "GenSigTimeoutTime" BU_SG_REL_ MXB SG_ 2527679494 LED_L_Stadtl_Def_6 2000;
BA_REL_ "GenSigTimeoutTime" BU_SG_REL_ AFS SG_ 2527679494 LED_L_Stadtl_Def_7 2000;
BA_REL_ "GenSigTimeoutTime" BU_SG_REL_ BCM1 SG_ 2527679494 LED_L_Stadtl_Def_7 2000;
BA_REL_ "GenSigTimeoutTime" BU_SG_REL_ FCM SG_ 2527679494 LED_L_Stadtl_Def_7 2000;
BA_REL_ "GenSigTimeoutTime" BU_SG_REL_ MXB SG_ 2527679494 LED_L_Stadtl_Def_7 2000;
BA_REL_ "GenSigTimeoutTime" BU_SG_REL_ AFS SG_ 2527679494 LED_L_Stadtl_Def_Err_Gultig 2000;
BA_REL_ "GenSigTimeoutTime" BU_SG_REL_ BCM1 SG_ 2527679494 LED_L_Stadtl_Def_Err_Gultig 2000;
BA_REL_ "GenSigTimeoutTime" BU_SG_REL_ FCM SG_ 2527679494 LED_L_Stadtl_Def_Err_Gultig 2000;
BA_REL_ "GenSigTimeoutTime" BU_SG_REL_ MXB SG_ 2527679494 LED_L_Stadtl_Def_Err_Gultig 2000;
BA_REL_ "GenSigTimeoutTime" BU_SG_REL_ AFS SG_ 2527679510 LED_L_Abbiegel_Def 2000;
BA_REL_ "GenSigTimeoutTime" BU_SG_REL_ BCM1 SG_ 2527679510 LED_L_Abbiegel_Def 2000;
BA_REL_ "GenSigTimeoutTime" BU_SG_REL_ FCM SG_ 2527679510 LED_L_Abbiegel_Def 2000;
BA_REL_ "GenSigTimeoutTime" BU_SG_REL_ MXB SG_ 2527679510 LED_L_Abbiegel_Def 2000;
BA_REL_ "GenSigTimeoutTime" BU_SG_REL_ AFS SG_ 2527679510 LED_L_Abblendl_Def 2000;
BA_REL_ "GenSigTimeoutTime" BU_SG_REL_ BCM1 SG_ 2527679510 LED_L_Abblendl_Def 2000;
BA_REL_ "GenSigTimeoutTime" BU_SG_REL_ FCM SG_ 2527679510 LED_L_Abblendl_Def 2000;
BA_REL_ "GenSigTimeoutTime" BU_SG_REL_ LCM_L SG_ 2527679510 LED_L_Abblendl_Def 2000;
BA_REL_ "GenSigTimeoutTime" BU_SG_REL_ MXB SG_ 2527679510 LED_L_Abblendl_Def 2000;
BA_REL_ "GenSigTimeoutTime" BU_SG_REL_ AFS SG_ 2527679510 LED_L_Allg_Elektr_Def 2000;
BA_REL_ "GenSigTimeoutTime" BU_SG_REL_ BCM1 SG_ 2527679510 LED_L_Allg_Elektr_Def 2000;
BA_REL_ "GenSigTimeoutTime" BU_SG_REL_ FCM SG_ 2527679510 LED_L_Allg_Elektr_Def 2000;
BA_REL_ "GenSigTimeoutTime" BU_SG_REL_ MXB SG_ 2527679510 LED_L_Allg_Elektr_Def 2000;
BA_REL_ "GenSigTimeoutTime" BU_SG_REL_ AFS SG_ 2527679510 LED_L_Fernl_Def 2000;
BA_REL_ "GenSigTimeoutTime" BU_SG_REL_ BCM1 SG_ 2527679510 LED_L_Fernl_Def 2000;
BA_REL_ "GenSigTimeoutTime" BU_SG_REL_ FCM SG_ 2527679510 LED_L_Fernl_Def 2000;
BA_REL_ "GenSigTimeoutTime" BU_SG_REL_ MXB SG_ 2527679510 LED_L_Fernl_Def 2000;
BA_REL_ "GenSigTimeoutTime" BU_SG_REL_ AFS SG_ 2527679510 LED_L_falsch_codiert 2000;
BA_REL_ "GenSigTimeoutTime" BU_SG_REL_ BCM1 SG_ 2527679510 LED_L_falsch_codiert 2000;
BA_REL_ "GenSigTimeoutTime" BU_SG_REL_ FCM SG_ 2527679510 LED_L_falsch_codiert 2000;
BA_REL_ "GenSigTimeoutTime" BU_SG_REL_ MXB SG_ 2527679510 LED_L_falsch_codiert 2000;
BA_REL_ "GenSigTimeoutTime" BU_SG_REL_ AFS SG_ 2527679510 LED_L_Zus_Fernl_LH_Def 2000;
BA_REL_ "GenSigTimeoutTime" BU_SG_REL_ BCM1 SG_ 2527679510 LED_L_Zus_Fernl_LH_Def 2000;
BA_REL_ "GenSigTimeoutTime" BU_SG_REL_ FCM SG_ 2527679510 LED_L_Zus_Fernl_LH_Def 2000;
BA_REL_ "GenSigTimeoutTime" BU_SG_REL_ AFS SG_ 2527679510 LED_L_Laser_Def 2000;
BA_REL_ "GenSigTimeoutTime" BU_SG_REL_ BCM1 SG_ 2527679510 LED_L_Laser_Def 2000;
BA_REL_ "GenSigTimeoutTime" BU_SG_REL_ FCM SG_ 2527679510 LED_L_Laser_Def 2000;
BA_REL_ "GenSigTimeoutTime" BU_SG_REL_ AFS SG_ 1341 LED_R_Abbiegel_Def_1 2000;
BA_REL_ "GenSigTimeoutTime" BU_SG_REL_ BCM1 SG_ 1341 LED_R_Abbiegel_Def_1 2000;
BA_REL_ "GenSigTimeoutTime" BU_SG_REL_ FCM SG_ 1341 LED_R_Abbiegel_Def_1 2000;
BA_REL_ "GenSigTimeoutTime" BU_SG_REL_ MXB SG_ 1341 LED_R_Abbiegel_Def_1 2000;
BA_REL_ "GenSigTimeoutTime" BU_SG_REL_ AFS SG_ 1341 LED_R_Abbiegel_Def_2 2000;
BA_REL_ "GenSigTimeoutTime" BU_SG_REL_ BCM1 SG_ 1341 LED_R_Abbiegel_Def_2 2000;
BA_REL_ "GenSigTimeoutTime" BU_SG_REL_ FCM SG_ 1341 LED_R_Abbiegel_Def_2 2000;
BA_REL_ "GenSigTimeoutTime" BU_SG_REL_ MXB SG_ 1341 LED_R_Abbiegel_Def_2 2000;
BA_REL_ "GenSigTimeoutTime" BU_SG_REL_ AFS SG_ 1341 LED_R_Abbiegel_Def_3 2000;
BA_REL_ "GenSigTimeoutTime" BU_SG_REL_ BCM1 SG_ 1341 LED_R_Abbiegel_Def_3 2000;
BA_REL_ "GenSigTimeoutTime" BU_SG_REL_ FCM SG_ 1341 LED_R_Abbiegel_Def_3 2000;
BA_REL_ "GenSigTimeoutTime" BU_SG_REL_ MXB SG_ 1341 LED_R_Abbiegel_Def_3 2000;
BA_REL_ "GenSigTimeoutTime" BU_SG_REL_ AFS SG_ 1341 LED_R_Abbiegel_Def_4 2000;
BA_REL_ "GenSigTimeoutTime" BU_SG_REL_ BCM1 SG_ 1341 LED_R_Abbiegel_Def_4 2000;
BA_REL_ "GenSigTimeoutTime" BU_SG_REL_ FCM SG_ 1341 LED_R_Abbiegel_Def_4 2000;
BA_REL_ "GenSigTimeoutTime" BU_SG_REL_ MXB SG_ 1341 LED_R_Abbiegel_Def_4 2000;
BA_REL_ "GenSigTimeoutTime" BU_SG_REL_ AFS SG_ 1341 LED_R_Abbiegel_Def_5 2000;
BA_REL_ "GenSigTimeoutTime" BU_SG_REL_ BCM1 SG_ 1341 LED_R_Abbiegel_Def_5 2000;
BA_REL_ "GenSigTimeoutTime" BU_SG_REL_ FCM SG_ 1341 LED_R_Abbiegel_Def_5 2000;
BA_REL_ "GenSigTimeoutTime" BU_SG_REL_ MXB SG_ 1341 LED_R_Abbiegel_Def_5 2000;
BA_REL_ "GenSigTimeoutTime" BU_SG_REL_ AFS SG_ 1341 LED_R_Abbiegel_Def_6 2000;
BA_REL_ "GenSigTimeoutTime" BU_SG_REL_ BCM1 SG_ 1341 LED_R_Abbiegel_Def_6 2000;
BA_REL_ "GenSigTimeoutTime" BU_SG_REL_ FCM SG_ 1341 LED_R_Abbiegel_Def_6 2000;
BA_REL_ "GenSigTimeoutTime" BU_SG_REL_ MXB SG_ 1341 LED_R_Abbiegel_Def_6 2000;
BA_REL_ "GenSigTimeoutTime" BU_SG_REL_ AFS SG_ 1341 LED_R_Abbiegel_Def_7 2000;
BA_REL_ "GenSigTimeoutTime" BU_SG_REL_ BCM1 SG_ 1341 LED_R_Abbiegel_Def_7 2000;
BA_REL_ "GenSigTimeoutTime" BU_SG_REL_ FCM SG_ 1341 LED_R_Abbiegel_Def_7 2000;
BA_REL_ "GenSigTimeoutTime" BU_SG_REL_ MXB SG_ 1341 LED_R_Abbiegel_Def_7 2000;
BA_REL_ "GenSigTimeoutTime" BU_SG_REL_ AFS SG_ 1341 LED_R_Abbiegel_Def_Err_Gultig 2000;
BA_REL_ "GenSigTimeoutTime" BU_SG_REL_ BCM1 SG_ 1341 LED_R_Abbiegel_Def_Err_Gultig 2000;
BA_REL_ "GenSigTimeoutTime" BU_SG_REL_ FCM SG_ 1341 LED_R_Abbiegel_Def_Err_Gultig 2000;
BA_REL_ "GenSigTimeoutTime" BU_SG_REL_ MXB SG_ 1341 LED_R_Abbiegel_Def_Err_Gultig 2000;
BA_REL_ "GenSigTimeoutTime" BU_SG_REL_ AFS SG_ 1341 LED_R_Abblendl_Def_1 2000;
BA_REL_ "GenSigTimeoutTime" BU_SG_REL_ BCM1 SG_ 1341 LED_R_Abblendl_Def_1 2000;
BA_REL_ "GenSigTimeoutTime" BU_SG_REL_ FCM SG_ 1341 LED_R_Abblendl_Def_1 2000;
BA_REL_ "GenSigTimeoutTime" BU_SG_REL_ MXB SG_ 1341 LED_R_Abblendl_Def_1 2000;
BA_REL_ "GenSigTimeoutTime" BU_SG_REL_ AFS SG_ 1341 LED_R_Abblendl_Def_2 2000;
BA_REL_ "GenSigTimeoutTime" BU_SG_REL_ BCM1 SG_ 1341 LED_R_Abblendl_Def_2 2000;
BA_REL_ "GenSigTimeoutTime" BU_SG_REL_ FCM SG_ 1341 LED_R_Abblendl_Def_2 2000;
BA_REL_ "GenSigTimeoutTime" BU_SG_REL_ MXB SG_ 1341 LED_R_Abblendl_Def_2 2000;
BA_REL_ "GenSigTimeoutTime" BU_SG_REL_ AFS SG_ 1341 LED_R_Abblendl_Def_3 2000;
BA_REL_ "GenSigTimeoutTime" BU_SG_REL_ BCM1 SG_ 1341 LED_R_Abblendl_Def_3 2000;
BA_REL_ "GenSigTimeoutTime" BU_SG_REL_ FCM SG_ 1341 LED_R_Abblendl_Def_3 2000;
BA_REL_ "GenSigTimeoutTime" BU_SG_REL_ MXB SG_ 1341 LED_R_Abblendl_Def_3 2000;
BA_REL_ "GenSigTimeoutTime" BU_SG_REL_ AFS SG_ 1341 LED_R_Abblendl_Def_4 2000;
BA_REL_ "GenSigTimeoutTime" BU_SG_REL_ BCM1 SG_ 1341 LED_R_Abblendl_Def_4 2000;
BA_REL_ "GenSigTimeoutTime" BU_SG_REL_ FCM SG_ 1341 LED_R_Abblendl_Def_4 2000;
BA_REL_ "GenSigTimeoutTime" BU_SG_REL_ MXB SG_ 1341 LED_R_Abblendl_Def_4 2000;
BA_REL_ "GenSigTimeoutTime" BU_SG_REL_ AFS SG_ 1341 LED_R_Abblendl_Def_5 2000;
BA_REL_ "GenSigTimeoutTime" BU_SG_REL_ BCM1 SG_ 1341 LED_R_Abblendl_Def_5 2000;
BA_REL_ "GenSigTimeoutTime" BU_SG_REL_ FCM SG_ 1341 LED_R_Abblendl_Def_5 2000;
BA_REL_ "GenSigTimeoutTime" BU_SG_REL_ MXB SG_ 1341 LED_R_Abblendl_Def_5 2000;
BA_REL_ "GenSigTimeoutTime" BU_SG_REL_ AFS SG_ 1341 LED_R_Abblendl_Def_6 2000;
BA_REL_ "GenSigTimeoutTime" BU_SG_REL_ BCM1 SG_ 1341 LED_R_Abblendl_Def_6 2000;
BA_REL_ "GenSigTimeoutTime" BU_SG_REL_ FCM SG_ 1341 LED_R_Abblendl_Def_6 2000;
BA_REL_ "GenSigTimeoutTime" BU_SG_REL_ MXB SG_ 1341 LED_R_Abblendl_Def_6 2000;
BA_REL_ "GenSigTimeoutTime" BU_SG_REL_ AFS SG_ 1341 LED_R_Abblendl_Def_7 2000;
BA_REL_ "GenSigTimeoutTime" BU_SG_REL_ BCM1 SG_ 1341 LED_R_Abblendl_Def_7 2000;
BA_REL_ "GenSigTimeoutTime" BU_SG_REL_ FCM SG_ 1341 LED_R_Abblendl_Def_7 2000;
BA_REL_ "GenSigTimeoutTime" BU_SG_REL_ MXB SG_ 1341 LED_R_Abblendl_Def_7 2000;
BA_REL_ "GenSigTimeoutTime" BU_SG_REL_ AFS SG_ 1341 LED_R_Abblendl_Def_Err_Gultig 2000;
BA_REL_ "GenSigTimeoutTime" BU_SG_REL_ BCM1 SG_ 1341 LED_R_Abblendl_Def_Err_Gultig 2000;
BA_REL_ "GenSigTimeoutTime" BU_SG_REL_ FCM SG_ 1341 LED_R_Abblendl_Def_Err_Gultig 2000;
BA_REL_ "GenSigTimeoutTime" BU_SG_REL_ MXB SG_ 1341 LED_R_Abblendl_Def_Err_Gultig 2000;
BA_REL_ "GenSigTimeoutTime" BU_SG_REL_ AFS SG_ 1341 LED_R_Fernl_Def_1 2000;
BA_REL_ "GenSigTimeoutTime" BU_SG_REL_ BCM1 SG_ 1341 LED_R_Fernl_Def_1 2000;
BA_REL_ "GenSigTimeoutTime" BU_SG_REL_ FCM SG_ 1341 LED_R_Fernl_Def_1 2000;
BA_REL_ "GenSigTimeoutTime" BU_SG_REL_ MXB SG_ 1341 LED_R_Fernl_Def_1 2000;
BA_REL_ "GenSigTimeoutTime" BU_SG_REL_ AFS SG_ 1341 LED_R_Fernl_Def_2 2000;
BA_REL_ "GenSigTimeoutTime" BU_SG_REL_ BCM1 SG_ 1341 LED_R_Fernl_Def_2 2000;
BA_REL_ "GenSigTimeoutTime" BU_SG_REL_ FCM SG_ 1341 LED_R_Fernl_Def_2 2000;
BA_REL_ "GenSigTimeoutTime" BU_SG_REL_ MXB SG_ 1341 LED_R_Fernl_Def_2 2000;
BA_REL_ "GenSigTimeoutTime" BU_SG_REL_ AFS SG_ 1341 LED_R_Fernl_Def_3 2000;
BA_REL_ "GenSigTimeoutTime" BU_SG_REL_ BCM1 SG_ 1341 LED_R_Fernl_Def_3 2000;
BA_REL_ "GenSigTimeoutTime" BU_SG_REL_ FCM SG_ 1341 LED_R_Fernl_Def_3 2000;
BA_REL_ "GenSigTimeoutTime" BU_SG_REL_ MXB SG_ 1341 LED_R_Fernl_Def_3 2000;
BA_REL_ "GenSigTimeoutTime" BU_SG_REL_ AFS SG_ 1341 LED_R_Fernl_Def_4 2000;
BA_REL_ "GenSigTimeoutTime" BU_SG_REL_ BCM1 SG_ 1341 LED_R_Fernl_Def_4 2000;
BA_REL_ "GenSigTimeoutTime" BU_SG_REL_ FCM SG_ 1341 LED_R_Fernl_Def_4 2000;
BA_REL_ "GenSigTimeoutTime" BU_SG_REL_ MXB SG_ 1341 LED_R_Fernl_Def_4 2000;
BA_REL_ "GenSigTimeoutTime" BU_SG_REL_ AFS SG_ 1341 LED_R_Fernl_Def_5 2000;
BA_REL_ "GenSigTimeoutTime" BU_SG_REL_ BCM1 SG_ 1341 LED_R_Fernl_Def_5 2000;
BA_REL_ "GenSigTimeoutTime" BU_SG_REL_ FCM SG_ 1341 LED_R_Fernl_Def_5 2000;
BA_REL_ "GenSigTimeoutTime" BU_SG_REL_ MXB SG_ 1341 LED_R_Fernl_Def_5 2000;
BA_REL_ "GenSigTimeoutTime" BU_SG_REL_ AFS SG_ 1341 LED_R_Fernl_Def_6 2000;
BA_REL_ "GenSigTimeoutTime" BU_SG_REL_ BCM1 SG_ 1341 LED_R_Fernl_Def_6 2000;
BA_REL_ "GenSigTimeoutTime" BU_SG_REL_ FCM SG_ 1341 LED_R_Fernl_Def_6 2000;
BA_REL_ "GenSigTimeoutTime" BU_SG_REL_ MXB SG_ 1341 LED_R_Fernl_Def_6 2000;
BA_REL_ "GenSigTimeoutTime" BU_SG_REL_ AFS SG_ 1341 LED_R_Fernl_Def_7 2000;
BA_REL_ "GenSigTimeoutTime" BU_SG_REL_ BCM1 SG_ 1341 LED_R_Fernl_Def_7 2000;
BA_REL_ "GenSigTimeoutTime" BU_SG_REL_ FCM SG_ 1341 LED_R_Fernl_Def_7 2000;
BA_REL_ "GenSigTimeoutTime" BU_SG_REL_ MXB SG_ 1341 LED_R_Fernl_Def_7 2000;
BA_REL_ "GenSigTimeoutTime" BU_SG_REL_ AFS SG_ 1341 LED_R_Fernl_Def_Err_Gultig 2000;
BA_REL_ "GenSigTimeoutTime" BU_SG_REL_ BCM1 SG_ 1341 LED_R_Fernl_Def_Err_Gultig 2000;
BA_REL_ "GenSigTimeoutTime" BU_SG_REL_ FCM SG_ 1341 LED_R_Fernl_Def_Err_Gultig 2000;
BA_REL_ "GenSigTimeoutTime" BU_SG_REL_ MXB SG_ 1341 LED_R_Fernl_Def_Err_Gultig 2000;
BA_REL_ "GenSigTimeoutTime" BU_SG_REL_ AFS SG_ 1341 LED_R_TFL_Def_1 2000;
BA_REL_ "GenSigTimeoutTime" BU_SG_REL_ BCM1 SG_ 1341 LED_R_TFL_Def_1 2000;
BA_REL_ "GenSigTimeoutTime" BU_SG_REL_ FCM SG_ 1341 LED_R_TFL_Def_1 2000;
BA_REL_ "GenSigTimeoutTime" BU_SG_REL_ MXB SG_ 1341 LED_R_TFL_Def_1 2000;
BA_REL_ "GenSigTimeoutTime" BU_SG_REL_ AFS SG_ 1341 LED_R_TFL_Def_2 2000;
BA_REL_ "GenSigTimeoutTime" BU_SG_REL_ BCM1 SG_ 1341 LED_R_TFL_Def_2 2000;
BA_REL_ "GenSigTimeoutTime" BU_SG_REL_ FCM SG_ 1341 LED_R_TFL_Def_2 2000;
BA_REL_ "GenSigTimeoutTime" BU_SG_REL_ MXB SG_ 1341 LED_R_TFL_Def_2 2000;
BA_REL_ "GenSigTimeoutTime" BU_SG_REL_ AFS SG_ 1341 LED_R_TFL_Def_3 2000;
BA_REL_ "GenSigTimeoutTime" BU_SG_REL_ BCM1 SG_ 1341 LED_R_TFL_Def_3 2000;
BA_REL_ "GenSigTimeoutTime" BU_SG_REL_ FCM SG_ 1341 LED_R_TFL_Def_3 2000;
BA_REL_ "GenSigTimeoutTime" BU_SG_REL_ MXB SG_ 1341 LED_R_TFL_Def_3 2000;
BA_REL_ "GenSigTimeoutTime" BU_SG_REL_ AFS SG_ 1341 LED_R_TFL_Def_4 2000;
BA_REL_ "GenSigTimeoutTime" BU_SG_REL_ BCM1 SG_ 1341 LED_R_TFL_Def_4 2000;
BA_REL_ "GenSigTimeoutTime" BU_SG_REL_ FCM SG_ 1341 LED_R_TFL_Def_4 2000;
BA_REL_ "GenSigTimeoutTime" BU_SG_REL_ MXB SG_ 1341 LED_R_TFL_Def_4 2000;
BA_REL_ "GenSigTimeoutTime" BU_SG_REL_ AFS SG_ 1341 LED_R_TFL_Def_5 2000;
BA_REL_ "GenSigTimeoutTime" BU_SG_REL_ BCM1 SG_ 1341 LED_R_TFL_Def_5 2000;
BA_REL_ "GenSigTimeoutTime" BU_SG_REL_ FCM SG_ 1341 LED_R_TFL_Def_5 2000;
BA_REL_ "GenSigTimeoutTime" BU_SG_REL_ MXB SG_ 1341 LED_R_TFL_Def_5 2000;
BA_REL_ "GenSigTimeoutTime" BU_SG_REL_ AFS SG_ 1341 LED_R_TFL_Def_6 2000;
BA_REL_ "GenSigTimeoutTime" BU_SG_REL_ BCM1 SG_ 1341 LED_R_TFL_Def_6 2000;
BA_REL_ "GenSigTimeoutTime" BU_SG_REL_ FCM SG_ 1341 LED_R_TFL_Def_6 2000;
BA_REL_ "GenSigTimeoutTime" BU_SG_REL_ MXB SG_ 1341 LED_R_TFL_Def_6 2000;
BA_REL_ "GenSigTimeoutTime" BU_SG_REL_ AFS SG_ 1341 LED_R_TFL_Def_7 2000;
BA_REL_ "GenSigTimeoutTime" BU_SG_REL_ BCM1 SG_ 1341 LED_R_TFL_Def_7 2000;
BA_REL_ "GenSigTimeoutTime" BU_SG_REL_ FCM SG_ 1341 LED_R_TFL_Def_7 2000;
BA_REL_ "GenSigTimeoutTime" BU_SG_REL_ MXB SG_ 1341 LED_R_TFL_Def_7 2000;
BA_REL_ "GenSigTimeoutTime" BU_SG_REL_ AFS SG_ 1341 LED_R_TFL_Def_Err_Gultig 2000;
BA_REL_ "GenSigTimeoutTime" BU_SG_REL_ BCM1 SG_ 1341 LED_R_TFL_Def_Err_Gultig 2000;
BA_REL_ "GenSigTimeoutTime" BU_SG_REL_ FCM SG_ 1341 LED_R_TFL_Def_Err_Gultig 2000;
BA_REL_ "GenSigTimeoutTime" BU_SG_REL_ MXB SG_ 1341 LED_R_TFL_Def_Err_Gultig 2000;
BA_REL_ "GenSigTimeoutTime" BU_SG_REL_ AFS SG_ 1341 LED_R_Allg_Elektr_Def_1 2000;
BA_REL_ "GenSigTimeoutTime" BU_SG_REL_ BCM1 SG_ 1341 LED_R_Allg_Elektr_Def_1 2000;
BA_REL_ "GenSigTimeoutTime" BU_SG_REL_ FCM SG_ 1341 LED_R_Allg_Elektr_Def_1 2000;
BA_REL_ "GenSigTimeoutTime" BU_SG_REL_ MXB SG_ 1341 LED_R_Allg_Elektr_Def_1 2000;
BA_REL_ "GenSigTimeoutTime" BU_SG_REL_ AFS SG_ 1341 LED_R_Allg_Elektr_Def_2 2000;
BA_REL_ "GenSigTimeoutTime" BU_SG_REL_ BCM1 SG_ 1341 LED_R_Allg_Elektr_Def_2 2000;
BA_REL_ "GenSigTimeoutTime" BU_SG_REL_ FCM SG_ 1341 LED_R_Allg_Elektr_Def_2 2000;
BA_REL_ "GenSigTimeoutTime" BU_SG_REL_ MXB SG_ 1341 LED_R_Allg_Elektr_Def_2 2000;
BA_REL_ "GenSigTimeoutTime" BU_SG_REL_ AFS SG_ 1341 LED_R_Allg_Elektr_Def_3 2000;
BA_REL_ "GenSigTimeoutTime" BU_SG_REL_ BCM1 SG_ 1341 LED_R_Allg_Elektr_Def_3 2000;
BA_REL_ "GenSigTimeoutTime" BU_SG_REL_ FCM SG_ 1341 LED_R_Allg_Elektr_Def_3 2000;
BA_REL_ "GenSigTimeoutTime" BU_SG_REL_ MXB SG_ 1341 LED_R_Allg_Elektr_Def_3 2000;
BA_REL_ "GenSigTimeoutTime" BU_SG_REL_ AFS SG_ 1341 LED_R_Allg_Elektr_Def_4 2000;
BA_REL_ "GenSigTimeoutTime" BU_SG_REL_ BCM1 SG_ 1341 LED_R_Allg_Elektr_Def_4 2000;
BA_REL_ "GenSigTimeoutTime" BU_SG_REL_ FCM SG_ 1341 LED_R_Allg_Elektr_Def_4 2000;
BA_REL_ "GenSigTimeoutTime" BU_SG_REL_ MXB SG_ 1341 LED_R_Allg_Elektr_Def_4 2000;
BA_REL_ "GenSigTimeoutTime" BU_SG_REL_ AFS SG_ 1341 LED_R_Allg_Elektr_Def_5 2000;
BA_REL_ "GenSigTimeoutTime" BU_SG_REL_ BCM1 SG_ 1341 LED_R_Allg_Elektr_Def_5 2000;
BA_REL_ "GenSigTimeoutTime" BU_SG_REL_ FCM SG_ 1341 LED_R_Allg_Elektr_Def_5 2000;
BA_REL_ "GenSigTimeoutTime" BU_SG_REL_ MXB SG_ 1341 LED_R_Allg_Elektr_Def_5 2000;
BA_REL_ "GenSigTimeoutTime" BU_SG_REL_ AFS SG_ 1341 LED_R_Allg_Elektr_Def_6 2000;
BA_REL_ "GenSigTimeoutTime" BU_SG_REL_ BCM1 SG_ 1341 LED_R_Allg_Elektr_Def_6 2000;
BA_REL_ "GenSigTimeoutTime" BU_SG_REL_ FCM SG_ 1341 LED_R_Allg_Elektr_Def_6 2000;
BA_REL_ "GenSigTimeoutTime" BU_SG_REL_ MXB SG_ 1341 LED_R_Allg_Elektr_Def_6 2000;
BA_REL_ "GenSigTimeoutTime" BU_SG_REL_ AFS SG_ 1341 LED_R_Allg_Elektr_Def_7 2000;
BA_REL_ "GenSigTimeoutTime" BU_SG_REL_ BCM1 SG_ 1341 LED_R_Allg_Elektr_Def_7 2000;
BA_REL_ "GenSigTimeoutTime" BU_SG_REL_ FCM SG_ 1341 LED_R_Allg_Elektr_Def_7 2000;
BA_REL_ "GenSigTimeoutTime" BU_SG_REL_ MXB SG_ 1341 LED_R_Allg_Elektr_Def_7 2000;
BA_REL_ "GenSigTimeoutTime" BU_SG_REL_ AFS SG_ 1341 LED_R_Allg_Elektr_Def_8 2000;
BA_REL_ "GenSigTimeoutTime" BU_SG_REL_ BCM1 SG_ 1341 LED_R_Allg_Elektr_Def_8 2000;
BA_REL_ "GenSigTimeoutTime" BU_SG_REL_ FCM SG_ 1341 LED_R_Allg_Elektr_Def_8 2000;
BA_REL_ "GenSigTimeoutTime" BU_SG_REL_ MXB SG_ 1341 LED_R_Allg_Elektr_Def_8 2000;
BA_REL_ "GenSigTimeoutTime" BU_SG_REL_ AFS SG_ 1341 LED_R_Allg_Elektr_Def_Err_Gultig 2000;
BA_REL_ "GenSigTimeoutTime" BU_SG_REL_ BCM1 SG_ 1341 LED_R_Allg_Elektr_Def_Err_Gultig 2000;
BA_REL_ "GenSigTimeoutTime" BU_SG_REL_ FCM SG_ 1341 LED_R_Allg_Elektr_Def_Err_Gultig 2000;
BA_REL_ "GenSigTimeoutTime" BU_SG_REL_ MXB SG_ 1341 LED_R_Allg_Elektr_Def_Err_Gultig 2000;
BA_REL_ "GenSigTimeoutTime" BU_SG_REL_ AFS SG_ 1341 LED_R_Luefter_1_Def_1 2000;
BA_REL_ "GenSigTimeoutTime" BU_SG_REL_ BCM1 SG_ 1341 LED_R_Luefter_1_Def_1 2000;
BA_REL_ "GenSigTimeoutTime" BU_SG_REL_ FCM SG_ 1341 LED_R_Luefter_1_Def_1 2000;
BA_REL_ "GenSigTimeoutTime" BU_SG_REL_ MXB SG_ 1341 LED_R_Luefter_1_Def_1 2000;
BA_REL_ "GenSigTimeoutTime" BU_SG_REL_ AFS SG_ 1341 LED_R_Luefter_1_Def_2 2000;
BA_REL_ "GenSigTimeoutTime" BU_SG_REL_ BCM1 SG_ 1341 LED_R_Luefter_1_Def_2 2000;
BA_REL_ "GenSigTimeoutTime" BU_SG_REL_ FCM SG_ 1341 LED_R_Luefter_1_Def_2 2000;
BA_REL_ "GenSigTimeoutTime" BU_SG_REL_ MXB SG_ 1341 LED_R_Luefter_1_Def_2 2000;
BA_REL_ "GenSigTimeoutTime" BU_SG_REL_ AFS SG_ 1341 LED_R_Luefter_1_Def_3 2000;
BA_REL_ "GenSigTimeoutTime" BU_SG_REL_ BCM1 SG_ 1341 LED_R_Luefter_1_Def_3 2000;
BA_REL_ "GenSigTimeoutTime" BU_SG_REL_ FCM SG_ 1341 LED_R_Luefter_1_Def_3 2000;
BA_REL_ "GenSigTimeoutTime" BU_SG_REL_ MXB SG_ 1341 LED_R_Luefter_1_Def_3 2000;
BA_REL_ "GenSigTimeoutTime" BU_SG_REL_ AFS SG_ 1341 LED_R_Luefter_1_Def_4 2000;
BA_REL_ "GenSigTimeoutTime" BU_SG_REL_ BCM1 SG_ 1341 LED_R_Luefter_1_Def_4 2000;
BA_REL_ "GenSigTimeoutTime" BU_SG_REL_ FCM SG_ 1341 LED_R_Luefter_1_Def_4 2000;
BA_REL_ "GenSigTimeoutTime" BU_SG_REL_ MXB SG_ 1341 LED_R_Luefter_1_Def_4 2000;
BA_REL_ "GenSigTimeoutTime" BU_SG_REL_ AFS SG_ 1341 LED_R_Luefter_2_Def_1 2000;
BA_REL_ "GenSigTimeoutTime" BU_SG_REL_ BCM1 SG_ 1341 LED_R_Luefter_2_Def_1 2000;
BA_REL_ "GenSigTimeoutTime" BU_SG_REL_ FCM SG_ 1341 LED_R_Luefter_2_Def_1 2000;
BA_REL_ "GenSigTimeoutTime" BU_SG_REL_ MXB SG_ 1341 LED_R_Luefter_2_Def_1 2000;
BA_REL_ "GenSigTimeoutTime" BU_SG_REL_ AFS SG_ 1341 LED_R_Luefter_2_Def_2 2000;
BA_REL_ "GenSigTimeoutTime" BU_SG_REL_ BCM1 SG_ 1341 LED_R_Luefter_2_Def_2 2000;
BA_REL_ "GenSigTimeoutTime" BU_SG_REL_ FCM SG_ 1341 LED_R_Luefter_2_Def_2 2000;
BA_REL_ "GenSigTimeoutTime" BU_SG_REL_ MXB SG_ 1341 LED_R_Luefter_2_Def_2 2000;
BA_REL_ "GenSigTimeoutTime" BU_SG_REL_ AFS SG_ 1341 LED_R_Luefter_2_Def_3 2000;
BA_REL_ "GenSigTimeoutTime" BU_SG_REL_ BCM1 SG_ 1341 LED_R_Luefter_2_Def_3 2000;
BA_REL_ "GenSigTimeoutTime" BU_SG_REL_ FCM SG_ 1341 LED_R_Luefter_2_Def_3 2000;
BA_REL_ "GenSigTimeoutTime" BU_SG_REL_ MXB SG_ 1341 LED_R_Luefter_2_Def_3 2000;
BA_REL_ "GenSigTimeoutTime" BU_SG_REL_ AFS SG_ 1341 LED_R_Luefter_2_Def_4 2000;
BA_REL_ "GenSigTimeoutTime" BU_SG_REL_ BCM1 SG_ 1341 LED_R_Luefter_2_Def_4 2000;
BA_REL_ "GenSigTimeoutTime" BU_SG_REL_ FCM SG_ 1341 LED_R_Luefter_2_Def_4 2000;
BA_REL_ "GenSigTimeoutTime" BU_SG_REL_ MXB SG_ 1341 LED_R_Luefter_2_Def_4 2000;
BA_REL_ "GenSigTimeoutTime" BU_SG_REL_ AFS SG_ 1341 LED_R_Luefter_1_Def_Err_Gultig 2000;
BA_REL_ "GenSigTimeoutTime" BU_SG_REL_ BCM1 SG_ 1341 LED_R_Luefter_1_Def_Err_Gultig 2000;
BA_REL_ "GenSigTimeoutTime" BU_SG_REL_ FCM SG_ 1341 LED_R_Luefter_1_Def_Err_Gultig 2000;
BA_REL_ "GenSigTimeoutTime" BU_SG_REL_ MXB SG_ 1341 LED_R_Luefter_1_Def_Err_Gultig 2000;
BA_REL_ "GenSigTimeoutTime" BU_SG_REL_ AFS SG_ 1341 LED_R_Luefter_2_Def_Err_Gultig 2000;
BA_REL_ "GenSigTimeoutTime" BU_SG_REL_ BCM1 SG_ 1341 LED_R_Luefter_2_Def_Err_Gultig 2000;
BA_REL_ "GenSigTimeoutTime" BU_SG_REL_ FCM SG_ 1341 LED_R_Luefter_2_Def_Err_Gultig 2000;
BA_REL_ "GenSigTimeoutTime" BU_SG_REL_ MXB SG_ 1341 LED_R_Luefter_2_Def_Err_Gultig 2000;
BA_REL_ "GenSigTimeoutTime" BU_SG_REL_ AFS SG_ 1341 LED_R_ECE_SAE_Umschaltung_Def 2000;
BA_REL_ "GenSigTimeoutTime" BU_SG_REL_ BCM1 SG_ 1341 LED_R_ECE_SAE_Umschaltung_Def 2000;
BA_REL_ "GenSigTimeoutTime" BU_SG_REL_ FCM SG_ 1341 LED_R_ECE_SAE_Umschaltung_Def 2000;
BA_REL_ "GenSigTimeoutTime" BU_SG_REL_ MXB SG_ 1341 LED_R_ECE_SAE_Umschaltung_Def 2000;
BA_REL_ "GenSigTimeoutTime" BU_SG_REL_ AFS SG_ 2527679495 LED_R_Nebel_All_Def_1 2000;
BA_REL_ "GenSigTimeoutTime" BU_SG_REL_ BCM1 SG_ 2527679495 LED_R_Nebel_All_Def_1 2000;
BA_REL_ "GenSigTimeoutTime" BU_SG_REL_ FCM SG_ 2527679495 LED_R_Nebel_All_Def_1 2000;
BA_REL_ "GenSigTimeoutTime" BU_SG_REL_ MXB SG_ 2527679495 LED_R_Nebel_All_Def_1 2000;
BA_REL_ "GenSigTimeoutTime" BU_SG_REL_ AFS SG_ 2527679495 LED_R_Nebel_All_Def_2 2000;
BA_REL_ "GenSigTimeoutTime" BU_SG_REL_ BCM1 SG_ 2527679495 LED_R_Nebel_All_Def_2 2000;
BA_REL_ "GenSigTimeoutTime" BU_SG_REL_ FCM SG_ 2527679495 LED_R_Nebel_All_Def_2 2000;
BA_REL_ "GenSigTimeoutTime" BU_SG_REL_ MXB SG_ 2527679495 LED_R_Nebel_All_Def_2 2000;
BA_REL_ "GenSigTimeoutTime" BU_SG_REL_ AFS SG_ 2527679495 LED_R_Nebel_All_Def_3 2000;
BA_REL_ "GenSigTimeoutTime" BU_SG_REL_ BCM1 SG_ 2527679495 LED_R_Nebel_All_Def_3 2000;
BA_REL_ "GenSigTimeoutTime" BU_SG_REL_ FCM SG_ 2527679495 LED_R_Nebel_All_Def_3 2000;
BA_REL_ "GenSigTimeoutTime" BU_SG_REL_ MXB SG_ 2527679495 LED_R_Nebel_All_Def_3 2000;
BA_REL_ "GenSigTimeoutTime" BU_SG_REL_ AFS SG_ 2527679495 LED_R_Nebel_All_Def_4 2000;
BA_REL_ "GenSigTimeoutTime" BU_SG_REL_ BCM1 SG_ 2527679495 LED_R_Nebel_All_Def_4 2000;
BA_REL_ "GenSigTimeoutTime" BU_SG_REL_ FCM SG_ 2527679495 LED_R_Nebel_All_Def_4 2000;
BA_REL_ "GenSigTimeoutTime" BU_SG_REL_ MXB SG_ 2527679495 LED_R_Nebel_All_Def_4 2000;
BA_REL_ "GenSigTimeoutTime" BU_SG_REL_ AFS SG_ 2527679495 LED_R_Nebel_All_Def_5 2000;
BA_REL_ "GenSigTimeoutTime" BU_SG_REL_ BCM1 SG_ 2527679495 LED_R_Nebel_All_Def_5 2000;
BA_REL_ "GenSigTimeoutTime" BU_SG_REL_ FCM SG_ 2527679495 LED_R_Nebel_All_Def_5 2000;
BA_REL_ "GenSigTimeoutTime" BU_SG_REL_ MXB SG_ 2527679495 LED_R_Nebel_All_Def_5 2000;
BA_REL_ "GenSigTimeoutTime" BU_SG_REL_ AFS SG_ 2527679495 LED_R_Nebel_All_Def_6 2000;
BA_REL_ "GenSigTimeoutTime" BU_SG_REL_ BCM1 SG_ 2527679495 LED_R_Nebel_All_Def_6 2000;
BA_REL_ "GenSigTimeoutTime" BU_SG_REL_ FCM SG_ 2527679495 LED_R_Nebel_All_Def_6 2000;
BA_REL_ "GenSigTimeoutTime" BU_SG_REL_ MXB SG_ 2527679495 LED_R_Nebel_All_Def_6 2000;
BA_REL_ "GenSigTimeoutTime" BU_SG_REL_ AFS SG_ 2527679495 LED_R_Nebel_All_Def_7 2000;
BA_REL_ "GenSigTimeoutTime" BU_SG_REL_ BCM1 SG_ 2527679495 LED_R_Nebel_All_Def_7 2000;
BA_REL_ "GenSigTimeoutTime" BU_SG_REL_ FCM SG_ 2527679495 LED_R_Nebel_All_Def_7 2000;
BA_REL_ "GenSigTimeoutTime" BU_SG_REL_ MXB SG_ 2527679495 LED_R_Nebel_All_Def_7 2000;
BA_REL_ "GenSigTimeoutTime" BU_SG_REL_ AFS SG_ 2527679495 LED_R_Nebel_All_Def_Err_Gultig 2000;
BA_REL_ "GenSigTimeoutTime" BU_SG_REL_ BCM1 SG_ 2527679495 LED_R_Nebel_All_Def_Err_Gultig 2000;
BA_REL_ "GenSigTimeoutTime" BU_SG_REL_ FCM SG_ 2527679495 LED_R_Nebel_All_Def_Err_Gultig 2000;
BA_REL_ "GenSigTimeoutTime" BU_SG_REL_ MXB SG_ 2527679495 LED_R_Nebel_All_Def_Err_Gultig 2000;
BA_REL_ "GenSigTimeoutTime" BU_SG_REL_ AFS SG_ 2527679495 LED_R_Touristenl_Def_1 2000;
BA_REL_ "GenSigTimeoutTime" BU_SG_REL_ BCM1 SG_ 2527679495 LED_R_Touristenl_Def_1 2000;
BA_REL_ "GenSigTimeoutTime" BU_SG_REL_ FCM SG_ 2527679495 LED_R_Touristenl_Def_1 2000;
BA_REL_ "GenSigTimeoutTime" BU_SG_REL_ MXB SG_ 2527679495 LED_R_Touristenl_Def_1 2000;
BA_REL_ "GenSigTimeoutTime" BU_SG_REL_ AFS SG_ 2527679495 LED_R_Touristenl_Def_2 2000;
BA_REL_ "GenSigTimeoutTime" BU_SG_REL_ BCM1 SG_ 2527679495 LED_R_Touristenl_Def_2 2000;
BA_REL_ "GenSigTimeoutTime" BU_SG_REL_ FCM SG_ 2527679495 LED_R_Touristenl_Def_2 2000;
BA_REL_ "GenSigTimeoutTime" BU_SG_REL_ MXB SG_ 2527679495 LED_R_Touristenl_Def_2 2000;
BA_REL_ "GenSigTimeoutTime" BU_SG_REL_ AFS SG_ 2527679495 LED_R_Touristenl_Def_3 2000;
BA_REL_ "GenSigTimeoutTime" BU_SG_REL_ BCM1 SG_ 2527679495 LED_R_Touristenl_Def_3 2000;
BA_REL_ "GenSigTimeoutTime" BU_SG_REL_ FCM SG_ 2527679495 LED_R_Touristenl_Def_3 2000;
BA_REL_ "GenSigTimeoutTime" BU_SG_REL_ MXB SG_ 2527679495 LED_R_Touristenl_Def_3 2000;
BA_REL_ "GenSigTimeoutTime" BU_SG_REL_ AFS SG_ 2527679495 LED_R_Touristenl_Def_4 2000;
BA_REL_ "GenSigTimeoutTime" BU_SG_REL_ BCM1 SG_ 2527679495 LED_R_Touristenl_Def_4 2000;
BA_REL_ "GenSigTimeoutTime" BU_SG_REL_ FCM SG_ 2527679495 LED_R_Touristenl_Def_4 2000;
BA_REL_ "GenSigTimeoutTime" BU_SG_REL_ MXB SG_ 2527679495 LED_R_Touristenl_Def_4 2000;
BA_REL_ "GenSigTimeoutTime" BU_SG_REL_ AFS SG_ 2527679495 LED_R_Touristenl_Def_5 2000;
BA_REL_ "GenSigTimeoutTime" BU_SG_REL_ BCM1 SG_ 2527679495 LED_R_Touristenl_Def_5 2000;
BA_REL_ "GenSigTimeoutTime" BU_SG_REL_ FCM SG_ 2527679495 LED_R_Touristenl_Def_5 2000;
BA_REL_ "GenSigTimeoutTime" BU_SG_REL_ MXB SG_ 2527679495 LED_R_Touristenl_Def_5 2000;
BA_REL_ "GenSigTimeoutTime" BU_SG_REL_ AFS SG_ 2527679495 LED_R_Touristenl_Def_6 2000;
BA_REL_ "GenSigTimeoutTime" BU_SG_REL_ BCM1 SG_ 2527679495 LED_R_Touristenl_Def_6 2000;
BA_REL_ "GenSigTimeoutTime" BU_SG_REL_ FCM SG_ 2527679495 LED_R_Touristenl_Def_6 2000;
BA_REL_ "GenSigTimeoutTime" BU_SG_REL_ MXB SG_ 2527679495 LED_R_Touristenl_Def_6 2000;
BA_REL_ "GenSigTimeoutTime" BU_SG_REL_ AFS SG_ 2527679495 LED_R_Touristenl_Def_7 2000;
BA_REL_ "GenSigTimeoutTime" BU_SG_REL_ BCM1 SG_ 2527679495 LED_R_Touristenl_Def_7 2000;
BA_REL_ "GenSigTimeoutTime" BU_SG_REL_ FCM SG_ 2527679495 LED_R_Touristenl_Def_7 2000;
BA_REL_ "GenSigTimeoutTime" BU_SG_REL_ MXB SG_ 2527679495 LED_R_Touristenl_Def_7 2000;
BA_REL_ "GenSigTimeoutTime" BU_SG_REL_ AFS SG_ 2527679495 LED_R_Touristenl_Def_Err_Gultig 2000;
BA_REL_ "GenSigTimeoutTime" BU_SG_REL_ BCM1 SG_ 2527679495 LED_R_Touristenl_Def_Err_Gultig 2000;
BA_REL_ "GenSigTimeoutTime" BU_SG_REL_ FCM SG_ 2527679495 LED_R_Touristenl_Def_Err_Gultig 2000;
BA_REL_ "GenSigTimeoutTime" BU_SG_REL_ MXB SG_ 2527679495 LED_R_Touristenl_Def_Err_Gultig 2000;
BA_REL_ "GenSigTimeoutTime" BU_SG_REL_ AFS SG_ 2527679495 LED_R_Autobahnl_Def_1 2000;
BA_REL_ "GenSigTimeoutTime" BU_SG_REL_ BCM1 SG_ 2527679495 LED_R_Autobahnl_Def_1 2000;
BA_REL_ "GenSigTimeoutTime" BU_SG_REL_ FCM SG_ 2527679495 LED_R_Autobahnl_Def_1 2000;
BA_REL_ "GenSigTimeoutTime" BU_SG_REL_ MXB SG_ 2527679495 LED_R_Autobahnl_Def_1 2000;
BA_REL_ "GenSigTimeoutTime" BU_SG_REL_ AFS SG_ 2527679495 LED_R_Autobahnl_Def_2 2000;
BA_REL_ "GenSigTimeoutTime" BU_SG_REL_ BCM1 SG_ 2527679495 LED_R_Autobahnl_Def_2 2000;
BA_REL_ "GenSigTimeoutTime" BU_SG_REL_ FCM SG_ 2527679495 LED_R_Autobahnl_Def_2 2000;
BA_REL_ "GenSigTimeoutTime" BU_SG_REL_ MXB SG_ 2527679495 LED_R_Autobahnl_Def_2 2000;
BA_REL_ "GenSigTimeoutTime" BU_SG_REL_ AFS SG_ 2527679495 LED_R_Autobahnl_Def_3 2000;
BA_REL_ "GenSigTimeoutTime" BU_SG_REL_ BCM1 SG_ 2527679495 LED_R_Autobahnl_Def_3 2000;
BA_REL_ "GenSigTimeoutTime" BU_SG_REL_ FCM SG_ 2527679495 LED_R_Autobahnl_Def_3 2000;
BA_REL_ "GenSigTimeoutTime" BU_SG_REL_ MXB SG_ 2527679495 LED_R_Autobahnl_Def_3 2000;
BA_REL_ "GenSigTimeoutTime" BU_SG_REL_ AFS SG_ 2527679495 LED_R_Autobahnl_Def_4 2000;
BA_REL_ "GenSigTimeoutTime" BU_SG_REL_ BCM1 SG_ 2527679495 LED_R_Autobahnl_Def_4 2000;
BA_REL_ "GenSigTimeoutTime" BU_SG_REL_ FCM SG_ 2527679495 LED_R_Autobahnl_Def_4 2000;
BA_REL_ "GenSigTimeoutTime" BU_SG_REL_ MXB SG_ 2527679495 LED_R_Autobahnl_Def_4 2000;
BA_REL_ "GenSigTimeoutTime" BU_SG_REL_ AFS SG_ 2527679495 LED_R_Autobahnl_Def_5 2000;
BA_REL_ "GenSigTimeoutTime" BU_SG_REL_ BCM1 SG_ 2527679495 LED_R_Autobahnl_Def_5 2000;
BA_REL_ "GenSigTimeoutTime" BU_SG_REL_ FCM SG_ 2527679495 LED_R_Autobahnl_Def_5 2000;
BA_REL_ "GenSigTimeoutTime" BU_SG_REL_ MXB SG_ 2527679495 LED_R_Autobahnl_Def_5 2000;
BA_REL_ "GenSigTimeoutTime" BU_SG_REL_ AFS SG_ 2527679495 LED_R_Autobahnl_Def_6 2000;
BA_REL_ "GenSigTimeoutTime" BU_SG_REL_ BCM1 SG_ 2527679495 LED_R_Autobahnl_Def_6 2000;
BA_REL_ "GenSigTimeoutTime" BU_SG_REL_ FCM SG_ 2527679495 LED_R_Autobahnl_Def_6 2000;
BA_REL_ "GenSigTimeoutTime" BU_SG_REL_ MXB SG_ 2527679495 LED_R_Autobahnl_Def_6 2000;
BA_REL_ "GenSigTimeoutTime" BU_SG_REL_ AFS SG_ 2527679495 LED_R_Autobahnl_Def_7 2000;
BA_REL_ "GenSigTimeoutTime" BU_SG_REL_ BCM1 SG_ 2527679495 LED_R_Autobahnl_Def_7 2000;
BA_REL_ "GenSigTimeoutTime" BU_SG_REL_ FCM SG_ 2527679495 LED_R_Autobahnl_Def_7 2000;
BA_REL_ "GenSigTimeoutTime" BU_SG_REL_ MXB SG_ 2527679495 LED_R_Autobahnl_Def_7 2000;
BA_REL_ "GenSigTimeoutTime" BU_SG_REL_ AFS SG_ 2527679495 LED_R_Autobahnl_Def_Err_Gultig 2000;
BA_REL_ "GenSigTimeoutTime" BU_SG_REL_ BCM1 SG_ 2527679495 LED_R_Autobahnl_Def_Err_Gultig 2000;
BA_REL_ "GenSigTimeoutTime" BU_SG_REL_ FCM SG_ 2527679495 LED_R_Autobahnl_Def_Err_Gultig 2000;
BA_REL_ "GenSigTimeoutTime" BU_SG_REL_ MXB SG_ 2527679495 LED_R_Autobahnl_Def_Err_Gultig 2000;
BA_REL_ "GenSigTimeoutTime" BU_SG_REL_ AFS SG_ 2527679495 LED_R_Rennl_Def_1 2000;
BA_REL_ "GenSigTimeoutTime" BU_SG_REL_ BCM1 SG_ 2527679495 LED_R_Rennl_Def_1 2000;
BA_REL_ "GenSigTimeoutTime" BU_SG_REL_ FCM SG_ 2527679495 LED_R_Rennl_Def_1 2000;
BA_REL_ "GenSigTimeoutTime" BU_SG_REL_ MXB SG_ 2527679495 LED_R_Rennl_Def_1 2000;
BA_REL_ "GenSigTimeoutTime" BU_SG_REL_ AFS SG_ 2527679495 LED_R_Rennl_Def_2 2000;
BA_REL_ "GenSigTimeoutTime" BU_SG_REL_ BCM1 SG_ 2527679495 LED_R_Rennl_Def_2 2000;
BA_REL_ "GenSigTimeoutTime" BU_SG_REL_ FCM SG_ 2527679495 LED_R_Rennl_Def_2 2000;
BA_REL_ "GenSigTimeoutTime" BU_SG_REL_ MXB SG_ 2527679495 LED_R_Rennl_Def_2 2000;
BA_REL_ "GenSigTimeoutTime" BU_SG_REL_ AFS SG_ 2527679495 LED_R_Rennl_Def_3 2000;
BA_REL_ "GenSigTimeoutTime" BU_SG_REL_ BCM1 SG_ 2527679495 LED_R_Rennl_Def_3 2000;
BA_REL_ "GenSigTimeoutTime" BU_SG_REL_ FCM SG_ 2527679495 LED_R_Rennl_Def_3 2000;
BA_REL_ "GenSigTimeoutTime" BU_SG_REL_ MXB SG_ 2527679495 LED_R_Rennl_Def_3 2000;
BA_REL_ "GenSigTimeoutTime" BU_SG_REL_ AFS SG_ 2527679495 LED_R_Rennl_Def_4 2000;
BA_REL_ "GenSigTimeoutTime" BU_SG_REL_ BCM1 SG_ 2527679495 LED_R_Rennl_Def_4 2000;
BA_REL_ "GenSigTimeoutTime" BU_SG_REL_ FCM SG_ 2527679495 LED_R_Rennl_Def_4 2000;
BA_REL_ "GenSigTimeoutTime" BU_SG_REL_ MXB SG_ 2527679495 LED_R_Rennl_Def_4 2000;
BA_REL_ "GenSigTimeoutTime" BU_SG_REL_ AFS SG_ 2527679495 LED_R_Rennl_Def_5 2000;
BA_REL_ "GenSigTimeoutTime" BU_SG_REL_ BCM1 SG_ 2527679495 LED_R_Rennl_Def_5 2000;
BA_REL_ "GenSigTimeoutTime" BU_SG_REL_ FCM SG_ 2527679495 LED_R_Rennl_Def_5 2000;
BA_REL_ "GenSigTimeoutTime" BU_SG_REL_ MXB SG_ 2527679495 LED_R_Rennl_Def_5 2000;
BA_REL_ "GenSigTimeoutTime" BU_SG_REL_ AFS SG_ 2527679495 LED_R_Rennl_Def_6 2000;
BA_REL_ "GenSigTimeoutTime" BU_SG_REL_ BCM1 SG_ 2527679495 LED_R_Rennl_Def_6 2000;
BA_REL_ "GenSigTimeoutTime" BU_SG_REL_ FCM SG_ 2527679495 LED_R_Rennl_Def_6 2000;
BA_REL_ "GenSigTimeoutTime" BU_SG_REL_ MXB SG_ 2527679495 LED_R_Rennl_Def_6 2000;
BA_REL_ "GenSigTimeoutTime" BU_SG_REL_ AFS SG_ 2527679495 LED_R_Rennl_Def_7 2000;
BA_REL_ "GenSigTimeoutTime" BU_SG_REL_ BCM1 SG_ 2527679495 LED_R_Rennl_Def_7 2000;
BA_REL_ "GenSigTimeoutTime" BU_SG_REL_ FCM SG_ 2527679495 LED_R_Rennl_Def_7 2000;
BA_REL_ "GenSigTimeoutTime" BU_SG_REL_ MXB SG_ 2527679495 LED_R_Rennl_Def_7 2000;
BA_REL_ "GenSigTimeoutTime" BU_SG_REL_ AFS SG_ 2527679495 LED_R_Rennl_Def_Err_Gultig 2000;
BA_REL_ "GenSigTimeoutTime" BU_SG_REL_ BCM1 SG_ 2527679495 LED_R_Rennl_Def_Err_Gultig 2000;
BA_REL_ "GenSigTimeoutTime" BU_SG_REL_ FCM SG_ 2527679495 LED_R_Rennl_Def_Err_Gultig 2000;
BA_REL_ "GenSigTimeoutTime" BU_SG_REL_ MXB SG_ 2527679495 LED_R_Rennl_Def_Err_Gultig 2000;
BA_REL_ "GenSigTimeoutTime" BU_SG_REL_ AFS SG_ 2527679495 LED_R_Stadtl_Def_1 2000;
BA_REL_ "GenSigTimeoutTime" BU_SG_REL_ BCM1 SG_ 2527679495 LED_R_Stadtl_Def_1 2000;
BA_REL_ "GenSigTimeoutTime" BU_SG_REL_ FCM SG_ 2527679495 LED_R_Stadtl_Def_1 2000;
BA_REL_ "GenSigTimeoutTime" BU_SG_REL_ MXB SG_ 2527679495 LED_R_Stadtl_Def_1 2000;
BA_REL_ "GenSigTimeoutTime" BU_SG_REL_ AFS SG_ 2527679495 LED_R_Stadtl_Def_2 2000;
BA_REL_ "GenSigTimeoutTime" BU_SG_REL_ BCM1 SG_ 2527679495 LED_R_Stadtl_Def_2 2000;
BA_REL_ "GenSigTimeoutTime" BU_SG_REL_ FCM SG_ 2527679495 LED_R_Stadtl_Def_2 2000;
BA_REL_ "GenSigTimeoutTime" BU_SG_REL_ MXB SG_ 2527679495 LED_R_Stadtl_Def_2 2000;
BA_REL_ "GenSigTimeoutTime" BU_SG_REL_ AFS SG_ 2527679495 LED_R_Stadtl_Def_3 2000;
BA_REL_ "GenSigTimeoutTime" BU_SG_REL_ BCM1 SG_ 2527679495 LED_R_Stadtl_Def_3 2000;
BA_REL_ "GenSigTimeoutTime" BU_SG_REL_ FCM SG_ 2527679495 LED_R_Stadtl_Def_3 2000;
BA_REL_ "GenSigTimeoutTime" BU_SG_REL_ MXB SG_ 2527679495 LED_R_Stadtl_Def_3 2000;
BA_REL_ "GenSigTimeoutTime" BU_SG_REL_ AFS SG_ 2527679495 LED_R_Stadtl_Def_4 2000;
BA_REL_ "GenSigTimeoutTime" BU_SG_REL_ BCM1 SG_ 2527679495 LED_R_Stadtl_Def_4 2000;
BA_REL_ "GenSigTimeoutTime" BU_SG_REL_ FCM SG_ 2527679495 LED_R_Stadtl_Def_4 2000;
BA_REL_ "GenSigTimeoutTime" BU_SG_REL_ MXB SG_ 2527679495 LED_R_Stadtl_Def_4 2000;
BA_REL_ "GenSigTimeoutTime" BU_SG_REL_ AFS SG_ 2527679495 LED_R_Stadtl_Def_5 2000;
BA_REL_ "GenSigTimeoutTime" BU_SG_REL_ BCM1 SG_ 2527679495 LED_R_Stadtl_Def_5 2000;
BA_REL_ "GenSigTimeoutTime" BU_SG_REL_ FCM SG_ 2527679495 LED_R_Stadtl_Def_5 2000;
BA_REL_ "GenSigTimeoutTime" BU_SG_REL_ MXB SG_ 2527679495 LED_R_Stadtl_Def_5 2000;
BA_REL_ "GenSigTimeoutTime" BU_SG_REL_ AFS SG_ 2527679495 LED_R_Stadtl_Def_6 2000;
BA_REL_ "GenSigTimeoutTime" BU_SG_REL_ BCM1 SG_ 2527679495 LED_R_Stadtl_Def_6 2000;
BA_REL_ "GenSigTimeoutTime" BU_SG_REL_ FCM SG_ 2527679495 LED_R_Stadtl_Def_6 2000;
BA_REL_ "GenSigTimeoutTime" BU_SG_REL_ MXB SG_ 2527679495 LED_R_Stadtl_Def_6 2000;
BA_REL_ "GenSigTimeoutTime" BU_SG_REL_ AFS SG_ 2527679495 LED_R_Stadtl_Def_7 2000;
BA_REL_ "GenSigTimeoutTime" BU_SG_REL_ BCM1 SG_ 2527679495 LED_R_Stadtl_Def_7 2000;
BA_REL_ "GenSigTimeoutTime" BU_SG_REL_ FCM SG_ 2527679495 LED_R_Stadtl_Def_7 2000;
BA_REL_ "GenSigTimeoutTime" BU_SG_REL_ MXB SG_ 2527679495 LED_R_Stadtl_Def_7 2000;
BA_REL_ "GenSigTimeoutTime" BU_SG_REL_ AFS SG_ 2527679495 LED_R_Stadtl_Def_Err_Gultig 2000;
BA_REL_ "GenSigTimeoutTime" BU_SG_REL_ BCM1 SG_ 2527679495 LED_R_Stadtl_Def_Err_Gultig 2000;
BA_REL_ "GenSigTimeoutTime" BU_SG_REL_ FCM SG_ 2527679495 LED_R_Stadtl_Def_Err_Gultig 2000;
BA_REL_ "GenSigTimeoutTime" BU_SG_REL_ MXB SG_ 2527679495 LED_R_Stadtl_Def_Err_Gultig 2000;
BA_REL_ "GenSigTimeoutTime" BU_SG_REL_ AFS SG_ 2527679511 LED_R_Abbiegel_Def 2000;
BA_REL_ "GenSigTimeoutTime" BU_SG_REL_ BCM1 SG_ 2527679511 LED_R_Abbiegel_Def 2000;
BA_REL_ "GenSigTimeoutTime" BU_SG_REL_ FCM SG_ 2527679511 LED_R_Abbiegel_Def 2000;
BA_REL_ "GenSigTimeoutTime" BU_SG_REL_ MXB SG_ 2527679511 LED_R_Abbiegel_Def 2000;
BA_REL_ "GenSigTimeoutTime" BU_SG_REL_ AFS SG_ 2527679511 LED_R_Abblendl_Def 2000;
BA_REL_ "GenSigTimeoutTime" BU_SG_REL_ BCM1 SG_ 2527679511 LED_R_Abblendl_Def 2000;
BA_REL_ "GenSigTimeoutTime" BU_SG_REL_ FCM SG_ 2527679511 LED_R_Abblendl_Def 2000;
BA_REL_ "GenSigTimeoutTime" BU_SG_REL_ LCM_R SG_ 2527679511 LED_R_Abblendl_Def 2000;
BA_REL_ "GenSigTimeoutTime" BU_SG_REL_ MXB SG_ 2527679511 LED_R_Abblendl_Def 2000;
BA_REL_ "GenSigTimeoutTime" BU_SG_REL_ AFS SG_ 2527679511 LED_R_Allg_Elektr_Def 2000;
BA_REL_ "GenSigTimeoutTime" BU_SG_REL_ BCM1 SG_ 2527679511 LED_R_Allg_Elektr_Def 2000;
BA_REL_ "GenSigTimeoutTime" BU_SG_REL_ FCM SG_ 2527679511 LED_R_Allg_Elektr_Def 2000;
BA_REL_ "GenSigTimeoutTime" BU_SG_REL_ MXB SG_ 2527679511 LED_R_Allg_Elektr_Def 2000;
BA_REL_ "GenSigTimeoutTime" BU_SG_REL_ AFS SG_ 2527679511 LED_R_Fernl_Def 2000;
BA_REL_ "GenSigTimeoutTime" BU_SG_REL_ BCM1 SG_ 2527679511 LED_R_Fernl_Def 2000;
BA_REL_ "GenSigTimeoutTime" BU_SG_REL_ FCM SG_ 2527679511 LED_R_Fernl_Def 2000;
BA_REL_ "GenSigTimeoutTime" BU_SG_REL_ MXB SG_ 2527679511 LED_R_Fernl_Def 2000;
BA_REL_ "GenSigTimeoutTime" BU_SG_REL_ AFS SG_ 2527679511 LED_R_falsch_codiert 2000;
BA_REL_ "GenSigTimeoutTime" BU_SG_REL_ BCM1 SG_ 2527679511 LED_R_falsch_codiert 2000;
BA_REL_ "GenSigTimeoutTime" BU_SG_REL_ FCM SG_ 2527679511 LED_R_falsch_codiert 2000;
BA_REL_ "GenSigTimeoutTime" BU_SG_REL_ MXB SG_ 2527679511 LED_R_falsch_codiert 2000;
BA_REL_ "GenSigTimeoutTime" BU_SG_REL_ AFS SG_ 2527679511 LED_R_Zus_Fernl_LH_Def 2000;
BA_REL_ "GenSigTimeoutTime" BU_SG_REL_ BCM1 SG_ 2527679511 LED_R_Zus_Fernl_LH_Def 2000;
BA_REL_ "GenSigTimeoutTime" BU_SG_REL_ FCM SG_ 2527679511 LED_R_Zus_Fernl_LH_Def 2000;
BA_REL_ "GenSigTimeoutTime" BU_SG_REL_ AFS SG_ 2527679511 LED_R_Laser_Def 2000;
BA_REL_ "GenSigTimeoutTime" BU_SG_REL_ BCM1 SG_ 2527679511 LED_R_Laser_Def 2000;
BA_REL_ "GenSigTimeoutTime" BU_SG_REL_ FCM SG_ 2527679511 LED_R_Laser_Def 2000;
BA_REL_ "GenSigTimeoutTime" BU_SG_REL_ AFS SG_ 1422 LED_L_Mux 1000;
BA_REL_ "GenSigTimeoutTime" BU_SG_REL_ BCM1 SG_ 1422 LED_L_Mux 1000;
BA_REL_ "GenSigTimeoutTime" BU_SG_REL_ FCM SG_ 1422 LED_L_Mux 1000;
BA_REL_ "GenSigTimeoutTime" BU_SG_REL_ MXB SG_ 1422 LED_L_Mux 1000;
BA_REL_ "GenSigTimeoutTime" BU_SG_REL_ AFS SG_ 1422 LED_L_SW_Idt_Z01 1000;
BA_REL_ "GenSigTimeoutTime" BU_SG_REL_ BCM1 SG_ 1422 LED_L_SW_Idt_Z01 1000;
BA_REL_ "GenSigTimeoutTime" BU_SG_REL_ FCM SG_ 1422 LED_L_SW_Idt_Z01 1000;
BA_REL_ "GenSigTimeoutTime" BU_SG_REL_ MXB SG_ 1422 LED_L_SW_Idt_Z01 1000;
BA_REL_ "GenSigTimeoutTime" BU_SG_REL_ AFS SG_ 1422 LED_L_SW_Idt_Z08 1000;
BA_REL_ "GenSigTimeoutTime" BU_SG_REL_ BCM1 SG_ 1422 LED_L_SW_Idt_Z08 1000;
BA_REL_ "GenSigTimeoutTime" BU_SG_REL_ FCM SG_ 1422 LED_L_SW_Idt_Z08 1000;
BA_REL_ "GenSigTimeoutTime" BU_SG_REL_ MXB SG_ 1422 LED_L_SW_Idt_Z08 1000;
BA_REL_ "GenSigTimeoutTime" BU_SG_REL_ AFS SG_ 1422 LED_L_SW_Idx_Z04 1000;
BA_REL_ "GenSigTimeoutTime" BU_SG_REL_ BCM1 SG_ 1422 LED_L_SW_Idx_Z04 1000;
BA_REL_ "GenSigTimeoutTime" BU_SG_REL_ FCM SG_ 1422 LED_L_SW_Idx_Z04 1000;
BA_REL_ "GenSigTimeoutTime" BU_SG_REL_ MXB SG_ 1422 LED_L_SW_Idx_Z04 1000;
BA_REL_ "GenSigTimeoutTime" BU_SG_REL_ AFS SG_ 1422 LED_L_HW_Idt_Z07 1000;
BA_REL_ "GenSigTimeoutTime" BU_SG_REL_ BCM1 SG_ 1422 LED_L_HW_Idt_Z07 1000;
BA_REL_ "GenSigTimeoutTime" BU_SG_REL_ FCM SG_ 1422 LED_L_HW_Idt_Z07 1000;
BA_REL_ "GenSigTimeoutTime" BU_SG_REL_ MXB SG_ 1422 LED_L_HW_Idt_Z07 1000;
BA_REL_ "GenSigTimeoutTime" BU_SG_REL_ AFS SG_ 1422 LED_L_HW_Idx_Z03 1000;
BA_REL_ "GenSigTimeoutTime" BU_SG_REL_ BCM1 SG_ 1422 LED_L_HW_Idx_Z03 1000;
BA_REL_ "GenSigTimeoutTime" BU_SG_REL_ FCM SG_ 1422 LED_L_HW_Idx_Z03 1000;
BA_REL_ "GenSigTimeoutTime" BU_SG_REL_ MXB SG_ 1422 LED_L_HW_Idx_Z03 1000;
BA_REL_ "GenSigTimeoutTime" BU_SG_REL_ AFS SG_ 1422 LED_L_SW_Idt_Z02 1000;
BA_REL_ "GenSigTimeoutTime" BU_SG_REL_ BCM1 SG_ 1422 LED_L_SW_Idt_Z02 1000;
BA_REL_ "GenSigTimeoutTime" BU_SG_REL_ FCM SG_ 1422 LED_L_SW_Idt_Z02 1000;
BA_REL_ "GenSigTimeoutTime" BU_SG_REL_ MXB SG_ 1422 LED_L_SW_Idt_Z02 1000;
BA_REL_ "GenSigTimeoutTime" BU_SG_REL_ AFS SG_ 1422 LED_L_SW_Idt_Z09 1000;
BA_REL_ "GenSigTimeoutTime" BU_SG_REL_ BCM1 SG_ 1422 LED_L_SW_Idt_Z09 1000;
BA_REL_ "GenSigTimeoutTime" BU_SG_REL_ FCM SG_ 1422 LED_L_SW_Idt_Z09 1000;
BA_REL_ "GenSigTimeoutTime" BU_SG_REL_ MXB SG_ 1422 LED_L_SW_Idt_Z09 1000;
BA_REL_ "GenSigTimeoutTime" BU_SG_REL_ AFS SG_ 1422 LED_L_HW_Idt_Z01 1000;
BA_REL_ "GenSigTimeoutTime" BU_SG_REL_ BCM1 SG_ 1422 LED_L_HW_Idt_Z01 1000;
BA_REL_ "GenSigTimeoutTime" BU_SG_REL_ FCM SG_ 1422 LED_L_HW_Idt_Z01 1000;
BA_REL_ "GenSigTimeoutTime" BU_SG_REL_ MXB SG_ 1422 LED_L_HW_Idt_Z01 1000;
BA_REL_ "GenSigTimeoutTime" BU_SG_REL_ AFS SG_ 1422 LED_L_HW_Idt_Z08 1000;
BA_REL_ "GenSigTimeoutTime" BU_SG_REL_ BCM1 SG_ 1422 LED_L_HW_Idt_Z08 1000;
BA_REL_ "GenSigTimeoutTime" BU_SG_REL_ FCM SG_ 1422 LED_L_HW_Idt_Z08 1000;
BA_REL_ "GenSigTimeoutTime" BU_SG_REL_ MXB SG_ 1422 LED_L_HW_Idt_Z08 1000;
BA_REL_ "GenSigTimeoutTime" BU_SG_REL_ AFS SG_ 1422 LED_L_SW_Idt_Z03 1000;
BA_REL_ "GenSigTimeoutTime" BU_SG_REL_ BCM1 SG_ 1422 LED_L_SW_Idt_Z03 1000;
BA_REL_ "GenSigTimeoutTime" BU_SG_REL_ FCM SG_ 1422 LED_L_SW_Idt_Z03 1000;
BA_REL_ "GenSigTimeoutTime" BU_SG_REL_ MXB SG_ 1422 LED_L_SW_Idt_Z03 1000;
BA_REL_ "GenSigTimeoutTime" BU_SG_REL_ AFS SG_ 1422 LED_L_SW_Idt_Z10 1000;
BA_REL_ "GenSigTimeoutTime" BU_SG_REL_ BCM1 SG_ 1422 LED_L_SW_Idt_Z10 1000;
BA_REL_ "GenSigTimeoutTime" BU_SG_REL_ FCM SG_ 1422 LED_L_SW_Idt_Z10 1000;
BA_REL_ "GenSigTimeoutTime" BU_SG_REL_ MXB SG_ 1422 LED_L_SW_Idt_Z10 1000;
BA_REL_ "GenSigTimeoutTime" BU_SG_REL_ AFS SG_ 1422 LED_L_HW_Idt_Z02 1000;
BA_REL_ "GenSigTimeoutTime" BU_SG_REL_ BCM1 SG_ 1422 LED_L_HW_Idt_Z02 1000;
BA_REL_ "GenSigTimeoutTime" BU_SG_REL_ FCM SG_ 1422 LED_L_HW_Idt_Z02 1000;
BA_REL_ "GenSigTimeoutTime" BU_SG_REL_ MXB SG_ 1422 LED_L_HW_Idt_Z02 1000;
BA_REL_ "GenSigTimeoutTime" BU_SG_REL_ AFS SG_ 1422 LED_L_HW_Idt_Z09 1000;
BA_REL_ "GenSigTimeoutTime" BU_SG_REL_ BCM1 SG_ 1422 LED_L_HW_Idt_Z09 1000;
BA_REL_ "GenSigTimeoutTime" BU_SG_REL_ FCM SG_ 1422 LED_L_HW_Idt_Z09 1000;
BA_REL_ "GenSigTimeoutTime" BU_SG_REL_ MXB SG_ 1422 LED_L_HW_Idt_Z09 1000;
BA_REL_ "GenSigTimeoutTime" BU_SG_REL_ AFS SG_ 1422 LED_L_SW_Idt_Z04 1000;
BA_REL_ "GenSigTimeoutTime" BU_SG_REL_ BCM1 SG_ 1422 LED_L_SW_Idt_Z04 1000;
BA_REL_ "GenSigTimeoutTime" BU_SG_REL_ FCM SG_ 1422 LED_L_SW_Idt_Z04 1000;
BA_REL_ "GenSigTimeoutTime" BU_SG_REL_ MXB SG_ 1422 LED_L_SW_Idt_Z04 1000;
BA_REL_ "GenSigTimeoutTime" BU_SG_REL_ AFS SG_ 1422 LED_L_SW_Idt_Z11 1000;
BA_REL_ "GenSigTimeoutTime" BU_SG_REL_ BCM1 SG_ 1422 LED_L_SW_Idt_Z11 1000;
BA_REL_ "GenSigTimeoutTime" BU_SG_REL_ FCM SG_ 1422 LED_L_SW_Idt_Z11 1000;
BA_REL_ "GenSigTimeoutTime" BU_SG_REL_ MXB SG_ 1422 LED_L_SW_Idt_Z11 1000;
BA_REL_ "GenSigTimeoutTime" BU_SG_REL_ AFS SG_ 1422 LED_L_HW_Idt_Z03 1000;
BA_REL_ "GenSigTimeoutTime" BU_SG_REL_ BCM1 SG_ 1422 LED_L_HW_Idt_Z03 1000;
BA_REL_ "GenSigTimeoutTime" BU_SG_REL_ FCM SG_ 1422 LED_L_HW_Idt_Z03 1000;
BA_REL_ "GenSigTimeoutTime" BU_SG_REL_ MXB SG_ 1422 LED_L_HW_Idt_Z03 1000;
BA_REL_ "GenSigTimeoutTime" BU_SG_REL_ AFS SG_ 1422 LED_L_HW_Idt_Z10 1000;
BA_REL_ "GenSigTimeoutTime" BU_SG_REL_ BCM1 SG_ 1422 LED_L_HW_Idt_Z10 1000;
BA_REL_ "GenSigTimeoutTime" BU_SG_REL_ FCM SG_ 1422 LED_L_HW_Idt_Z10 1000;
BA_REL_ "GenSigTimeoutTime" BU_SG_REL_ MXB SG_ 1422 LED_L_HW_Idt_Z10 1000;
BA_REL_ "GenSigTimeoutTime" BU_SG_REL_ AFS SG_ 1422 LED_L_SW_Idt_Z05 1000;
BA_REL_ "GenSigTimeoutTime" BU_SG_REL_ BCM1 SG_ 1422 LED_L_SW_Idt_Z05 1000;
BA_REL_ "GenSigTimeoutTime" BU_SG_REL_ FCM SG_ 1422 LED_L_SW_Idt_Z05 1000;
BA_REL_ "GenSigTimeoutTime" BU_SG_REL_ MXB SG_ 1422 LED_L_SW_Idt_Z05 1000;
BA_REL_ "GenSigTimeoutTime" BU_SG_REL_ AFS SG_ 1422 LED_L_SW_Idx_Z01 1000;
BA_REL_ "GenSigTimeoutTime" BU_SG_REL_ BCM1 SG_ 1422 LED_L_SW_Idx_Z01 1000;
BA_REL_ "GenSigTimeoutTime" BU_SG_REL_ FCM SG_ 1422 LED_L_SW_Idx_Z01 1000;
BA_REL_ "GenSigTimeoutTime" BU_SG_REL_ MXB SG_ 1422 LED_L_SW_Idx_Z01 1000;
BA_REL_ "GenSigTimeoutTime" BU_SG_REL_ AFS SG_ 1422 LED_L_HW_Idt_Z04 1000;
BA_REL_ "GenSigTimeoutTime" BU_SG_REL_ BCM1 SG_ 1422 LED_L_HW_Idt_Z04 1000;
BA_REL_ "GenSigTimeoutTime" BU_SG_REL_ FCM SG_ 1422 LED_L_HW_Idt_Z04 1000;
BA_REL_ "GenSigTimeoutTime" BU_SG_REL_ MXB SG_ 1422 LED_L_HW_Idt_Z04 1000;
BA_REL_ "GenSigTimeoutTime" BU_SG_REL_ AFS SG_ 1422 LED_L_HW_Idt_Z11 1000;
BA_REL_ "GenSigTimeoutTime" BU_SG_REL_ BCM1 SG_ 1422 LED_L_HW_Idt_Z11 1000;
BA_REL_ "GenSigTimeoutTime" BU_SG_REL_ FCM SG_ 1422 LED_L_HW_Idt_Z11 1000;
BA_REL_ "GenSigTimeoutTime" BU_SG_REL_ MXB SG_ 1422 LED_L_HW_Idt_Z11 1000;
BA_REL_ "GenSigTimeoutTime" BU_SG_REL_ AFS SG_ 1422 LED_L_SW_Idt_Z06 1000;
BA_REL_ "GenSigTimeoutTime" BU_SG_REL_ BCM1 SG_ 1422 LED_L_SW_Idt_Z06 1000;
BA_REL_ "GenSigTimeoutTime" BU_SG_REL_ FCM SG_ 1422 LED_L_SW_Idt_Z06 1000;
BA_REL_ "GenSigTimeoutTime" BU_SG_REL_ MXB SG_ 1422 LED_L_SW_Idt_Z06 1000;
BA_REL_ "GenSigTimeoutTime" BU_SG_REL_ AFS SG_ 1422 LED_L_SW_Idx_Z02 1000;
BA_REL_ "GenSigTimeoutTime" BU_SG_REL_ BCM1 SG_ 1422 LED_L_SW_Idx_Z02 1000;
BA_REL_ "GenSigTimeoutTime" BU_SG_REL_ FCM SG_ 1422 LED_L_SW_Idx_Z02 1000;
BA_REL_ "GenSigTimeoutTime" BU_SG_REL_ MXB SG_ 1422 LED_L_SW_Idx_Z02 1000;
BA_REL_ "GenSigTimeoutTime" BU_SG_REL_ AFS SG_ 1422 LED_L_HW_Idt_Z05 1000;
BA_REL_ "GenSigTimeoutTime" BU_SG_REL_ BCM1 SG_ 1422 LED_L_HW_Idt_Z05 1000;
BA_REL_ "GenSigTimeoutTime" BU_SG_REL_ FCM SG_ 1422 LED_L_HW_Idt_Z05 1000;
BA_REL_ "GenSigTimeoutTime" BU_SG_REL_ MXB SG_ 1422 LED_L_HW_Idt_Z05 1000;
BA_REL_ "GenSigTimeoutTime" BU_SG_REL_ AFS SG_ 1422 LED_L_HW_Idx_Z01 1000;
BA_REL_ "GenSigTimeoutTime" BU_SG_REL_ BCM1 SG_ 1422 LED_L_HW_Idx_Z01 1000;
BA_REL_ "GenSigTimeoutTime" BU_SG_REL_ FCM SG_ 1422 LED_L_HW_Idx_Z01 1000;
BA_REL_ "GenSigTimeoutTime" BU_SG_REL_ MXB SG_ 1422 LED_L_HW_Idx_Z01 1000;
BA_REL_ "GenSigTimeoutTime" BU_SG_REL_ AFS SG_ 1422 LED_L_SW_Idt_Z07 1000;
BA_REL_ "GenSigTimeoutTime" BU_SG_REL_ BCM1 SG_ 1422 LED_L_SW_Idt_Z07 1000;
BA_REL_ "GenSigTimeoutTime" BU_SG_REL_ FCM SG_ 1422 LED_L_SW_Idt_Z07 1000;
BA_REL_ "GenSigTimeoutTime" BU_SG_REL_ MXB SG_ 1422 LED_L_SW_Idt_Z07 1000;
BA_REL_ "GenSigTimeoutTime" BU_SG_REL_ AFS SG_ 1422 LED_L_SW_Idx_Z03 1000;
BA_REL_ "GenSigTimeoutTime" BU_SG_REL_ BCM1 SG_ 1422 LED_L_SW_Idx_Z03 1000;
BA_REL_ "GenSigTimeoutTime" BU_SG_REL_ FCM SG_ 1422 LED_L_SW_Idx_Z03 1000;
BA_REL_ "GenSigTimeoutTime" BU_SG_REL_ MXB SG_ 1422 LED_L_SW_Idx_Z03 1000;
BA_REL_ "GenSigTimeoutTime" BU_SG_REL_ AFS SG_ 1422 LED_L_HW_Idt_Z06 1000;
BA_REL_ "GenSigTimeoutTime" BU_SG_REL_ BCM1 SG_ 1422 LED_L_HW_Idt_Z06 1000;
BA_REL_ "GenSigTimeoutTime" BU_SG_REL_ FCM SG_ 1422 LED_L_HW_Idt_Z06 1000;
BA_REL_ "GenSigTimeoutTime" BU_SG_REL_ MXB SG_ 1422 LED_L_HW_Idt_Z06 1000;
BA_REL_ "GenSigTimeoutTime" BU_SG_REL_ AFS SG_ 1422 LED_L_HW_Idx_Z02 1000;
BA_REL_ "GenSigTimeoutTime" BU_SG_REL_ BCM1 SG_ 1422 LED_L_HW_Idx_Z02 1000;
BA_REL_ "GenSigTimeoutTime" BU_SG_REL_ FCM SG_ 1422 LED_L_HW_Idx_Z02 1000;
BA_REL_ "GenSigTimeoutTime" BU_SG_REL_ MXB SG_ 1422 LED_L_HW_Idx_Z02 1000;
BA_REL_ "GenSigTimeoutTime" BU_SG_REL_ AFS SG_ 1421 LED_R_Mux 1000;
BA_REL_ "GenSigTimeoutTime" BU_SG_REL_ BCM1 SG_ 1421 LED_R_Mux 1000;
BA_REL_ "GenSigTimeoutTime" BU_SG_REL_ FCM SG_ 1421 LED_R_Mux 1000;
BA_REL_ "GenSigTimeoutTime" BU_SG_REL_ MXB SG_ 1421 LED_R_Mux 1000;
BA_REL_ "GenSigTimeoutTime" BU_SG_REL_ AFS SG_ 1421 LED_R_SW_Idt_Z01 1000;
BA_REL_ "GenSigTimeoutTime" BU_SG_REL_ BCM1 SG_ 1421 LED_R_SW_Idt_Z01 1000;
BA_REL_ "GenSigTimeoutTime" BU_SG_REL_ FCM SG_ 1421 LED_R_SW_Idt_Z01 1000;
BA_REL_ "GenSigTimeoutTime" BU_SG_REL_ MXB SG_ 1421 LED_R_SW_Idt_Z01 1000;
BA_REL_ "GenSigTimeoutTime" BU_SG_REL_ AFS SG_ 1421 LED_R_SW_Idt_Z08 1000;
BA_REL_ "GenSigTimeoutTime" BU_SG_REL_ BCM1 SG_ 1421 LED_R_SW_Idt_Z08 1000;
BA_REL_ "GenSigTimeoutTime" BU_SG_REL_ FCM SG_ 1421 LED_R_SW_Idt_Z08 1000;
BA_REL_ "GenSigTimeoutTime" BU_SG_REL_ MXB SG_ 1421 LED_R_SW_Idt_Z08 1000;
BA_REL_ "GenSigTimeoutTime" BU_SG_REL_ AFS SG_ 1421 LED_R_SW_Idx_Z04 1000;
BA_REL_ "GenSigTimeoutTime" BU_SG_REL_ BCM1 SG_ 1421 LED_R_SW_Idx_Z04 1000;
BA_REL_ "GenSigTimeoutTime" BU_SG_REL_ FCM SG_ 1421 LED_R_SW_Idx_Z04 1000;
BA_REL_ "GenSigTimeoutTime" BU_SG_REL_ MXB SG_ 1421 LED_R_SW_Idx_Z04 1000;
BA_REL_ "GenSigTimeoutTime" BU_SG_REL_ AFS SG_ 1421 LED_R_HW_Idt_Z07 1000;
BA_REL_ "GenSigTimeoutTime" BU_SG_REL_ BCM1 SG_ 1421 LED_R_HW_Idt_Z07 1000;
BA_REL_ "GenSigTimeoutTime" BU_SG_REL_ FCM SG_ 1421 LED_R_HW_Idt_Z07 1000;
BA_REL_ "GenSigTimeoutTime" BU_SG_REL_ MXB SG_ 1421 LED_R_HW_Idt_Z07 1000;
BA_REL_ "GenSigTimeoutTime" BU_SG_REL_ AFS SG_ 1421 LED_R_HW_Idx_Z03 1000;
BA_REL_ "GenSigTimeoutTime" BU_SG_REL_ BCM1 SG_ 1421 LED_R_HW_Idx_Z03 1000;
BA_REL_ "GenSigTimeoutTime" BU_SG_REL_ FCM SG_ 1421 LED_R_HW_Idx_Z03 1000;
BA_REL_ "GenSigTimeoutTime" BU_SG_REL_ MXB SG_ 1421 LED_R_HW_Idx_Z03 1000;
BA_REL_ "GenSigTimeoutTime" BU_SG_REL_ AFS SG_ 1421 LED_R_SW_Idt_Z02 1000;
BA_REL_ "GenSigTimeoutTime" BU_SG_REL_ BCM1 SG_ 1421 LED_R_SW_Idt_Z02 1000;
BA_REL_ "GenSigTimeoutTime" BU_SG_REL_ FCM SG_ 1421 LED_R_SW_Idt_Z02 1000;
BA_REL_ "GenSigTimeoutTime" BU_SG_REL_ MXB SG_ 1421 LED_R_SW_Idt_Z02 1000;
BA_REL_ "GenSigTimeoutTime" BU_SG_REL_ AFS SG_ 1421 LED_R_SW_Idt_Z09 1000;
BA_REL_ "GenSigTimeoutTime" BU_SG_REL_ BCM1 SG_ 1421 LED_R_SW_Idt_Z09 1000;
BA_REL_ "GenSigTimeoutTime" BU_SG_REL_ FCM SG_ 1421 LED_R_SW_Idt_Z09 1000;
BA_REL_ "GenSigTimeoutTime" BU_SG_REL_ MXB SG_ 1421 LED_R_SW_Idt_Z09 1000;
BA_REL_ "GenSigTimeoutTime" BU_SG_REL_ AFS SG_ 1421 LED_R_HW_Idt_Z01 1000;
BA_REL_ "GenSigTimeoutTime" BU_SG_REL_ BCM1 SG_ 1421 LED_R_HW_Idt_Z01 1000;
BA_REL_ "GenSigTimeoutTime" BU_SG_REL_ FCM SG_ 1421 LED_R_HW_Idt_Z01 1000;
BA_REL_ "GenSigTimeoutTime" BU_SG_REL_ MXB SG_ 1421 LED_R_HW_Idt_Z01 1000;
BA_REL_ "GenSigTimeoutTime" BU_SG_REL_ AFS SG_ 1421 LED_R_HW_Idt_Z08 1000;
BA_REL_ "GenSigTimeoutTime" BU_SG_REL_ BCM1 SG_ 1421 LED_R_HW_Idt_Z08 1000;
BA_REL_ "GenSigTimeoutTime" BU_SG_REL_ FCM SG_ 1421 LED_R_HW_Idt_Z08 1000;
BA_REL_ "GenSigTimeoutTime" BU_SG_REL_ MXB SG_ 1421 LED_R_HW_Idt_Z08 1000;
BA_REL_ "GenSigTimeoutTime" BU_SG_REL_ AFS SG_ 1421 LED_R_SW_Idt_Z03 1000;
BA_REL_ "GenSigTimeoutTime" BU_SG_REL_ BCM1 SG_ 1421 LED_R_SW_Idt_Z03 1000;
BA_REL_ "GenSigTimeoutTime" BU_SG_REL_ FCM SG_ 1421 LED_R_SW_Idt_Z03 1000;
BA_REL_ "GenSigTimeoutTime" BU_SG_REL_ MXB SG_ 1421 LED_R_SW_Idt_Z03 1000;
BA_REL_ "GenSigTimeoutTime" BU_SG_REL_ AFS SG_ 1421 LED_R_SW_Idt_Z10 1000;
BA_REL_ "GenSigTimeoutTime" BU_SG_REL_ BCM1 SG_ 1421 LED_R_SW_Idt_Z10 1000;
BA_REL_ "GenSigTimeoutTime" BU_SG_REL_ FCM SG_ 1421 LED_R_SW_Idt_Z10 1000;
BA_REL_ "GenSigTimeoutTime" BU_SG_REL_ MXB SG_ 1421 LED_R_SW_Idt_Z10 1000;
BA_REL_ "GenSigTimeoutTime" BU_SG_REL_ AFS SG_ 1421 LED_R_HW_Idt_Z02 1000;
BA_REL_ "GenSigTimeoutTime" BU_SG_REL_ BCM1 SG_ 1421 LED_R_HW_Idt_Z02 1000;
BA_REL_ "GenSigTimeoutTime" BU_SG_REL_ FCM SG_ 1421 LED_R_HW_Idt_Z02 1000;
BA_REL_ "GenSigTimeoutTime" BU_SG_REL_ MXB SG_ 1421 LED_R_HW_Idt_Z02 1000;
BA_REL_ "GenSigTimeoutTime" BU_SG_REL_ AFS SG_ 1421 LED_R_HW_Idt_Z09 1000;
BA_REL_ "GenSigTimeoutTime" BU_SG_REL_ BCM1 SG_ 1421 LED_R_HW_Idt_Z09 1000;
BA_REL_ "GenSigTimeoutTime" BU_SG_REL_ FCM SG_ 1421 LED_R_HW_Idt_Z09 1000;
BA_REL_ "GenSigTimeoutTime" BU_SG_REL_ MXB SG_ 1421 LED_R_HW_Idt_Z09 1000;
BA_REL_ "GenSigTimeoutTime" BU_SG_REL_ AFS SG_ 1421 LED_R_SW_Idt_Z04 1000;
BA_REL_ "GenSigTimeoutTime" BU_SG_REL_ BCM1 SG_ 1421 LED_R_SW_Idt_Z04 1000;
BA_REL_ "GenSigTimeoutTime" BU_SG_REL_ FCM SG_ 1421 LED_R_SW_Idt_Z04 1000;
BA_REL_ "GenSigTimeoutTime" BU_SG_REL_ MXB SG_ 1421 LED_R_SW_Idt_Z04 1000;
BA_REL_ "GenSigTimeoutTime" BU_SG_REL_ AFS SG_ 1421 LED_R_SW_Idt_Z11 1000;
BA_REL_ "GenSigTimeoutTime" BU_SG_REL_ BCM1 SG_ 1421 LED_R_SW_Idt_Z11 1000;
BA_REL_ "GenSigTimeoutTime" BU_SG_REL_ FCM SG_ 1421 LED_R_SW_Idt_Z11 1000;
BA_REL_ "GenSigTimeoutTime" BU_SG_REL_ MXB SG_ 1421 LED_R_SW_Idt_Z11 1000;
BA_REL_ "GenSigTimeoutTime" BU_SG_REL_ AFS SG_ 1421 LED_R_HW_Idt_Z03 1000;
BA_REL_ "GenSigTimeoutTime" BU_SG_REL_ BCM1 SG_ 1421 LED_R_HW_Idt_Z03 1000;
BA_REL_ "GenSigTimeoutTime" BU_SG_REL_ FCM SG_ 1421 LED_R_HW_Idt_Z03 1000;
BA_REL_ "GenSigTimeoutTime" BU_SG_REL_ MXB SG_ 1421 LED_R_HW_Idt_Z03 1000;
BA_REL_ "GenSigTimeoutTime" BU_SG_REL_ AFS SG_ 1421 LED_R_HW_Idt_Z10 1000;
BA_REL_ "GenSigTimeoutTime" BU_SG_REL_ BCM1 SG_ 1421 LED_R_HW_Idt_Z10 1000;
BA_REL_ "GenSigTimeoutTime" BU_SG_REL_ FCM SG_ 1421 LED_R_HW_Idt_Z10 1000;
BA_REL_ "GenSigTimeoutTime" BU_SG_REL_ MXB SG_ 1421 LED_R_HW_Idt_Z10 1000;
BA_REL_ "GenSigTimeoutTime" BU_SG_REL_ AFS SG_ 1421 LED_R_SW_Idt_Z05 1000;
BA_REL_ "GenSigTimeoutTime" BU_SG_REL_ BCM1 SG_ 1421 LED_R_SW_Idt_Z05 1000;
BA_REL_ "GenSigTimeoutTime" BU_SG_REL_ FCM SG_ 1421 LED_R_SW_Idt_Z05 1000;
BA_REL_ "GenSigTimeoutTime" BU_SG_REL_ MXB SG_ 1421 LED_R_SW_Idt_Z05 1000;
BA_REL_ "GenSigTimeoutTime" BU_SG_REL_ AFS SG_ 1421 LED_R_SW_Idx_Z01 1000;
BA_REL_ "GenSigTimeoutTime" BU_SG_REL_ BCM1 SG_ 1421 LED_R_SW_Idx_Z01 1000;
BA_REL_ "GenSigTimeoutTime" BU_SG_REL_ FCM SG_ 1421 LED_R_SW_Idx_Z01 1000;
BA_REL_ "GenSigTimeoutTime" BU_SG_REL_ MXB SG_ 1421 LED_R_SW_Idx_Z01 1000;
BA_REL_ "GenSigTimeoutTime" BU_SG_REL_ AFS SG_ 1421 LED_R_HW_Idt_Z04 1000;
BA_REL_ "GenSigTimeoutTime" BU_SG_REL_ BCM1 SG_ 1421 LED_R_HW_Idt_Z04 1000;
BA_REL_ "GenSigTimeoutTime" BU_SG_REL_ FCM SG_ 1421 LED_R_HW_Idt_Z04 1000;
BA_REL_ "GenSigTimeoutTime" BU_SG_REL_ MXB SG_ 1421 LED_R_HW_Idt_Z04 1000;
BA_REL_ "GenSigTimeoutTime" BU_SG_REL_ AFS SG_ 1421 LED_R_HW_Idt_Z11 1000;
BA_REL_ "GenSigTimeoutTime" BU_SG_REL_ BCM1 SG_ 1421 LED_R_HW_Idt_Z11 1000;
BA_REL_ "GenSigTimeoutTime" BU_SG_REL_ FCM SG_ 1421 LED_R_HW_Idt_Z11 1000;
BA_REL_ "GenSigTimeoutTime" BU_SG_REL_ MXB SG_ 1421 LED_R_HW_Idt_Z11 1000;
BA_REL_ "GenSigTimeoutTime" BU_SG_REL_ AFS SG_ 1421 LED_R_SW_Idt_Z06 1000;
BA_REL_ "GenSigTimeoutTime" BU_SG_REL_ BCM1 SG_ 1421 LED_R_SW_Idt_Z06 1000;
BA_REL_ "GenSigTimeoutTime" BU_SG_REL_ FCM SG_ 1421 LED_R_SW_Idt_Z06 1000;
BA_REL_ "GenSigTimeoutTime" BU_SG_REL_ MXB SG_ 1421 LED_R_SW_Idt_Z06 1000;
BA_REL_ "GenSigTimeoutTime" BU_SG_REL_ AFS SG_ 1421 LED_R_SW_Idx_Z02 1000;
BA_REL_ "GenSigTimeoutTime" BU_SG_REL_ BCM1 SG_ 1421 LED_R_SW_Idx_Z02 1000;
BA_REL_ "GenSigTimeoutTime" BU_SG_REL_ FCM SG_ 1421 LED_R_SW_Idx_Z02 1000;
BA_REL_ "GenSigTimeoutTime" BU_SG_REL_ MXB SG_ 1421 LED_R_SW_Idx_Z02 1000;
BA_REL_ "GenSigTimeoutTime" BU_SG_REL_ AFS SG_ 1421 LED_R_HW_Idt_Z05 1000;
BA_REL_ "GenSigTimeoutTime" BU_SG_REL_ BCM1 SG_ 1421 LED_R_HW_Idt_Z05 1000;
BA_REL_ "GenSigTimeoutTime" BU_SG_REL_ FCM SG_ 1421 LED_R_HW_Idt_Z05 1000;
BA_REL_ "GenSigTimeoutTime" BU_SG_REL_ MXB SG_ 1421 LED_R_HW_Idt_Z05 1000;
BA_REL_ "GenSigTimeoutTime" BU_SG_REL_ AFS SG_ 1421 LED_R_HW_Idx_Z01 1000;
BA_REL_ "GenSigTimeoutTime" BU_SG_REL_ BCM1 SG_ 1421 LED_R_HW_Idx_Z01 1000;
BA_REL_ "GenSigTimeoutTime" BU_SG_REL_ FCM SG_ 1421 LED_R_HW_Idx_Z01 1000;
BA_REL_ "GenSigTimeoutTime" BU_SG_REL_ MXB SG_ 1421 LED_R_HW_Idx_Z01 1000;
BA_REL_ "GenSigTimeoutTime" BU_SG_REL_ AFS SG_ 1421 LED_R_SW_Idt_Z07 1000;
BA_REL_ "GenSigTimeoutTime" BU_SG_REL_ BCM1 SG_ 1421 LED_R_SW_Idt_Z07 1000;
BA_REL_ "GenSigTimeoutTime" BU_SG_REL_ FCM SG_ 1421 LED_R_SW_Idt_Z07 1000;
BA_REL_ "GenSigTimeoutTime" BU_SG_REL_ MXB SG_ 1421 LED_R_SW_Idt_Z07 1000;
BA_REL_ "GenSigTimeoutTime" BU_SG_REL_ AFS SG_ 1421 LED_R_SW_Idx_Z03 1000;
BA_REL_ "GenSigTimeoutTime" BU_SG_REL_ BCM1 SG_ 1421 LED_R_SW_Idx_Z03 1000;
BA_REL_ "GenSigTimeoutTime" BU_SG_REL_ FCM SG_ 1421 LED_R_SW_Idx_Z03 1000;
BA_REL_ "GenSigTimeoutTime" BU_SG_REL_ MXB SG_ 1421 LED_R_SW_Idx_Z03 1000;
BA_REL_ "GenSigTimeoutTime" BU_SG_REL_ AFS SG_ 1421 LED_R_HW_Idt_Z06 1000;
BA_REL_ "GenSigTimeoutTime" BU_SG_REL_ BCM1 SG_ 1421 LED_R_HW_Idt_Z06 1000;
BA_REL_ "GenSigTimeoutTime" BU_SG_REL_ FCM SG_ 1421 LED_R_HW_Idt_Z06 1000;
BA_REL_ "GenSigTimeoutTime" BU_SG_REL_ MXB SG_ 1421 LED_R_HW_Idt_Z06 1000;
BA_REL_ "GenSigTimeoutTime" BU_SG_REL_ AFS SG_ 1421 LED_R_HW_Idx_Z02 1000;
BA_REL_ "GenSigTimeoutTime" BU_SG_REL_ BCM1 SG_ 1421 LED_R_HW_Idx_Z02 1000;
BA_REL_ "GenSigTimeoutTime" BU_SG_REL_ FCM SG_ 1421 LED_R_HW_Idx_Z02 1000;
BA_REL_ "GenSigTimeoutTime" BU_SG_REL_ MXB SG_ 1421 LED_R_HW_Idx_Z02 1000;
BA_REL_ "GenSigTimeoutTime" BU_SG_REL_ AFS SG_ 1290 LED_L_Scheinw_Var_1 1000;
BA_REL_ "GenSigTimeoutTime" BU_SG_REL_ BCM1 SG_ 1290 LED_L_Scheinw_Var_1 1000;
BA_REL_ "GenSigTimeoutTime" BU_SG_REL_ FCM SG_ 1290 LED_L_Scheinw_Var_1 1000;
BA_REL_ "GenSigTimeoutTime" BU_SG_REL_ MXB SG_ 1290 LED_L_Scheinw_Var_1 1000;
BA_REL_ "GenSigTimeoutTime" BU_SG_REL_ AFS SG_ 1290 LED_L_Scheinw_Var_2 1000;
BA_REL_ "GenSigTimeoutTime" BU_SG_REL_ BCM1 SG_ 1290 LED_L_Scheinw_Var_2 1000;
BA_REL_ "GenSigTimeoutTime" BU_SG_REL_ FCM SG_ 1290 LED_L_Scheinw_Var_2 1000;
BA_REL_ "GenSigTimeoutTime" BU_SG_REL_ MXB SG_ 1290 LED_L_Scheinw_Var_2 1000;
BA_REL_ "GenSigTimeoutTime" BU_SG_REL_ AFS SG_ 1291 LED_R_Scheinw_Var_1 1000;
BA_REL_ "GenSigTimeoutTime" BU_SG_REL_ BCM1 SG_ 1291 LED_R_Scheinw_Var_1 1000;
BA_REL_ "GenSigTimeoutTime" BU_SG_REL_ FCM SG_ 1291 LED_R_Scheinw_Var_1 1000;
BA_REL_ "GenSigTimeoutTime" BU_SG_REL_ MXB SG_ 1291 LED_R_Scheinw_Var_1 1000;
BA_REL_ "GenSigTimeoutTime" BU_SG_REL_ AFS SG_ 1291 LED_R_Scheinw_Var_2 1000;
BA_REL_ "GenSigTimeoutTime" BU_SG_REL_ BCM1 SG_ 1291 LED_R_Scheinw_Var_2 1000;
BA_REL_ "GenSigTimeoutTime" BU_SG_REL_ FCM SG_ 1291 LED_R_Scheinw_Var_2 1000;
BA_REL_ "GenSigTimeoutTime" BU_SG_REL_ MXB SG_ 1291 LED_R_Scheinw_Var_2 1000;
BA_REL_ "GenSigTimeoutTime" BU_SG_REL_ LED_DK3_LM_L SG_ 2589283615 LED_L_DABL_LED_01_Anf 2000;
BA_REL_ "GenSigTimeoutTime" BU_SG_REL_ LLP_L SG_ 2589283615 LED_L_DABL_LED_01_Anf 2000;
BA_REL_ "GenSigTimeoutTime" BU_SG_REL_ LED_DK3_LM_L SG_ 2589283615 LED_L_DABL_LED_02_Anf 2000;
BA_REL_ "GenSigTimeoutTime" BU_SG_REL_ LLP_L SG_ 2589283615 LED_L_DABL_LED_02_Anf 2000;
BA_REL_ "GenSigTimeoutTime" BU_SG_REL_ LED_DK3_LM_L SG_ 2589283615 LED_L_DABL_LED_03_Anf 2000;
BA_REL_ "GenSigTimeoutTime" BU_SG_REL_ LLP_L SG_ 2589283615 LED_L_DABL_LED_03_Anf 2000;
BA_REL_ "GenSigTimeoutTime" BU_SG_REL_ LED_DK3_LM_L SG_ 2589283615 LED_L_DABL_LED_04_Anf 2000;
BA_REL_ "GenSigTimeoutTime" BU_SG_REL_ LLP_L SG_ 2589283615 LED_L_DABL_LED_04_Anf 2000;
BA_REL_ "GenSigTimeoutTime" BU_SG_REL_ LED_DK3_LM_L SG_ 2589283615 LED_L_DABL_LED_05_Anf 2000;
BA_REL_ "GenSigTimeoutTime" BU_SG_REL_ LLP_L SG_ 2589283615 LED_L_DABL_LED_05_Anf 2000;
BA_REL_ "GenSigTimeoutTime" BU_SG_REL_ LED_DK3_LM_L SG_ 2589283615 LED_L_DABL_LED_06_Anf 2000;
BA_REL_ "GenSigTimeoutTime" BU_SG_REL_ LLP_L SG_ 2589283615 LED_L_DABL_LED_06_Anf 2000;
BA_REL_ "GenSigTimeoutTime" BU_SG_REL_ LED_DK3_LM_L SG_ 2589283615 LED_L_DABL_LED_07_Anf 2000;
BA_REL_ "GenSigTimeoutTime" BU_SG_REL_ LLP_L SG_ 2589283615 LED_L_DABL_LED_07_Anf 2000;
BA_REL_ "GenSigTimeoutTime" BU_SG_REL_ LED_DK3_LM_L SG_ 2589283615 LED_L_DABL_LED_08_Anf 2000;
BA_REL_ "GenSigTimeoutTime" BU_SG_REL_ LLP_L SG_ 2589283615 LED_L_DABL_LED_08_Anf 2000;
BA_REL_ "GenSigTimeoutTime" BU_SG_REL_ LED_DK3_LM_L SG_ 2589283615 LED_L_DABL_LED_09_Anf 2000;
BA_REL_ "GenSigTimeoutTime" BU_SG_REL_ LLP_L SG_ 2589283615 LED_L_DABL_LED_09_Anf 2000;
BA_REL_ "GenSigTimeoutTime" BU_SG_REL_ LED_DK3_LM_L SG_ 2589283615 LED_L_DABL_LED_10_Anf 2000;
BA_REL_ "GenSigTimeoutTime" BU_SG_REL_ LLP_L SG_ 2589283615 LED_L_DABL_LED_10_Anf 2000;
BA_REL_ "GenSigTimeoutTime" BU_SG_REL_ LED_DK3_LM_L SG_ 2463978600 LED_L_DABL_LED_11_Anf 2000;
BA_REL_ "GenSigTimeoutTime" BU_SG_REL_ LLP_L SG_ 2463978600 LED_L_DABL_LED_11_Anf 2000;
BA_REL_ "GenSigTimeoutTime" BU_SG_REL_ LED_DK3_LM_L SG_ 2463978600 LED_L_DABL_LED_12_Anf 2000;
BA_REL_ "GenSigTimeoutTime" BU_SG_REL_ LLP_L SG_ 2463978600 LED_L_DABL_LED_12_Anf 2000;
BA_REL_ "GenSigTimeoutTime" BU_SG_REL_ LED_DK3_LM_L SG_ 2463978600 LED_L_DABL_LED_13_Anf 2000;
BA_REL_ "GenSigTimeoutTime" BU_SG_REL_ LLP_L SG_ 2463978600 LED_L_DABL_LED_13_Anf 2000;
BA_REL_ "GenSigTimeoutTime" BU_SG_REL_ LED_DK3_LM_L SG_ 2463978600 LED_L_DABL_LED_14_Anf 2000;
BA_REL_ "GenSigTimeoutTime" BU_SG_REL_ LLP_L SG_ 2463978600 LED_L_DABL_LED_14_Anf 2000;
BA_REL_ "GenSigTimeoutTime" BU_SG_REL_ LED_DK3_LM_L SG_ 2463978600 LED_L_DABL_LED_15_Anf 2000;
BA_REL_ "GenSigTimeoutTime" BU_SG_REL_ LLP_L SG_ 2463978600 LED_L_DABL_LED_15_Anf 2000;
BA_REL_ "GenSigTimeoutTime" BU_SG_REL_ LED_DK3_LM_L SG_ 2463978600 LED_L_DABL_LED_16_Anf 2000;
BA_REL_ "GenSigTimeoutTime" BU_SG_REL_ LLP_L SG_ 2463978600 LED_L_DABL_LED_16_Anf 2000;
BA_REL_ "GenSigTimeoutTime" BU_SG_REL_ LED_DK3_LM_L SG_ 2463978600 LED_L_DABL_LED_17_Anf 2000;
BA_REL_ "GenSigTimeoutTime" BU_SG_REL_ LLP_L SG_ 2463978600 LED_L_DABL_LED_17_Anf 2000;
BA_REL_ "GenSigTimeoutTime" BU_SG_REL_ LED_DK3_LM_L SG_ 2463978600 LED_L_DABL_LED_18_Anf 2000;
BA_REL_ "GenSigTimeoutTime" BU_SG_REL_ LLP_L SG_ 2463978600 LED_L_DABL_LED_18_Anf 2000;
BA_REL_ "GenSigTimeoutTime" BU_SG_REL_ LED_DK3_LM_L SG_ 2463978600 LED_L_DABL_LED_19_Anf 2000;
BA_REL_ "GenSigTimeoutTime" BU_SG_REL_ LLP_L SG_ 2463978600 LED_L_DABL_LED_19_Anf 2000;
BA_REL_ "GenSigTimeoutTime" BU_SG_REL_ LED_DK3_LM_L SG_ 2463978600 LED_L_DABL_LED_20_Anf 2000;
BA_REL_ "GenSigTimeoutTime" BU_SG_REL_ LLP_L SG_ 2463978600 LED_L_DABL_LED_20_Anf 2000;
BA_REL_ "GenSigTimeoutTime" BU_SG_REL_ LED_DK3_LM_L SG_ 836 LED_L_SABL_LED_01_Anf 2000;
BA_REL_ "GenSigTimeoutTime" BU_SG_REL_ LLP_L SG_ 836 LED_L_SABL_LED_01_Anf 2000;
BA_REL_ "GenSigTimeoutTime" BU_SG_REL_ LED_DK3_LM_L SG_ 836 LED_L_SABL_LED_02_Anf 2000;
BA_REL_ "GenSigTimeoutTime" BU_SG_REL_ LLP_L SG_ 836 LED_L_SABL_LED_02_Anf 2000;
BA_REL_ "GenSigTimeoutTime" BU_SG_REL_ LED_DK3_LM_L SG_ 836 LED_L_SABL_LED_03_Anf 2000;
BA_REL_ "GenSigTimeoutTime" BU_SG_REL_ LLP_L SG_ 836 LED_L_SABL_LED_03_Anf 2000;
BA_REL_ "GenSigTimeoutTime" BU_SG_REL_ LED_DK3_LM_L SG_ 836 LED_L_SABL_LED_04_Anf 2000;
BA_REL_ "GenSigTimeoutTime" BU_SG_REL_ LLP_L SG_ 836 LED_L_SABL_LED_04_Anf 2000;
BA_REL_ "GenSigTimeoutTime" BU_SG_REL_ LED_DK3_LM_L SG_ 836 LED_L_SABL_LED_05_Anf 2000;
BA_REL_ "GenSigTimeoutTime" BU_SG_REL_ LLP_L SG_ 836 LED_L_SABL_LED_05_Anf 2000;
BA_REL_ "GenSigTimeoutTime" BU_SG_REL_ LED_DK3_LM_L SG_ 836 LED_L_SABL_LED_06_Anf 2000;
BA_REL_ "GenSigTimeoutTime" BU_SG_REL_ LLP_L SG_ 836 LED_L_SABL_LED_06_Anf 2000;
BA_REL_ "GenSigTimeoutTime" BU_SG_REL_ LED_DK3_LM_L SG_ 836 LED_L_SABL_LED_07_Anf 2000;
BA_REL_ "GenSigTimeoutTime" BU_SG_REL_ LLP_L SG_ 836 LED_L_SABL_LED_07_Anf 2000;
BA_REL_ "GenSigTimeoutTime" BU_SG_REL_ LED_DK3_LM_L SG_ 836 LED_L_SABL_LED_08_Anf 2000;
BA_REL_ "GenSigTimeoutTime" BU_SG_REL_ LLP_L SG_ 836 LED_L_SABL_LED_08_Anf 2000;
BA_REL_ "GenSigTimeoutTime" BU_SG_REL_ LED_DK3_LM_L SG_ 836 LED_L_SABL_LED_09_Anf 2000;
BA_REL_ "GenSigTimeoutTime" BU_SG_REL_ LLP_L SG_ 836 LED_L_SABL_LED_09_Anf 2000;
BA_REL_ "GenSigTimeoutTime" BU_SG_REL_ LED_DK3_LM_L SG_ 836 LED_L_SABL_LED_10_Anf 2000;
BA_REL_ "GenSigTimeoutTime" BU_SG_REL_ LLP_L SG_ 836 LED_L_SABL_LED_10_Anf 2000;
VAL_ 1342 LED_L_Abbiegel_Def_1 0 "kein_Fehler" 1 "Fehler" ;
VAL_ 1342 LED_L_Abbiegel_Def_2 0 "kein_Fehler" 1 "Fehler" ;
VAL_ 1342 LED_L_Abbiegel_Def_3 0 "kein_Fehler" 1 "Fehler" ;
VAL_ 1342 LED_L_Abbiegel_Def_4 0 "kein_Fehler" 1 "Fehler" ;
VAL_ 1342 LED_L_Abbiegel_Def_5 0 "kein_Fehler" 1 "Fehler" ;
VAL_ 1342 LED_L_Abbiegel_Def_6 0 "kein_Fehler" 1 "Fehler" ;
VAL_ 1342 LED_L_Abbiegel_Def_7 0 "kein_Fehler" 1 "Fehler" ;
VAL_ 1342 LED_L_Abbiegel_Def_Err_Gultig 0 "Fehler_nicht_gueltig" 1 "Fehler_gueltig" ;
VAL_ 1342 LED_L_Abblendl_Def_1 0 "kein_Fehler" 1 "Fehler" ;
VAL_ 1342 LED_L_Abblendl_Def_2 0 "kein_Fehler" 1 "Fehler" ;
VAL_ 1342 LED_L_Abblendl_Def_3 0 "kein_Fehler" 1 "Fehler" ;
VAL_ 1342 LED_L_Abblendl_Def_4 0 "kein_Fehler" 1 "Fehler" ;
VAL_ 1342 LED_L_Abblendl_Def_5 0 "kein_Fehler" 1 "Fehler" ;
VAL_ 1342 LED_L_Abblendl_Def_6 0 "kein_Fehler" 1 "Fehler" ;
VAL_ 1342 LED_L_Abblendl_Def_7 0 "kein_Fehler" 1 "Fehler" ;
VAL_ 1342 LED_L_Abblendl_Def_Err_Gultig 0 "Fehler_nicht_gueltig" 1 "Fehler_gueltig" ;
VAL_ 1342 LED_L_Fernl_Def_1 0 "kein_Fehler" 1 "Fehler" ;
VAL_ 1342 LED_L_Fernl_Def_2 0 "kein_Fehler" 1 "Fehler" ;
VAL_ 1342 LED_L_Fernl_Def_3 0 "kein_Fehler" 1 "Fehler" ;
VAL_ 1342 LED_L_Fernl_Def_4 0 "kein_Fehler" 1 "Fehler" ;
VAL_ 1342 LED_L_Fernl_Def_5 0 "kein_Fehler" 1 "Fehler" ;
VAL_ 1342 LED_L_Fernl_Def_6 0 "kein_Fehler" 1 "Fehler" ;
VAL_ 1342 LED_L_Fernl_Def_7 0 "kein_Fehler" 1 "Fehler" ;
VAL_ 1342 LED_L_Fernl_Def_Err_Gultig 0 "Fehler_nicht_gueltig" 1 "Fehler_gueltig" ;
VAL_ 1342 LED_L_TFL_Def_1 0 "kein_Fehler" 1 "Fehler" ;
VAL_ 1342 LED_L_TFL_Def_2 0 "kein_Fehler" 1 "Fehler" ;
VAL_ 1342 LED_L_TFL_Def_3 0 "kein_Fehler" 1 "Fehler" ;
VAL_ 1342 LED_L_TFL_Def_4 0 "kein_Fehler" 1 "Fehler" ;
VAL_ 1342 LED_L_TFL_Def_5 0 "kein_Fehler" 1 "Fehler" ;
VAL_ 1342 LED_L_TFL_Def_6 0 "kein_Fehler" 1 "Fehler" ;
VAL_ 1342 LED_L_TFL_Def_7 0 "kein_Fehler" 1 "Fehler" ;
VAL_ 1342 LED_L_TFL_Def_Err_Gultig 0 "Fehler_nicht_gueltig" 1 "Fehler_gueltig" ;
VAL_ 1342 LED_L_Allg_Elektr_Def_1 0 "kein_Fehler" 1 "Fehler" ;
VAL_ 1342 LED_L_Allg_Elektr_Def_2 0 "kein_Fehler" 1 "Fehler" ;
VAL_ 1342 LED_L_Allg_Elektr_Def_3 0 "kein_Fehler" 1 "Fehler" ;
VAL_ 1342 LED_L_Allg_Elektr_Def_4 0 "kein_Fehler" 1 "Fehler" ;
VAL_ 1342 LED_L_Allg_Elektr_Def_5 0 "kein_Fehler" 1 "Fehler" ;
VAL_ 1342 LED_L_Allg_Elektr_Def_6 0 "kein_Fehler" 1 "Fehler" ;
VAL_ 1342 LED_L_Allg_Elektr_Def_7 0 "kein_Fehler" 1 "Fehler" ;
VAL_ 1342 LED_L_Allg_Elektr_Def_8 0 "kein_Fehler" 1 "Fehler" ;
VAL_ 1342 LED_L_Allg_Elektr_Def_Err_Gultig 0 "Fehler_nicht_gueltig" 1 "Fehler_gueltig" ;
VAL_ 1342 LED_L_Luefter_1_Def_1 0 "kein_Fehler" 1 "Fehler" ;
VAL_ 1342 LED_L_Luefter_1_Def_2 0 "kein_Fehler" 1 "Fehler" ;
VAL_ 1342 LED_L_Luefter_1_Def_3 0 "kein_Fehler" 1 "Fehler" ;
VAL_ 1342 LED_L_Luefter_1_Def_4 0 "kein_Fehler" 1 "Fehler" ;
VAL_ 1342 LED_L_Luefter_2_Def_1 0 "kein_Fehler" 1 "Fehler" ;
VAL_ 1342 LED_L_Luefter_2_Def_2 0 "kein_Fehler" 1 "Fehler" ;
VAL_ 1342 LED_L_Luefter_2_Def_3 0 "kein_Fehler" 1 "Fehler" ;
VAL_ 1342 LED_L_Luefter_2_Def_4 0 "kein_Fehler" 1 "Fehler" ;
VAL_ 1342 LED_L_Luefter_1_Def_Err_Gultig 0 "Fehler_nicht_gueltig" 1 "Fehler_gueltig" ;
VAL_ 1342 LED_L_Luefter_2_Def_Err_Gultig 0 "Fehler_nicht_gueltig" 1 "Fehler_gueltig" ;
VAL_ 1342 LED_L_ECE_SAE_Umschaltung_Def 0 "kein_Fehler" 1 "Fehler" ;
VAL_ 2527679494 LED_L_Nebel_All_Def_1 0 "kein_Fehler" 1 "Fehler" ;
VAL_ 2527679494 LED_L_Nebel_All_Def_2 0 "kein_Fehler" 1 "Fehler" ;
VAL_ 2527679494 LED_L_Nebel_All_Def_3 0 "kein_Fehler" 1 "Fehler" ;
VAL_ 2527679494 LED_L_Nebel_All_Def_4 0 "kein_Fehler" 1 "Fehler" ;
VAL_ 2527679494 LED_L_Nebel_All_Def_5 0 "kein_Fehler" 1 "Fehler" ;
VAL_ 2527679494 LED_L_Nebel_All_Def_6 0 "kein_Fehler" 1 "Fehler" ;
VAL_ 2527679494 LED_L_Nebel_All_Def_7 0 "kein_Fehler" 1 "Fehler" ;
VAL_ 2527679494 LED_L_Nebel_All_Def_Err_Gultig 0 "Fehler_nicht_gueltig" 1 "Fehler_gueltig" ;
VAL_ 2527679494 LED_L_Touristenl_Def_1 0 "kein_Fehler" 1 "Fehler" ;
VAL_ 2527679494 LED_L_Touristenl_Def_2 0 "kein_Fehler" 1 "Fehler" ;
VAL_ 2527679494 LED_L_Touristenl_Def_3 0 "kein_Fehler" 1 "Fehler" ;
VAL_ 2527679494 LED_L_Touristenl_Def_4 0 "kein_Fehler" 1 "Fehler" ;
VAL_ 2527679494 LED_L_Touristenl_Def_5 0 "kein_Fehler" 1 "Fehler" ;
VAL_ 2527679494 LED_L_Touristenl_Def_6 0 "kein_Fehler" 1 "Fehler" ;
VAL_ 2527679494 LED_L_Touristenl_Def_7 0 "kein_Fehler" 1 "Fehler" ;
VAL_ 2527679494 LED_L_Touristenl_Def_Err_Gultig 0 "Fehler_nicht_gueltig" 1 "Fehler_gueltig" ;
VAL_ 2527679494 LED_L_Autobahnl_Def_1 0 "kein_Fehler" 1 "Fehler" ;
VAL_ 2527679494 LED_L_Autobahnl_Def_2 0 "kein_Fehler" 1 "Fehler" ;
VAL_ 2527679494 LED_L_Autobahnl_Def_3 0 "kein_Fehler" 1 "Fehler" ;
VAL_ 2527679494 LED_L_Autobahnl_Def_4 0 "kein_Fehler" 1 "Fehler" ;
VAL_ 2527679494 LED_L_Autobahnl_Def_5 0 "kein_Fehler" 1 "Fehler" ;
VAL_ 2527679494 LED_L_Autobahnl_Def_6 0 "kein_Fehler" 1 "Fehler" ;
VAL_ 2527679494 LED_L_Autobahnl_Def_7 0 "kein_Fehler" 1 "Fehler" ;
VAL_ 2527679494 LED_L_Autobahnl_Def_Err_Gultig 0 "Fehler_nicht_gueltig" 1 "Fehler_gueltig" ;
VAL_ 2527679494 LED_L_Rennl_Def_1 0 "kein_Fehler" 1 "Fehler" ;
VAL_ 2527679494 LED_L_Rennl_Def_2 0 "kein_Fehler" 1 "Fehler" ;
VAL_ 2527679494 LED_L_Rennl_Def_3 0 "kein_Fehler" 1 "Fehler" ;
VAL_ 2527679494 LED_L_Rennl_Def_4 0 "kein_Fehler" 1 "Fehler" ;
VAL_ 2527679494 LED_L_Rennl_Def_5 0 "kein_Fehler" 1 "Fehler" ;
VAL_ 2527679494 LED_L_Rennl_Def_6 0 "kein_Fehler" 1 "Fehler" ;
VAL_ 2527679494 LED_L_Rennl_Def_7 0 "kein_Fehler" 1 "Fehler" ;
VAL_ 2527679494 LED_L_Rennl_Def_Err_Gultig 0 "Fehler_nicht_gueltig" 1 "Fehler_gueltig" ;
VAL_ 2527679494 LED_L_Stadtl_Def_1 0 "kein_Fehler" 1 "Fehler" ;
VAL_ 2527679494 LED_L_Stadtl_Def_2 0 "kein_Fehler" 1 "Fehler" ;
VAL_ 2527679494 LED_L_Stadtl_Def_3 0 "kein_Fehler" 1 "Fehler" ;
VAL_ 2527679494 LED_L_Stadtl_Def_4 0 "kein_Fehler" 1 "Fehler" ;
VAL_ 2527679494 LED_L_Stadtl_Def_5 0 "kein_Fehler" 1 "Fehler" ;
VAL_ 2527679494 LED_L_Stadtl_Def_6 0 "kein_Fehler" 1 "Fehler" ;
VAL_ 2527679494 LED_L_Stadtl_Def_7 0 "kein_Fehler" 1 "Fehler" ;
VAL_ 2527679494 LED_L_Stadtl_Def_Err_Gultig 0 "Fehler_nicht_gueltig" 1 "Fehler_gueltig" ;
VAL_ 2527679510 LED_L_Abbiegel_Def 0 "Init" ;
VAL_ 2527679510 LED_L_Abblendl_Def 0 "Init" ;
VAL_ 2527679510 LED_L_Allg_Elektr_Def 0 "Init" ;
VAL_ 2527679510 LED_L_Fernl_Def 0 "Init" ;
VAL_ 2527679510 LED_L_Zus_Fernl_LH_Def 0 "iO" 1 "defekt" ;
VAL_ 2527679510 LED_L_Laser_Def 0 "iO" 1 "defekt" ;
VAL_ 1341 LED_R_Abbiegel_Def_1 0 "kein_Fehler" 1 "Fehler" ;
VAL_ 1341 LED_R_Abbiegel_Def_2 0 "kein_Fehler" 1 "Fehler" ;
VAL_ 1341 LED_R_Abbiegel_Def_3 0 "kein_Fehler" 1 "Fehler" ;
VAL_ 1341 LED_R_Abbiegel_Def_4 0 "kein_Fehler" 1 "Fehler" ;
VAL_ 1341 LED_R_Abbiegel_Def_5 0 "kein_Fehler" 1 "Fehler" ;
VAL_ 1341 LED_R_Abbiegel_Def_6 0 "kein_Fehler" 1 "Fehler" ;
VAL_ 1341 LED_R_Abbiegel_Def_7 0 "kein_Fehler" 1 "Fehler" ;
VAL_ 1341 LED_R_Abbiegel_Def_Err_Gultig 0 "Fehler_nicht_gueltig" 1 "Fehler_gueltig" ;
VAL_ 1341 LED_R_Abblendl_Def_1 0 "kein_Fehler" 1 "Fehler" ;
VAL_ 1341 LED_R_Abblendl_Def_2 0 "kein_Fehler" 1 "Fehler" ;
VAL_ 1341 LED_R_Abblendl_Def_3 0 "kein_Fehler" 1 "Fehler" ;
VAL_ 1341 LED_R_Abblendl_Def_4 0 "kein_Fehler" 1 "Fehler" ;
VAL_ 1341 LED_R_Abblendl_Def_5 0 "kein_Fehler" 1 "Fehler" ;
VAL_ 1341 LED_R_Abblendl_Def_6 0 "kein_Fehler" 1 "Fehler" ;
VAL_ 1341 LED_R_Abblendl_Def_7 0 "kein_Fehler" 1 "Fehler" ;
VAL_ 1341 LED_R_Abblendl_Def_Err_Gultig 0 "Fehler_nicht_gueltig" 1 "Fehler_gueltig" ;
VAL_ 1341 LED_R_Fernl_Def_1 0 "kein_Fehler" 1 "Fehler" ;
VAL_ 1341 LED_R_Fernl_Def_2 0 "kein_Fehler" 1 "Fehler" ;
VAL_ 1341 LED_R_Fernl_Def_3 0 "kein_Fehler" 1 "Fehler" ;
VAL_ 1341 LED_R_Fernl_Def_4 0 "kein_Fehler" 1 "Fehler" ;
VAL_ 1341 LED_R_Fernl_Def_5 0 "kein_Fehler" 1 "Fehler" ;
VAL_ 1341 LED_R_Fernl_Def_6 0 "kein_Fehler" 1 "Fehler" ;
VAL_ 1341 LED_R_Fernl_Def_7 0 "kein_Fehler" 1 "Fehler" ;
VAL_ 1341 LED_R_Fernl_Def_Err_Gultig 0 "Fehler_nicht_gueltig" 1 "Fehler_gueltig" ;
VAL_ 1341 LED_R_TFL_Def_1 0 "kein_Fehler" 1 "Fehler" ;
VAL_ 1341 LED_R_TFL_Def_2 0 "kein_Fehler" 1 "Fehler" ;
VAL_ 1341 LED_R_TFL_Def_3 0 "kein_Fehler" 1 "Fehler" ;
VAL_ 1341 LED_R_TFL_Def_4 0 "kein_Fehler" 1 "Fehler" ;
VAL_ 1341 LED_R_TFL_Def_5 0 "kein_Fehler" 1 "Fehler" ;
VAL_ 1341 LED_R_TFL_Def_6 0 "kein_Fehler" 1 "Fehler" ;
VAL_ 1341 LED_R_TFL_Def_7 0 "kein_Fehler" 1 "Fehler" ;
VAL_ 1341 LED_R_TFL_Def_Err_Gultig 0 "Fehler_nicht_gueltig" 1 "Fehler_gueltig" ;
VAL_ 1341 LED_R_Allg_Elektr_Def_1 0 "kein_Fehler" 1 "Fehler" ;
VAL_ 1341 LED_R_Allg_Elektr_Def_2 0 "kein_Fehler" 1 "Fehler" ;
VAL_ 1341 LED_R_Allg_Elektr_Def_3 0 "kein_Fehler" 1 "Fehler" ;
VAL_ 1341 LED_R_Allg_Elektr_Def_4 0 "kein_Fehler" 1 "Fehler" ;
VAL_ 1341 LED_R_Allg_Elektr_Def_5 0 "kein_Fehler" 1 "Fehler" ;
VAL_ 1341 LED_R_Allg_Elektr_Def_6 0 "kein_Fehler" 1 "Fehler" ;
VAL_ 1341 LED_R_Allg_Elektr_Def_7 0 "kein_Fehler" 1 "Fehler" ;
VAL_ 1341 LED_R_Allg_Elektr_Def_8 0 "kein_Fehler" 1 "Fehler" ;
VAL_ 1341 LED_R_Allg_Elektr_Def_Err_Gultig 0 "Fehler_nicht_gueltig" 1 "Fehler_gueltig" ;
VAL_ 1341 LED_R_Luefter_1_Def_1 0 "kein_Fehler" 1 "Fehler" ;
VAL_ 1341 LED_R_Luefter_1_Def_2 0 "kein_Fehler" 1 "Fehler" ;
VAL_ 1341 LED_R_Luefter_1_Def_3 0 "kein_Fehler" 1 "Fehler" ;
VAL_ 1341 LED_R_Luefter_1_Def_4 0 "kein_Fehler" 1 "Fehler" ;
VAL_ 1341 LED_R_Luefter_2_Def_1 0 "kein_Fehler" 1 "Fehler" ;
VAL_ 1341 LED_R_Luefter_2_Def_2 0 "kein_Fehler" 1 "Fehler" ;
VAL_ 1341 LED_R_Luefter_2_Def_3 0 "kein_Fehler" 1 "Fehler" ;
VAL_ 1341 LED_R_Luefter_2_Def_4 0 "kein_Fehler" 1 "Fehler" ;
VAL_ 1341 LED_R_Luefter_1_Def_Err_Gultig 0 "Fehler_nicht_gueltig" 1 "Fehler_gueltig" ;
VAL_ 1341 LED_R_Luefter_2_Def_Err_Gultig 0 "Fehler_nicht_gueltig" 1 "Fehler_gueltig" ;
VAL_ 1341 LED_R_ECE_SAE_Umschaltung_Def 0 "kein_Fehler" 1 "Fehler" ;
VAL_ 2527679495 LED_R_Nebel_All_Def_1 0 "kein_Fehler" 1 "Fehler" ;
VAL_ 2527679495 LED_R_Nebel_All_Def_2 0 "kein_Fehler" 1 "Fehler" ;
VAL_ 2527679495 LED_R_Nebel_All_Def_3 0 "kein_Fehler" 1 "Fehler" ;
VAL_ 2527679495 LED_R_Nebel_All_Def_4 0 "kein_Fehler" 1 "Fehler" ;
VAL_ 2527679495 LED_R_Nebel_All_Def_5 0 "kein_Fehler" 1 "Fehler" ;
VAL_ 2527679495 LED_R_Nebel_All_Def_6 0 "kein_Fehler" 1 "Fehler" ;
VAL_ 2527679495 LED_R_Nebel_All_Def_7 0 "kein_Fehler" 1 "Fehler" ;
VAL_ 2527679495 LED_R_Nebel_All_Def_Err_Gultig 0 "Fehler_nicht_gueltig" 1 "Fehler_gueltig" ;
VAL_ 2527679495 LED_R_Touristenl_Def_1 0 "kein_Fehler" 1 "Fehler" ;
VAL_ 2527679495 LED_R_Touristenl_Def_2 0 "kein_Fehler" 1 "Fehler" ;
VAL_ 2527679495 LED_R_Touristenl_Def_3 0 "kein_Fehler" 1 "Fehler" ;
VAL_ 2527679495 LED_R_Touristenl_Def_4 0 "kein_Fehler" 1 "Fehler" ;
VAL_ 2527679495 LED_R_Touristenl_Def_5 0 "kein_Fehler" 1 "Fehler" ;
VAL_ 2527679495 LED_R_Touristenl_Def_6 0 "kein_Fehler" 1 "Fehler" ;
VAL_ 2527679495 LED_R_Touristenl_Def_7 0 "kein_Fehler" 1 "Fehler" ;
VAL_ 2527679495 LED_R_Touristenl_Def_Err_Gultig 0 "Fehler_nicht_gueltig" 1 "Fehler_gueltig" ;
VAL_ 2527679495 LED_R_Autobahnl_Def_1 0 "kein_Fehler" 1 "Fehler" ;
VAL_ 2527679495 LED_R_Autobahnl_Def_2 0 "kein_Fehler" 1 "Fehler" ;
VAL_ 2527679495 LED_R_Autobahnl_Def_3 0 "kein_Fehler" 1 "Fehler" ;
VAL_ 2527679495 LED_R_Autobahnl_Def_4 0 "kein_Fehler" 1 "Fehler" ;
VAL_ 2527679495 LED_R_Autobahnl_Def_5 0 "kein_Fehler" 1 "Fehler" ;
VAL_ 2527679495 LED_R_Autobahnl_Def_6 0 "kein_Fehler" 1 "Fehler" ;
VAL_ 2527679495 LED_R_Autobahnl_Def_7 0 "kein_Fehler" 1 "Fehler" ;
VAL_ 2527679495 LED_R_Autobahnl_Def_Err_Gultig 0 "Fehler_nicht_gueltig" 1 "Fehler_gueltig" ;
VAL_ 2527679495 LED_R_Rennl_Def_1 0 "kein_Fehler" 1 "Fehler" ;
VAL_ 2527679495 LED_R_Rennl_Def_2 0 "kein_Fehler" 1 "Fehler" ;
VAL_ 2527679495 LED_R_Rennl_Def_3 0 "kein_Fehler" 1 "Fehler" ;
VAL_ 2527679495 LED_R_Rennl_Def_4 0 "kein_Fehler" 1 "Fehler" ;
VAL_ 2527679495 LED_R_Rennl_Def_5 0 "kein_Fehler" 1 "Fehler" ;
VAL_ 2527679495 LED_R_Rennl_Def_6 0 "kein_Fehler" 1 "Fehler" ;
VAL_ 2527679495 LED_R_Rennl_Def_7 0 "kein_Fehler" 1 "Fehler" ;
VAL_ 2527679495 LED_R_Rennl_Def_Err_Gultig 0 "Fehler_nicht_gueltig" 1 "Fehler_gueltig" ;
VAL_ 2527679495 LED_R_Stadtl_Def_1 0 "kein_Fehler" 1 "Fehler" ;
VAL_ 2527679495 LED_R_Stadtl_Def_2 0 "kein_Fehler" 1 "Fehler" ;
VAL_ 2527679495 LED_R_Stadtl_Def_3 0 "kein_Fehler" 1 "Fehler" ;
VAL_ 2527679495 LED_R_Stadtl_Def_4 0 "kein_Fehler" 1 "Fehler" ;
VAL_ 2527679495 LED_R_Stadtl_Def_5 0 "kein_Fehler" 1 "Fehler" ;
VAL_ 2527679495 LED_R_Stadtl_Def_6 0 "kein_Fehler" 1 "Fehler" ;
VAL_ 2527679495 LED_R_Stadtl_Def_7 0 "kein_Fehler" 1 "Fehler" ;
VAL_ 2527679495 LED_R_Stadtl_Def_Err_Gultig 0 "Fehler_nicht_gueltig" 1 "Fehler_gueltig" ;
VAL_ 2527679511 LED_R_Abbiegel_Def 0 "Init" ;
VAL_ 2527679511 LED_R_Abblendl_Def 0 "Init" ;
VAL_ 2527679511 LED_R_Allg_Elektr_Def 0 "Init" ;
VAL_ 2527679511 LED_R_Fernl_Def 0 "Init" ;
VAL_ 2527679511 LED_R_Zus_Fernl_LH_Def 0 "iO" 1 "defekt" ;
VAL_ 2527679511 LED_R_Laser_Def 0 "iO" 1 "defekt" ;
